VERSION "HINBNNNYYNNNYYNNNNNNNNNNNNYNNNYYYNNYNNNNNN/4//%%/4/'%**4NNN///"

NS_ :

BS_:

BU_: VirtualNMTMaster Master LadderDrive ControlPanel SupportFront SupportRear TTGateway

BO_ 1419 SSDO_011: 8 LadderDrive
 SG_ supported_drive_modes_6502 m0 : 32|32@1+ (1,0) [0|4294967295] "" Vector__XXX
 SG_ SubIndex_6502 m25858M : 24|8@1+ (1,0) [0|0] "" Vector__XXX
 SG_ motor_service_period_6407 m0 : 32|32@1+ (1,0) [0|4294967295] "" Vector__XXX
 SG_ SubIndex_6407 m25607M : 24|8@1+ (1,0) [0|0] "" Vector__XXX
 SG_ motor_type_6402 m0 : 32|16@1+ (1,0) [0|65535] "" Vector__XXX
 SG_ SubIndex_6402 m25602M : 24|8@1+ (1,0) [0|0] "" Vector__XXX
 SG_ target_velocity_60FF m0 : 32|32@1- (1,0) [-2147483648|2147483647] "" Vector__XXX
 SG_ SubIndex_60FF m24831M : 24|8@1+ (1,0) [0|0] "" Vector__XXX
 SG_ bitmask_60FE_02 m2 : 32|32@1+ (1,0) [0|4294967295] "" Vector__XXX
 SG_ physical_outputs_60FE_01 m1 : 32|32@1+ (1,0) [0|4294967295] "" Vector__XXX
 SG_ NrOfObjects_60FE_00 m0 : 32|8@1+ (1,0) [0|255] "" Vector__XXX
 SG_ SubIndex_60FE m24830M : 24|8@1+ (1,0) [0|2] "" Vector__XXX
 SG_ digital_inputs_60FD m0 : 32|32@1+ (1,0) [0|4294967295] "" Vector__XXX
 SG_ SubIndex_60FD m24829M : 24|8@1+ (1,0) [0|0] "" Vector__XXX
 SG_ polarity_607E m0 : 32|8@1+ (1,0) [0|255] "" Vector__XXX
 SG_ SubIndex_607E m24702M : 24|8@1+ (1,0) [0|0] "" Vector__XXX
 SG_ target_position_607A m0 : 32|32@1- (1,0) [-2147483648|2147483647] "" Vector__XXX
 SG_ SubIndex_607A m24698M : 24|8@1+ (1,0) [0|0] "" Vector__XXX
 SG_ torque_actual_value_6077 m0 : 32|16@1- (1,0) [-32768|32767] "" Vector__XXX
 SG_ SubIndex_6077 m24695M : 24|8@1+ (1,0) [0|0] "" Vector__XXX
 SG_ target_torque_6071 m0 : 32|16@1- (1,0) [-32768|32767] "" Vector__XXX
 SG_ SubIndex_6071 m24689M : 24|8@1+ (1,0) [0|0] "" Vector__XXX
 SG_ velocity_actual_value_606C m0 : 32|32@1- (1,0) [-2147483648|2147483647] "" Vector__XXX
 SG_ SubIndex_606C m24684M : 24|8@1+ (1,0) [0|0] "" Vector__XXX
 SG_ position_window_6067 m0 : 32|32@1+ (1,0) [0|4294967295] "" Vector__XXX
 SG_ SubIndex_6067 m24679M : 24|8@1+ (1,0) [0|0] "" Vector__XXX
 SG_ position_actual_value_6064 m0 : 32|32@1- (1,0) [-2147483648|2147483647] "" Vector__XXX
 SG_ SubIndex_6064 m24676M : 24|8@1+ (1,0) [0|0] "" Vector__XXX
 SG_ position_actual_value_6063 m0 : 32|32@1- (1,0) [-2147483648|2147483647] "" Vector__XXX
 SG_ SubIndex_6063 m24675M : 24|8@1+ (1,0) [0|0] "" Vector__XXX
 SG_ position_demand_value_6062 m0 : 32|32@1- (1,0) [-2147483648|2147483647] "" Vector__XXX
 SG_ SubIndex_6062 m24674M : 24|8@1+ (1,0) [0|0] "" Vector__XXX
 SG_ modes_of_operation_display_6061 m0 : 32|8@1- (1,0) [-128|127] "" Vector__XXX
 SG_ SubIndex_6061 m24673M : 24|8@1+ (1,0) [0|0] "" Vector__XXX
 SG_ modes_of_operation_6060 m0 : 32|8@1- (1,0) [-128|127] "" Vector__XXX
 SG_ SubIndex_6060 m24672M : 24|8@1+ (1,0) [0|0] "" Vector__XXX
 SG_ fault_reaction_option_code_605E m0 : 32|16@1- (1,0) [-32768|32767] "" Vector__XXX
 SG_ SubIndex_605E m24670M : 24|8@1+ (1,0) [0|0] "" Vector__XXX
 SG_ stop_option_code_605D m0 : 32|16@1- (1,0) [-32768|32767] "" Vector__XXX
 SG_ SubIndex_605D m24669M : 24|8@1+ (1,0) [0|0] "" Vector__XXX
 SG_ disable_operation_option_code_60 m0 : 32|16@1- (1,0) [-32768|32767] "" Vector__XXX
 SG_ SubIndex_605C m24668M : 24|8@1+ (1,0) [0|0] "" Vector__XXX
 SG_ shutdown_option_code_605B m0 : 32|16@1- (1,0) [-32768|32767] "" Vector__XXX
 SG_ SubIndex_605B m24667M : 24|8@1+ (1,0) [0|0] "" Vector__XXX
 SG_ quick_stop_option_code_605A m0 : 32|16@1- (1,0) [-32768|32767] "" Vector__XXX
 SG_ SubIndex_605A m24666M : 24|8@1+ (1,0) [0|0] "" Vector__XXX
 SG_ delta_time_6049_02 m2 : 32|16@1+ (1,0) [0|65535] "" Vector__XXX
 SG_ delta_speed_6049_01 m1 : 32|32@1+ (1,0) [0|4294967295] "" Vector__XXX
 SG_ NrOfObjects_6049_00 m0 : 32|8@1+ (1,0) [0|255] "" Vector__XXX
 SG_ SubIndex_6049 m24649M : 24|8@1+ (1,0) [0|2] "" Vector__XXX
 SG_ delta_time_6048_02 m2 : 32|16@1+ (1,0) [0|65535] "" Vector__XXX
 SG_ delta_speed_6048_01 m1 : 32|32@1+ (1,0) [0|4294967295] "" Vector__XXX
 SG_ NrOfObjects_6048_00 m0 : 32|8@1+ (1,0) [0|255] "" Vector__XXX
 SG_ SubIndex_6048 m24648M : 24|8@1+ (1,0) [0|2] "" Vector__XXX
 SG_ vl_velocity_max_amount_6046_02 m2 : 32|32@1+ (1,0) [0|4294967295] "" Vector__XXX
 SG_ vl_velocity_min_amount_6046_01 m1 : 32|32@1+ (1,0) [0|4294967295] "" Vector__XXX
 SG_ vl_velocity_min_max_amount_highe m0 : 32|8@1+ (1,0) [0|255] "" Vector__XXX
 SG_ SubIndex_6046 m24646M : 24|8@1+ (1,0) [0|2] "" Vector__XXX
 SG_ vl_control_effort_6044 m0 : 32|16@1- (1,0) [-32768|32767] "" Vector__XXX
 SG_ SubIndex_6044 m24644M : 24|8@1+ (1,0) [0|0] "" Vector__XXX
 SG_ vl_velocity_demand_6043 m0 : 32|16@1- (1,0) [-32768|32767] "" Vector__XXX
 SG_ SubIndex_6043 m24643M : 24|8@1+ (1,0) [0|0] "" Vector__XXX
 SG_ vl_target_velocity_6042 m0 : 32|16@1- (1,0) [-32768|32767] "" Vector__XXX
 SG_ SubIndex_6042 m24642M : 24|8@1+ (1,0) [0|0] "" Vector__XXX
 SG_ statusword_6041 m0 : 32|16@1+ (1,0) [0|65535] "" Vector__XXX
 SG_ SubIndex_6041 m24641M : 24|8@1+ (1,0) [0|0] "" Vector__XXX
 SG_ controlword_6040 m0 : 32|16@1+ (1,0) [0|65535] "" Vector__XXX
 SG_ SubIndex_6040 m24640M : 24|8@1+ (1,0) [0|0] "" Vector__XXX
 SG_ error_code_603F m0 : 32|16@1+ (1,0) [0|65535] "" Vector__XXX
 SG_ SubIndex_603F m24639M : 24|8@1+ (1,0) [0|0] "" Vector__XXX
 SG_ abort_connection_option_code_600 m0 : 32|16@1- (1,0) [-32768|3] "" Vector__XXX
 SG_ SubIndex_6007 m24583M : 24|8@1+ (1,0) [0|0] "" Vector__XXX
 SG_ PDO_Mapping_Entry_1A06_08 m8 : 32|32@1+ (1,0) [0|4294967295] "" Vector__XXX
 SG_ PDO_Mapping_Entry_1A06_07 m7 : 32|32@1+ (1,0) [0|4294967295] "" Vector__XXX
 SG_ PDO_Mapping_Entry_1A06_06 m6 : 32|32@1+ (1,0) [0|4294967295] "" Vector__XXX
 SG_ PDO_Mapping_Entry_1A06_05 m5 : 32|32@1+ (1,0) [0|4294967295] "" Vector__XXX
 SG_ PDO_Mapping_Entry_1A06_04 m4 : 32|32@1+ (1,0) [0|4294967295] "" Vector__XXX
 SG_ PDO_Mapping_Entry_1A06_03 m3 : 32|32@1+ (1,0) [0|4294967295] "" Vector__XXX
 SG_ PDO_Mapping_Entry_1A06_02 m2 : 32|32@1+ (1,0) [0|4294967295] "" Vector__XXX
 SG_ PDO_Mapping_Entry_1A06_01 m1 : 32|32@1+ (1,0) [0|4294967295] "" Vector__XXX
 SG_ NrOfMappedObjects_1A06_00 m0 : 32|8@1+ (1,0) [0|8] "" Vector__XXX
 SG_ SubIndex_1A06 m6662M : 24|8@1+ (1,0) [0|8] "" Vector__XXX
 SG_ PDO_Mapping_Entry_1A05_08 m8 : 32|32@1+ (1,0) [0|4294967295] "" Vector__XXX
 SG_ PDO_Mapping_Entry_1A05_07 m7 : 32|32@1+ (1,0) [0|4294967295] "" Vector__XXX
 SG_ PDO_Mapping_Entry_1A05_06 m6 : 32|32@1+ (1,0) [0|4294967295] "" Vector__XXX
 SG_ PDO_Mapping_Entry_1A05_05 m5 : 32|32@1+ (1,0) [0|4294967295] "" Vector__XXX
 SG_ PDO_Mapping_Entry_1A05_04 m4 : 32|32@1+ (1,0) [0|4294967295] "" Vector__XXX
 SG_ PDO_Mapping_Entry_1A05_03 m3 : 32|32@1+ (1,0) [0|4294967295] "" Vector__XXX
 SG_ PDO_Mapping_Entry_1A05_02 m2 : 32|32@1+ (1,0) [0|4294967295] "" Vector__XXX
 SG_ PDO_Mapping_Entry_1A05_01 m1 : 32|32@1+ (1,0) [0|4294967295] "" Vector__XXX
 SG_ NrOfMappedObjects_1A05_00 m0 : 32|8@1+ (1,0) [0|8] "" Vector__XXX
 SG_ SubIndex_1A05 m6661M : 24|8@1+ (1,0) [0|8] "" Vector__XXX
 SG_ PDO_Mapping_Entry_1A04_08 m8 : 32|32@1+ (1,0) [0|4294967295] "" Vector__XXX
 SG_ PDO_Mapping_Entry_1A04_07 m7 : 32|32@1+ (1,0) [0|4294967295] "" Vector__XXX
 SG_ PDO_Mapping_Entry_1A04_06 m6 : 32|32@1+ (1,0) [0|4294967295] "" Vector__XXX
 SG_ PDO_Mapping_Entry_1A04_05 m5 : 32|32@1+ (1,0) [0|4294967295] "" Vector__XXX
 SG_ PDO_Mapping_Entry_1A04_04 m4 : 32|32@1+ (1,0) [0|4294967295] "" Vector__XXX
 SG_ PDO_Mapping_Entry_1A04_03 m3 : 32|32@1+ (1,0) [0|4294967295] "" Vector__XXX
 SG_ PDO_Mapping_Entry_1A04_02 m2 : 32|32@1+ (1,0) [0|4294967295] "" Vector__XXX
 SG_ PDO_Mapping_Entry_1A04_01 m1 : 32|32@1+ (1,0) [0|4294967295] "" Vector__XXX
 SG_ NrOfMappedObjects_1A04_00 m0 : 32|8@1+ (1,0) [0|8] "" Vector__XXX
 SG_ SubIndex_1A04 m6660M : 24|8@1+ (1,0) [0|8] "" Vector__XXX
 SG_ PDO_Mapping_Entry_1A03_08 m8 : 32|32@1+ (1,0) [0|4294967295] "" Vector__XXX
 SG_ PDO_Mapping_Entry_1A03_07 m7 : 32|32@1+ (1,0) [0|4294967295] "" Vector__XXX
 SG_ PDO_Mapping_Entry_1A03_06 m6 : 32|32@1+ (1,0) [0|4294967295] "" Vector__XXX
 SG_ PDO_Mapping_Entry_1A03_05 m5 : 32|32@1+ (1,0) [0|4294967295] "" Vector__XXX
 SG_ PDO_Mapping_Entry_1A03_04 m4 : 32|32@1+ (1,0) [0|4294967295] "" Vector__XXX
 SG_ PDO_Mapping_Entry_1A03_03 m3 : 32|32@1+ (1,0) [0|4294967295] "" Vector__XXX
 SG_ PDO_Mapping_Entry_1A03_02 m2 : 32|32@1+ (1,0) [0|4294967295] "" Vector__XXX
 SG_ PDO_Mapping_Entry_1A03_01 m1 : 32|32@1+ (1,0) [0|4294967295] "" Vector__XXX
 SG_ NrOfMappedObjects_1A03_00 m0 : 32|8@1+ (1,0) [0|8] "" Vector__XXX
 SG_ SubIndex_1A03 m6659M : 24|8@1+ (1,0) [0|8] "" Vector__XXX
 SG_ PDO_Mapping_Entry_1A02_08 m8 : 32|32@1+ (1,0) [0|4294967295] "" Vector__XXX
 SG_ PDO_Mapping_Entry_1A02_07 m7 : 32|32@1+ (1,0) [0|4294967295] "" Vector__XXX
 SG_ PDO_Mapping_Entry_1A02_06 m6 : 32|32@1+ (1,0) [0|4294967295] "" Vector__XXX
 SG_ PDO_Mapping_Entry_1A02_05 m5 : 32|32@1+ (1,0) [0|4294967295] "" Vector__XXX
 SG_ PDO_Mapping_Entry_1A02_04 m4 : 32|32@1+ (1,0) [0|4294967295] "" Vector__XXX
 SG_ PDO_Mapping_Entry_1A02_03 m3 : 32|32@1+ (1,0) [0|4294967295] "" Vector__XXX
 SG_ PDO_Mapping_Entry_1A02_02 m2 : 32|32@1+ (1,0) [0|4294967295] "" Vector__XXX
 SG_ PDO_Mapping_Entry_1A02_01 m1 : 32|32@1+ (1,0) [0|4294967295] "" Vector__XXX
 SG_ NrOfMappedObjects_1A02_00 m0 : 32|8@1+ (1,0) [0|8] "" Vector__XXX
 SG_ SubIndex_1A02 m6658M : 24|8@1+ (1,0) [0|8] "" Vector__XXX
 SG_ PDO_Mapping_Entry_1A01_08 m8 : 32|32@1+ (1,0) [0|4294967295] "" Vector__XXX
 SG_ PDO_Mapping_Entry_1A01_07 m7 : 32|32@1+ (1,0) [0|4294967295] "" Vector__XXX
 SG_ PDO_Mapping_Entry_1A01_06 m6 : 32|32@1+ (1,0) [0|4294967295] "" Vector__XXX
 SG_ PDO_Mapping_Entry_1A01_05 m5 : 32|32@1+ (1,0) [0|4294967295] "" Vector__XXX
 SG_ PDO_Mapping_Entry_1A01_04 m4 : 32|32@1+ (1,0) [0|4294967295] "" Vector__XXX
 SG_ PDO_Mapping_Entry_1A01_03 m3 : 32|32@1+ (1,0) [0|4294967295] "" Vector__XXX
 SG_ PDO_Mapping_Entry_1A01_02 m2 : 32|32@1+ (1,0) [0|4294967295] "" Vector__XXX
 SG_ PDO_Mapping_Entry_1A01_01 m1 : 32|32@1+ (1,0) [0|4294967295] "" Vector__XXX
 SG_ NrOfMappedObjects_1A01_00 m0 : 32|8@1+ (1,0) [0|8] "" Vector__XXX
 SG_ SubIndex_1A01 m6657M : 24|8@1+ (1,0) [0|8] "" Vector__XXX
 SG_ PDO_Mapping_Entry_1A00_08 m8 : 32|32@1+ (1,0) [0|4294967295] "" Vector__XXX
 SG_ PDO_Mapping_Entry_1A00_07 m7 : 32|32@1+ (1,0) [0|4294967295] "" Vector__XXX
 SG_ PDO_Mapping_Entry_1A00_06 m6 : 32|32@1+ (1,0) [0|4294967295] "" Vector__XXX
 SG_ PDO_Mapping_Entry_1A00_05 m5 : 32|32@1+ (1,0) [0|4294967295] "" Vector__XXX
 SG_ PDO_Mapping_Entry_1A00_04 m4 : 32|32@1+ (1,0) [0|4294967295] "" Vector__XXX
 SG_ PDO_Mapping_Entry_1A00_03 m3 : 32|32@1+ (1,0) [0|4294967295] "" Vector__XXX
 SG_ PDO_Mapping_Entry_1A00_02 m2 : 32|32@1+ (1,0) [0|4294967295] "" Vector__XXX
 SG_ mappedObj1_1A00_01 m1 : 32|32@1+ (1,0) [0|4294967295] "" Vector__XXX
 SG_ NrOfMappedObjects_1A00_00 m0 : 32|8@1+ (1,0) [0|8] "" Vector__XXX
 SG_ SubIndex_1A00 m6656M : 24|8@1+ (1,0) [0|8] "" Vector__XXX
 SG_ EventTimer_1806_05 m5 : 32|16@1+ (1,0) [0|65535] "" Vector__XXX
 SG_ TransmissionType_1806_02 m2 : 32|8@1+ (1,0) [0|255] "" Vector__XXX
 SG_ COB_ID_1806_01 m1 : 32|32@1+ (1,0) [128|4294967295] "" Vector__XXX
 SG_ NrOfEntries_1806_00 m0 : 32|8@1+ (1,0) [2|5] "" Vector__XXX
 SG_ SubIndex_1806 m6150M : 24|8@1+ (1,0) [0|5] "" Vector__XXX
 SG_ EventTimer_1805_05 m5 : 32|16@1+ (1,0) [0|65535] "" Vector__XXX
 SG_ TransmissionType_1805_02 m2 : 32|8@1+ (1,0) [0|255] "" Vector__XXX
 SG_ COB_ID_1805_01 m1 : 32|32@1+ (1,0) [128|4294967295] "" Vector__XXX
 SG_ NrOfEntries_1805_00 m0 : 32|8@1+ (1,0) [2|5] "" Vector__XXX
 SG_ SubIndex_1805 m6149M : 24|8@1+ (1,0) [0|5] "" Vector__XXX
 SG_ EventTimer_1804_05 m5 : 32|16@1+ (1,0) [0|65535] "" Vector__XXX
 SG_ TransmissionType_1804_02 m2 : 32|8@1+ (1,0) [0|255] "" Vector__XXX
 SG_ COB_ID_1804_01 m1 : 32|32@1+ (1,0) [128|4294967295] "" Vector__XXX
 SG_ NrOfEntries_1804_00 m0 : 32|8@1+ (1,0) [2|5] "" Vector__XXX
 SG_ SubIndex_1804 m6148M : 24|8@1+ (1,0) [0|5] "" Vector__XXX
 SG_ EventTimer_1803_05 m5 : 32|16@1+ (1,0) [0|65535] "" Vector__XXX
 SG_ TransmissionType_1803_02 m2 : 32|8@1+ (1,0) [0|255] "" Vector__XXX
 SG_ COB_ID_1803_01 m1 : 32|32@1+ (1,0) [128|4294967295] "" Vector__XXX
 SG_ NrOfEntries_1803_00 m0 : 32|8@1+ (1,0) [2|5] "" Vector__XXX
 SG_ SubIndex_1803 m6147M : 24|8@1+ (1,0) [0|5] "" Vector__XXX
 SG_ EventTimer_1802_05 m5 : 32|16@1+ (1,0) [0|65535] "" Vector__XXX
 SG_ TransmissionType_1802_02 m2 : 32|8@1+ (1,0) [0|255] "" Vector__XXX
 SG_ COB_ID_1802_01 m1 : 32|32@1+ (1,0) [128|4294967295] "" Vector__XXX
 SG_ NrOfEntries_1802_00 m0 : 32|8@1+ (1,0) [2|5] "" Vector__XXX
 SG_ SubIndex_1802 m6146M : 24|8@1+ (1,0) [0|5] "" Vector__XXX
 SG_ EventTimer_1801_05 m5 : 32|16@1+ (1,0) [0|65535] "" Vector__XXX
 SG_ TransmissionType_1801_02 m2 : 32|8@1+ (1,0) [0|255] "" Vector__XXX
 SG_ COB_ID_1801_01 m1 : 32|32@1+ (1,0) [128|4294967295] "" Vector__XXX
 SG_ NrOfEntries_1801_00 m0 : 32|8@1+ (1,0) [2|5] "" Vector__XXX
 SG_ SubIndex_1801 m6145M : 24|8@1+ (1,0) [0|5] "" Vector__XXX
 SG_ EventTimer_1800_05 m5 : 32|16@1+ (1,0) [0|65535] "" Vector__XXX
 SG_ TransmissionType_1800_02 m2 : 32|8@1+ (1,0) [0|255] "" Vector__XXX
 SG_ COB_ID_1800_01 m1 : 32|32@1+ (1,0) [128|4294967295] "" Vector__XXX
 SG_ NrOfEntries_1800_00 m0 : 32|8@1+ (1,0) [2|5] "" Vector__XXX
 SG_ SubIndex_1800 m6144M : 24|8@1+ (1,0) [0|5] "" Vector__XXX
 SG_ PDO_Mapping_Entry_1607_08 m8 : 32|32@1+ (1,0) [0|4294967295] "" Vector__XXX
 SG_ PDO_Mapping_Entry_1607_07 m7 : 32|32@1+ (1,0) [0|4294967295] "" Vector__XXX
 SG_ PDO_Mapping_Entry_1607_06 m6 : 32|32@1+ (1,0) [0|4294967295] "" Vector__XXX
 SG_ PDO_Mapping_Entry_1607_05 m5 : 32|32@1+ (1,0) [0|4294967295] "" Vector__XXX
 SG_ PDO_Mapping_Entry_1607_04 m4 : 32|32@1+ (1,0) [0|4294967295] "" Vector__XXX
 SG_ PDO_Mapping_Entry_1607_03 m3 : 32|32@1+ (1,0) [0|4294967295] "" Vector__XXX
 SG_ PDO_Mapping_Entry_1607_02 m2 : 32|32@1+ (1,0) [0|4294967295] "" Vector__XXX
 SG_ PDO_Mapping_Entry_1607_01 m1 : 32|32@1+ (1,0) [0|4294967295] "" Vector__XXX
 SG_ NrOfMappedObjects_1607_00 m0 : 32|8@1+ (1,0) [0|8] "" Vector__XXX
 SG_ SubIndex_1607 m5639M : 24|8@1+ (1,0) [0|8] "" Vector__XXX
 SG_ PDO_Mapping_Entry_1606_08 m8 : 32|32@1+ (1,0) [0|4294967295] "" Vector__XXX
 SG_ PDO_Mapping_Entry_1606_07 m7 : 32|32@1+ (1,0) [0|4294967295] "" Vector__XXX
 SG_ PDO_Mapping_Entry_1606_06 m6 : 32|32@1+ (1,0) [0|4294967295] "" Vector__XXX
 SG_ PDO_Mapping_Entry_1606_05 m5 : 32|32@1+ (1,0) [0|4294967295] "" Vector__XXX
 SG_ PDO_Mapping_Entry_1606_04 m4 : 32|32@1+ (1,0) [0|4294967295] "" Vector__XXX
 SG_ PDO_Mapping_Entry_1606_03 m3 : 32|32@1+ (1,0) [0|4294967295] "" Vector__XXX
 SG_ PDO_Mapping_Entry_1606_02 m2 : 32|32@1+ (1,0) [0|4294967295] "" Vector__XXX
 SG_ PDO_Mapping_Entry_1606_01 m1 : 32|32@1+ (1,0) [0|4294967295] "" Vector__XXX
 SG_ NrOfMappedObjects_1606_00 m0 : 32|8@1+ (1,0) [0|8] "" Vector__XXX
 SG_ SubIndex_1606 m5638M : 24|8@1+ (1,0) [0|8] "" Vector__XXX
 SG_ PDO_Mapping_Entry_1605_08 m8 : 32|32@1+ (1,0) [0|4294967295] "" Vector__XXX
 SG_ PDO_Mapping_Entry_1605_07 m7 : 32|32@1+ (1,0) [0|4294967295] "" Vector__XXX
 SG_ PDO_Mapping_Entry_1605_06 m6 : 32|32@1+ (1,0) [0|4294967295] "" Vector__XXX
 SG_ PDO_Mapping_Entry_1605_05 m5 : 32|32@1+ (1,0) [0|4294967295] "" Vector__XXX
 SG_ PDO_Mapping_Entry_1605_04 m4 : 32|32@1+ (1,0) [0|4294967295] "" Vector__XXX
 SG_ PDO_Mapping_Entry_1605_03 m3 : 32|32@1+ (1,0) [0|4294967295] "" Vector__XXX
 SG_ PDO_Mapping_Entry_1605_02 m2 : 32|32@1+ (1,0) [0|4294967295] "" Vector__XXX
 SG_ PDO_Mapping_Entry_1605_01 m1 : 32|32@1+ (1,0) [0|4294967295] "" Vector__XXX
 SG_ NrOfMappedObjects_1605_00 m0 : 32|8@1+ (1,0) [0|8] "" Vector__XXX
 SG_ SubIndex_1605 m5637M : 24|8@1+ (1,0) [0|8] "" Vector__XXX
 SG_ PDO_Mapping_Entry_1604_08 m8 : 32|32@1+ (1,0) [0|4294967295] "" Vector__XXX
 SG_ PDO_Mapping_Entry_1604_07 m7 : 32|32@1+ (1,0) [0|4294967295] "" Vector__XXX
 SG_ PDO_Mapping_Entry_1604_06 m6 : 32|32@1+ (1,0) [0|4294967295] "" Vector__XXX
 SG_ PDO_Mapping_Entry_1604_05 m5 : 32|32@1+ (1,0) [0|4294967295] "" Vector__XXX
 SG_ PDO_Mapping_Entry_1604_04 m4 : 32|32@1+ (1,0) [0|4294967295] "" Vector__XXX
 SG_ PDO_Mapping_Entry_1604_03 m3 : 32|32@1+ (1,0) [0|4294967295] "" Vector__XXX
 SG_ PDO_Mapping_Entry_1604_02 m2 : 32|32@1+ (1,0) [0|4294967295] "" Vector__XXX
 SG_ PDO_Mapping_Entry_1604_01 m1 : 32|32@1+ (1,0) [0|4294967295] "" Vector__XXX
 SG_ NrOfMappedObjects_1604_00 m0 : 32|8@1+ (1,0) [0|8] "" Vector__XXX
 SG_ SubIndex_1604 m5636M : 24|8@1+ (1,0) [0|8] "" Vector__XXX
 SG_ PDO_Mapping_Entry_1603_08 m8 : 32|32@1+ (1,0) [0|4294967295] "" Vector__XXX
 SG_ PDO_Mapping_Entry_1603_07 m7 : 32|32@1+ (1,0) [0|4294967295] "" Vector__XXX
 SG_ PDO_Mapping_Entry_1603_06 m6 : 32|32@1+ (1,0) [0|4294967295] "" Vector__XXX
 SG_ PDO_Mapping_Entry_1603_05 m5 : 32|32@1+ (1,0) [0|4294967295] "" Vector__XXX
 SG_ PDO_Mapping_Entry_1603_04 m4 : 32|32@1+ (1,0) [0|4294967295] "" Vector__XXX
 SG_ PDO_Mapping_Entry_1603_03 m3 : 32|32@1+ (1,0) [0|4294967295] "" Vector__XXX
 SG_ PDO_Mapping_Entry_1603_02 m2 : 32|32@1+ (1,0) [0|4294967295] "" Vector__XXX
 SG_ PDO_Mapping_Entry_1603_01 m1 : 32|32@1+ (1,0) [0|4294967295] "" Vector__XXX
 SG_ NrOfMappedObjects_1603_00 m0 : 32|8@1+ (1,0) [0|8] "" Vector__XXX
 SG_ SubIndex_1603 m5635M : 24|8@1+ (1,0) [0|8] "" Vector__XXX
 SG_ PDO_Mapping_Entry_1602_08 m8 : 32|32@1+ (1,0) [0|4294967295] "" Vector__XXX
 SG_ PDO_Mapping_Entry_1602_07 m7 : 32|32@1+ (1,0) [0|4294967295] "" Vector__XXX
 SG_ PDO_Mapping_Entry_1602_06 m6 : 32|32@1+ (1,0) [0|4294967295] "" Vector__XXX
 SG_ PDO_Mapping_Entry_1602_05 m5 : 32|32@1+ (1,0) [0|4294967295] "" Vector__XXX
 SG_ PDO_Mapping_Entry_1602_04 m4 : 32|32@1+ (1,0) [0|4294967295] "" Vector__XXX
 SG_ PDO_Mapping_Entry_1602_03 m3 : 32|32@1+ (1,0) [0|4294967295] "" Vector__XXX
 SG_ PDO_Mapping_Entry_1602_02 m2 : 32|32@1+ (1,0) [0|4294967295] "" Vector__XXX
 SG_ PDO_Mapping_Entry_1602_01 m1 : 32|32@1+ (1,0) [0|4294967295] "" Vector__XXX
 SG_ NrOfMappedObjects_1602_00 m0 : 32|8@1+ (1,0) [0|8] "" Vector__XXX
 SG_ SubIndex_1602 m5634M : 24|8@1+ (1,0) [0|8] "" Vector__XXX
 SG_ PDO_Mapping_Entry_1601_08 m8 : 32|32@1+ (1,0) [0|4294967295] "" Vector__XXX
 SG_ PDO_Mapping_Entry_1601_07 m7 : 32|32@1+ (1,0) [0|4294967295] "" Vector__XXX
 SG_ PDO_Mapping_Entry_1601_06 m6 : 32|32@1+ (1,0) [0|4294967295] "" Vector__XXX
 SG_ PDO_Mapping_Entry_1601_05 m5 : 32|32@1+ (1,0) [0|4294967295] "" Vector__XXX
 SG_ PDO_Mapping_Entry_1601_04 m4 : 32|32@1+ (1,0) [0|4294967295] "" Vector__XXX
 SG_ PDO_Mapping_Entry_1601_03 m3 : 32|32@1+ (1,0) [0|4294967295] "" Vector__XXX
 SG_ PDO_Mapping_Entry_1601_02 m2 : 32|32@1+ (1,0) [0|4294967295] "" Vector__XXX
 SG_ PDO_Mapping_Entry_1601_01 m1 : 32|32@1+ (1,0) [0|4294967295] "" Vector__XXX
 SG_ NrOfMappedObjects_1601_00 m0 : 32|8@1+ (1,0) [0|8] "" Vector__XXX
 SG_ SubIndex_1601 m5633M : 24|8@1+ (1,0) [0|8] "" Vector__XXX
 SG_ PDO_Mapping_Entry_1600_08 m8 : 32|32@1+ (1,0) [0|4294967295] "" Vector__XXX
 SG_ PDO_Mapping_Entry_1600_07 m7 : 32|32@1+ (1,0) [0|4294967295] "" Vector__XXX
 SG_ PDO_Mapping_Entry_1600_06 m6 : 32|32@1+ (1,0) [0|4294967295] "" Vector__XXX
 SG_ PDO_Mapping_Entry_1600_05 m5 : 32|32@1+ (1,0) [0|4294967295] "" Vector__XXX
 SG_ PDO_Mapping_Entry_1600_04 m4 : 32|32@1+ (1,0) [0|4294967295] "" Vector__XXX
 SG_ PDO_Mapping_Entry_1600_03 m3 : 32|32@1+ (1,0) [0|4294967295] "" Vector__XXX
 SG_ mappedObj2_1600_02 m2 : 32|32@1+ (1,0) [0|4294967295] "" Vector__XXX
 SG_ mappedObj1_1600_01 m1 : 32|32@1+ (1,0) [0|4294967295] "" Vector__XXX
 SG_ NrOfMappedObjects_1600_00 m0 : 32|8@1+ (1,0) [0|8] "" Vector__XXX
 SG_ SubIndex_1600 m5632M : 24|8@1+ (1,0) [0|8] "" Vector__XXX
 SG_ TransmissionType_1407_02 m2 : 32|8@1+ (1,0) [0|255] "" Vector__XXX
 SG_ COB_ID_1407_01 m1 : 32|32@1+ (1,0) [128|4294967295] "" Vector__XXX
 SG_ NrOfEntries_1407_00 m0 : 32|8@1+ (1,0) [2|5] "" Vector__XXX
 SG_ SubIndex_1407 m5127M : 24|8@1+ (1,0) [0|2] "" Vector__XXX
 SG_ TransmissionType_1406_02 m2 : 32|8@1+ (1,0) [0|255] "" Vector__XXX
 SG_ COB_ID_1406_01 m1 : 32|32@1+ (1,0) [128|4294967295] "" Vector__XXX
 SG_ NrOfEntries_1406_00 m0 : 32|8@1+ (1,0) [2|5] "" Vector__XXX
 SG_ SubIndex_1406 m5126M : 24|8@1+ (1,0) [0|2] "" Vector__XXX
 SG_ TransmissionType_1405_02 m2 : 32|8@1+ (1,0) [0|255] "" Vector__XXX
 SG_ COB_ID_1405_01 m1 : 32|32@1+ (1,0) [128|4294967295] "" Vector__XXX
 SG_ NrOfEntries_1405_00 m0 : 32|8@1+ (1,0) [2|5] "" Vector__XXX
 SG_ SubIndex_1405 m5125M : 24|8@1+ (1,0) [0|2] "" Vector__XXX
 SG_ TransmissionType_1404_02 m2 : 32|8@1+ (1,0) [0|255] "" Vector__XXX
 SG_ COB_ID_1404_01 m1 : 32|32@1+ (1,0) [128|4294967295] "" Vector__XXX
 SG_ NrOfEntries_1404_00 m0 : 32|8@1+ (1,0) [2|5] "" Vector__XXX
 SG_ SubIndex_1404 m5124M : 24|8@1+ (1,0) [0|2] "" Vector__XXX
 SG_ TransmissionType_1403_02 m2 : 32|8@1+ (1,0) [0|255] "" Vector__XXX
 SG_ COB_ID_1403_01 m1 : 32|32@1+ (1,0) [128|4294967295] "" Vector__XXX
 SG_ NrOfEntries_1403_00 m0 : 32|8@1+ (1,0) [2|5] "" Vector__XXX
 SG_ SubIndex_1403 m5123M : 24|8@1+ (1,0) [0|2] "" Vector__XXX
 SG_ TransmissionType_1402_02 m2 : 32|8@1+ (1,0) [0|255] "" Vector__XXX
 SG_ COB_ID_1402_01 m1 : 32|32@1+ (1,0) [128|4294967295] "" Vector__XXX
 SG_ NrOfEntries_1402_00 m0 : 32|8@1+ (1,0) [2|5] "" Vector__XXX
 SG_ SubIndex_1402 m5122M : 24|8@1+ (1,0) [0|2] "" Vector__XXX
 SG_ TransmissionType_1401_02 m2 : 32|8@1+ (1,0) [0|255] "" Vector__XXX
 SG_ COB_ID_1401_01 m1 : 32|32@1+ (1,0) [128|4294967295] "" Vector__XXX
 SG_ NrOfEntries_1401_00 m0 : 32|8@1+ (1,0) [2|5] "" Vector__XXX
 SG_ SubIndex_1401 m5121M : 24|8@1+ (1,0) [0|2] "" Vector__XXX
 SG_ TransmissionType_1400_02 m2 : 32|8@1+ (1,0) [0|255] "" Vector__XXX
 SG_ COB_ID_1400_01 m1 : 32|32@1+ (1,0) [128|4294967295] "" Vector__XXX
 SG_ NrOfEntries_1400_00 m0 : 32|8@1+ (1,0) [2|5] "" Vector__XXX
 SG_ SubIndex_1400 m5120M : 24|8@1+ (1,0) [0|2] "" Vector__XXX
 SG_ Serial_number_1018_04 m4 : 32|32@1+ (1,0) [0|4294967295] "" Vector__XXX
 SG_ Revision_number_1018_03 m3 : 32|32@1+ (1,0) [0|4294967295] "" Vector__XXX
 SG_ Product_Code_1018_02 m2 : 32|32@1+ (1,0) [0|4294967295] "" Vector__XXX
 SG_ Vendor_Id_1018_01 m1 : 32|32@1+ (1,0) [0|4294967295] "" Vector__XXX
 SG_ number_of_entries_1018_00 m0 : 32|8@1+ (1,0) [1|4] "" Vector__XXX
 SG_ SubIndex_1018 m4120M : 24|8@1+ (1,0) [0|4] "" Vector__XXX
 SG_ Producer_Heartbeat_Time_1017 m0 : 32|16@1+ (1,0) [0|65535] "" Vector__XXX
 SG_ SubIndex_1017 m4119M : 24|8@1+ (1,0) [0|0] "" Vector__XXX
 SG_ Consumer_Heartbeat_Time_1016_09 m9 : 32|32@1+ (1,0) [0|4294967295] "" Vector__XXX
 SG_ Consumer_Heartbeat_Time_1016_08 m8 : 32|32@1+ (1,0) [0|4294967295] "" Vector__XXX
 SG_ Consumer_Heartbeat_Time_1016_07 m7 : 32|32@1+ (1,0) [0|4294967295] "" Vector__XXX
 SG_ Consumer_Heartbeat_Time_1016_06 m6 : 32|32@1+ (1,0) [0|4294967295] "" Vector__XXX
 SG_ Consumer_Heartbeat_Time_1016_05 m5 : 32|32@1+ (1,0) [0|4294967295] "" Vector__XXX
 SG_ Consumer_Heartbeat_Time_1016_04 m4 : 32|32@1+ (1,0) [0|4294967295] "" Vector__XXX
 SG_ Consumer_Heartbeat_Time_1016_03 m3 : 32|32@1+ (1,0) [0|4294967295] "" Vector__XXX
 SG_ Consumer_Heartbeat_Time_1016_02 m2 : 32|32@1+ (1,0) [0|4294967295] "" Vector__XXX
 SG_ Consumer_Heartbeat_Time_1016_01 m1 : 32|32@1+ (1,0) [0|4294967295] "" Vector__XXX
 SG_ NrOfObjects_1016_00 m0 : 32|8@1+ (1,0) [0|255] "" Vector__XXX
 SG_ SubIndex_1016 m4118M : 24|8@1+ (1,0) [0|9] "" Vector__XXX
 SG_ Save_all_Parameters_1010_01 m1 : 32|32@1+ (1,0) [0|4294967295] "" Vector__XXX
 SG_ Number_of_Entries_1010_00 m0 : 32|8@1+ (1,0) [0|255] "" Vector__XXX
 SG_ SubIndex_1010 m4112M : 24|8@1+ (1,0) [0|1] "" Vector__XXX
 SG_ Life_Time_Factor_100D m0 : 32|8@1+ (1,0) [0|255] "" Vector__XXX
 SG_ SubIndex_100D m4109M : 24|8@1+ (1,0) [0|0] "" Vector__XXX
 SG_ Guard_Time_100C m0 : 32|16@1+ (1,0) [0|65535] "" Vector__XXX
 SG_ SubIndex_100C m4108M : 24|8@1+ (1,0) [0|0] "" Vector__XXX
 SG_ Sync_Window_Length_1007 m0 : 32|32@1+ (1,0) [0|4294967295] "" Vector__XXX
 SG_ SubIndex_1007 m4103M : 24|8@1+ (1,0) [0|0] "" Vector__XXX
 SG_ Communication_Cycle_Period_1006 m0 : 32|32@1+ (1,0) [0|4294967295] "" Vector__XXX
 SG_ SubIndex_1006 m4102M : 24|8@1+ (1,0) [0|0] "" Vector__XXX
 SG_ COB_ID_SYNC_1005 m0 : 32|32@1+ (1,0) [128|4294967295] "" Vector__XXX
 SG_ SubIndex_1005 m4101M : 24|8@1+ (1,0) [0|0] "" Vector__XXX
 SG_ Manufacturer_Status_Registe_0001 m0 : 32|32@1+ (1,0) [0|4294967295] "" Vector__XXX
 SG_ SubIndex_1002 m4098M : 24|8@1+ (1,0) [0|0] "" Vector__XXX
 SG_ Error_Register_1001 m0 : 32|8@1+ (1,0) [0|255] "" Vector__XXX
 SG_ SubIndex_1001 m4097M : 24|8@1+ (1,0) [0|0] "" Vector__XXX
 SG_ Device_Type_1000 m0 : 32|32@1+ (1,0) [0|4294967295] "" Vector__XXX
 SG_ SubIndex_1000 m4096M : 24|8@1+ (1,0) [0|0] "" Vector__XXX
 SG_ Index m1M : 8|16@1+ (1,0) [4096|25861] "" Vector__XXX
 SG_ TransferType m1M : 1|1@1+ (1,0) [0|1] "" Vector__XXX
 SG_ NotUsedBytes m1 : 2|2@1+ (1,0) [0|3] "" Vector__XXX
 SG_ SizeIndicator m1 : 0|1@1+ (1,0) [0|1] "" Vector__XXX
 SG_ SCS M : 5|3@1+ (1,0) [0|6] "" Vector__XXX

BO_ 1547 CSDO_011: 8 Vector__XXX
 SG_ supported_drive_modes_6502 m0 : 32|32@1+ (1,0) [0|4294967295] ""  LadderDrive
 SG_ SubIndex_6502 m25858M : 24|8@1+ (1,0) [0|0] ""  LadderDrive
 SG_ motor_service_period_6407 m0 : 32|32@1+ (1,0) [0|4294967295] ""  LadderDrive
 SG_ SubIndex_6407 m25607M : 24|8@1+ (1,0) [0|0] ""  LadderDrive
 SG_ motor_type_6402 m0 : 32|16@1+ (1,0) [0|65535] ""  LadderDrive
 SG_ SubIndex_6402 m25602M : 24|8@1+ (1,0) [0|0] ""  LadderDrive
 SG_ target_velocity_60FF m0 : 32|32@1- (1,0) [-2147483648|2147483647] ""  LadderDrive
 SG_ SubIndex_60FF m24831M : 24|8@1+ (1,0) [0|0] ""  LadderDrive
 SG_ bitmask_60FE_02 m2 : 32|32@1+ (1,0) [0|4294967295] ""  LadderDrive
 SG_ physical_outputs_60FE_01 m1 : 32|32@1+ (1,0) [0|4294967295] ""  LadderDrive
 SG_ NrOfObjects_60FE_00 m0 : 32|8@1+ (1,0) [0|255] ""  LadderDrive
 SG_ SubIndex_60FE m24830M : 24|8@1+ (1,0) [0|2] ""  LadderDrive
 SG_ digital_inputs_60FD m0 : 32|32@1+ (1,0) [0|4294967295] ""  LadderDrive
 SG_ SubIndex_60FD m24829M : 24|8@1+ (1,0) [0|0] ""  LadderDrive
 SG_ polarity_607E m0 : 32|8@1+ (1,0) [0|255] ""  LadderDrive
 SG_ SubIndex_607E m24702M : 24|8@1+ (1,0) [0|0] ""  LadderDrive
 SG_ target_position_607A m0 : 32|32@1- (1,0) [-2147483648|2147483647] ""  LadderDrive
 SG_ SubIndex_607A m24698M : 24|8@1+ (1,0) [0|0] ""  LadderDrive
 SG_ torque_actual_value_6077 m0 : 32|16@1- (1,0) [-32768|32767] ""  LadderDrive
 SG_ SubIndex_6077 m24695M : 24|8@1+ (1,0) [0|0] ""  LadderDrive
 SG_ target_torque_6071 m0 : 32|16@1- (1,0) [-32768|32767] ""  LadderDrive
 SG_ SubIndex_6071 m24689M : 24|8@1+ (1,0) [0|0] ""  LadderDrive
 SG_ velocity_actual_value_606C m0 : 32|32@1- (1,0) [-2147483648|2147483647] ""  LadderDrive
 SG_ SubIndex_606C m24684M : 24|8@1+ (1,0) [0|0] ""  LadderDrive
 SG_ position_window_6067 m0 : 32|32@1+ (1,0) [0|4294967295] ""  LadderDrive
 SG_ SubIndex_6067 m24679M : 24|8@1+ (1,0) [0|0] ""  LadderDrive
 SG_ position_actual_value_6064 m0 : 32|32@1- (1,0) [-2147483648|2147483647] ""  LadderDrive
 SG_ SubIndex_6064 m24676M : 24|8@1+ (1,0) [0|0] ""  LadderDrive
 SG_ position_actual_value_6063 m0 : 32|32@1- (1,0) [-2147483648|2147483647] ""  LadderDrive
 SG_ SubIndex_6063 m24675M : 24|8@1+ (1,0) [0|0] ""  LadderDrive
 SG_ position_demand_value_6062 m0 : 32|32@1- (1,0) [-2147483648|2147483647] ""  LadderDrive
 SG_ SubIndex_6062 m24674M : 24|8@1+ (1,0) [0|0] ""  LadderDrive
 SG_ modes_of_operation_display_6061 m0 : 32|8@1- (1,0) [-128|127] ""  LadderDrive
 SG_ SubIndex_6061 m24673M : 24|8@1+ (1,0) [0|0] ""  LadderDrive
 SG_ modes_of_operation_6060 m0 : 32|8@1- (1,0) [-128|127] ""  LadderDrive
 SG_ SubIndex_6060 m24672M : 24|8@1+ (1,0) [0|0] ""  LadderDrive
 SG_ fault_reaction_option_code_605E m0 : 32|16@1- (1,0) [-32768|32767] ""  LadderDrive
 SG_ SubIndex_605E m24670M : 24|8@1+ (1,0) [0|0] ""  LadderDrive
 SG_ stop_option_code_605D m0 : 32|16@1- (1,0) [-32768|32767] ""  LadderDrive
 SG_ SubIndex_605D m24669M : 24|8@1+ (1,0) [0|0] ""  LadderDrive
 SG_ disable_operation_option_co_0000 m0 : 32|16@1- (1,0) [-32768|32767] ""  LadderDrive
 SG_ SubIndex_605C m24668M : 24|8@1+ (1,0) [0|0] ""  LadderDrive
 SG_ shutdown_option_code_605B m0 : 32|16@1- (1,0) [-32768|32767] ""  LadderDrive
 SG_ SubIndex_605B m24667M : 24|8@1+ (1,0) [0|0] ""  LadderDrive
 SG_ quick_stop_option_code_605A m0 : 32|16@1- (1,0) [-32768|32767] ""  LadderDrive
 SG_ SubIndex_605A m24666M : 24|8@1+ (1,0) [0|0] ""  LadderDrive
 SG_ delta_time_6049_02 m2 : 32|16@1+ (1,0) [0|65535] ""  LadderDrive
 SG_ delta_speed_6049_01 m1 : 32|32@1+ (1,0) [0|4294967295] ""  LadderDrive
 SG_ NrOfObjects_6049_00 m0 : 32|8@1+ (1,0) [0|255] ""  LadderDrive
 SG_ SubIndex_6049 m24649M : 24|8@1+ (1,0) [0|2] ""  LadderDrive
 SG_ delta_time_6048_02 m2 : 32|16@1+ (1,0) [0|65535] ""  LadderDrive
 SG_ delta_speed_6048_01 m1 : 32|32@1+ (1,0) [0|4294967295] ""  LadderDrive
 SG_ NrOfObjects_6048_00 m0 : 32|8@1+ (1,0) [0|255] ""  LadderDrive
 SG_ SubIndex_6048 m24648M : 24|8@1+ (1,0) [0|2] ""  LadderDrive
 SG_ vl_velocity_max_amount_6046_02 m2 : 32|32@1+ (1,0) [0|4294967295] ""  LadderDrive
 SG_ vl_velocity_min_amount_6046_01 m1 : 32|32@1+ (1,0) [0|4294967295] ""  LadderDrive
 SG_ vl_velocity_min_max_amount__0000 m0 : 32|8@1+ (1,0) [0|255] ""  LadderDrive
 SG_ SubIndex_6046 m24646M : 24|8@1+ (1,0) [0|2] ""  LadderDrive
 SG_ vl_control_effort_6044 m0 : 32|16@1- (1,0) [-32768|32767] ""  LadderDrive
 SG_ SubIndex_6044 m24644M : 24|8@1+ (1,0) [0|0] ""  LadderDrive
 SG_ vl_velocity_demand_6043 m0 : 32|16@1- (1,0) [-32768|32767] ""  LadderDrive
 SG_ SubIndex_6043 m24643M : 24|8@1+ (1,0) [0|0] ""  LadderDrive
 SG_ vl_target_velocity_6042 m0 : 32|16@1- (1,0) [-32768|32767] ""  LadderDrive
 SG_ SubIndex_6042 m24642M : 24|8@1+ (1,0) [0|0] ""  LadderDrive
 SG_ statusword_6041 m0 : 32|16@1+ (1,0) [0|65535] ""  LadderDrive
 SG_ SubIndex_6041 m24641M : 24|8@1+ (1,0) [0|0] ""  LadderDrive
 SG_ controlword_6040 m0 : 32|16@1+ (1,0) [0|65535] ""  LadderDrive
 SG_ SubIndex_6040 m24640M : 24|8@1+ (1,0) [0|0] ""  LadderDrive
 SG_ error_code_603F m0 : 32|16@1+ (1,0) [0|65535] ""  LadderDrive
 SG_ SubIndex_603F m24639M : 24|8@1+ (1,0) [0|0] ""  LadderDrive
 SG_ abort_connection_option_cod_0000 m0 : 32|16@1- (1,0) [-32768|3] ""  LadderDrive
 SG_ SubIndex_6007 m24583M : 24|8@1+ (1,0) [0|0] ""  LadderDrive
 SG_ PDO_Mapping_Entry_1A06_08 m8 : 32|32@1+ (1,0) [0|4294967295] ""  LadderDrive
 SG_ PDO_Mapping_Entry_1A06_07 m7 : 32|32@1+ (1,0) [0|4294967295] ""  LadderDrive
 SG_ PDO_Mapping_Entry_1A06_06 m6 : 32|32@1+ (1,0) [0|4294967295] ""  LadderDrive
 SG_ PDO_Mapping_Entry_1A06_05 m5 : 32|32@1+ (1,0) [0|4294967295] ""  LadderDrive
 SG_ PDO_Mapping_Entry_1A06_04 m4 : 32|32@1+ (1,0) [0|4294967295] ""  LadderDrive
 SG_ PDO_Mapping_Entry_1A06_03 m3 : 32|32@1+ (1,0) [0|4294967295] ""  LadderDrive
 SG_ PDO_Mapping_Entry_1A06_02 m2 : 32|32@1+ (1,0) [0|4294967295] ""  LadderDrive
 SG_ PDO_Mapping_Entry_1A06_01 m1 : 32|32@1+ (1,0) [0|4294967295] ""  LadderDrive
 SG_ NrOfMappedObjects_1A06_00 m0 : 32|8@1+ (1,0) [0|8] ""  LadderDrive
 SG_ SubIndex_1A06 m6662M : 24|8@1+ (1,0) [0|8] ""  LadderDrive
 SG_ PDO_Mapping_Entry_1A05_08 m8 : 32|32@1+ (1,0) [0|4294967295] ""  LadderDrive
 SG_ PDO_Mapping_Entry_1A05_07 m7 : 32|32@1+ (1,0) [0|4294967295] ""  LadderDrive
 SG_ PDO_Mapping_Entry_1A05_06 m6 : 32|32@1+ (1,0) [0|4294967295] ""  LadderDrive
 SG_ PDO_Mapping_Entry_1A05_05 m5 : 32|32@1+ (1,0) [0|4294967295] ""  LadderDrive
 SG_ PDO_Mapping_Entry_1A05_04 m4 : 32|32@1+ (1,0) [0|4294967295] ""  LadderDrive
 SG_ PDO_Mapping_Entry_1A05_03 m3 : 32|32@1+ (1,0) [0|4294967295] ""  LadderDrive
 SG_ PDO_Mapping_Entry_1A05_02 m2 : 32|32@1+ (1,0) [0|4294967295] ""  LadderDrive
 SG_ PDO_Mapping_Entry_1A05_01 m1 : 32|32@1+ (1,0) [0|4294967295] ""  LadderDrive
 SG_ NrOfMappedObjects_1A05_00 m0 : 32|8@1+ (1,0) [0|8] ""  LadderDrive
 SG_ SubIndex_1A05 m6661M : 24|8@1+ (1,0) [0|8] ""  LadderDrive
 SG_ PDO_Mapping_Entry_1A04_08 m8 : 32|32@1+ (1,0) [0|4294967295] ""  LadderDrive
 SG_ PDO_Mapping_Entry_1A04_07 m7 : 32|32@1+ (1,0) [0|4294967295] ""  LadderDrive
 SG_ PDO_Mapping_Entry_1A04_06 m6 : 32|32@1+ (1,0) [0|4294967295] ""  LadderDrive
 SG_ PDO_Mapping_Entry_1A04_05 m5 : 32|32@1+ (1,0) [0|4294967295] ""  LadderDrive
 SG_ PDO_Mapping_Entry_1A04_04 m4 : 32|32@1+ (1,0) [0|4294967295] ""  LadderDrive
 SG_ PDO_Mapping_Entry_1A04_03 m3 : 32|32@1+ (1,0) [0|4294967295] ""  LadderDrive
 SG_ PDO_Mapping_Entry_1A04_02 m2 : 32|32@1+ (1,0) [0|4294967295] ""  LadderDrive
 SG_ PDO_Mapping_Entry_1A04_01 m1 : 32|32@1+ (1,0) [0|4294967295] ""  LadderDrive
 SG_ NrOfMappedObjects_1A04_00 m0 : 32|8@1+ (1,0) [0|8] ""  LadderDrive
 SG_ SubIndex_1A04 m6660M : 24|8@1+ (1,0) [0|8] ""  LadderDrive
 SG_ PDO_Mapping_Entry_1A03_08 m8 : 32|32@1+ (1,0) [0|4294967295] ""  LadderDrive
 SG_ PDO_Mapping_Entry_1A03_07 m7 : 32|32@1+ (1,0) [0|4294967295] ""  LadderDrive
 SG_ PDO_Mapping_Entry_1A03_06 m6 : 32|32@1+ (1,0) [0|4294967295] ""  LadderDrive
 SG_ PDO_Mapping_Entry_1A03_05 m5 : 32|32@1+ (1,0) [0|4294967295] ""  LadderDrive
 SG_ PDO_Mapping_Entry_1A03_04 m4 : 32|32@1+ (1,0) [0|4294967295] ""  LadderDrive
 SG_ PDO_Mapping_Entry_1A03_03 m3 : 32|32@1+ (1,0) [0|4294967295] ""  LadderDrive
 SG_ PDO_Mapping_Entry_1A03_02 m2 : 32|32@1+ (1,0) [0|4294967295] ""  LadderDrive
 SG_ PDO_Mapping_Entry_1A03_01 m1 : 32|32@1+ (1,0) [0|4294967295] ""  LadderDrive
 SG_ NrOfMappedObjects_1A03_00 m0 : 32|8@1+ (1,0) [0|8] ""  LadderDrive
 SG_ SubIndex_1A03 m6659M : 24|8@1+ (1,0) [0|8] ""  LadderDrive
 SG_ PDO_Mapping_Entry_1A02_08 m8 : 32|32@1+ (1,0) [0|4294967295] ""  LadderDrive
 SG_ PDO_Mapping_Entry_1A02_07 m7 : 32|32@1+ (1,0) [0|4294967295] ""  LadderDrive
 SG_ PDO_Mapping_Entry_1A02_06 m6 : 32|32@1+ (1,0) [0|4294967295] ""  LadderDrive
 SG_ PDO_Mapping_Entry_1A02_05 m5 : 32|32@1+ (1,0) [0|4294967295] ""  LadderDrive
 SG_ PDO_Mapping_Entry_1A02_04 m4 : 32|32@1+ (1,0) [0|4294967295] ""  LadderDrive
 SG_ PDO_Mapping_Entry_1A02_03 m3 : 32|32@1+ (1,0) [0|4294967295] ""  LadderDrive
 SG_ PDO_Mapping_Entry_1A02_02 m2 : 32|32@1+ (1,0) [0|4294967295] ""  LadderDrive
 SG_ PDO_Mapping_Entry_1A02_01 m1 : 32|32@1+ (1,0) [0|4294967295] ""  LadderDrive
 SG_ NrOfMappedObjects_1A02_00 m0 : 32|8@1+ (1,0) [0|8] ""  LadderDrive
 SG_ SubIndex_1A02 m6658M : 24|8@1+ (1,0) [0|8] ""  LadderDrive
 SG_ PDO_Mapping_Entry_1A01_08 m8 : 32|32@1+ (1,0) [0|4294967295] ""  LadderDrive
 SG_ PDO_Mapping_Entry_1A01_07 m7 : 32|32@1+ (1,0) [0|4294967295] ""  LadderDrive
 SG_ PDO_Mapping_Entry_1A01_06 m6 : 32|32@1+ (1,0) [0|4294967295] ""  LadderDrive
 SG_ PDO_Mapping_Entry_1A01_05 m5 : 32|32@1+ (1,0) [0|4294967295] ""  LadderDrive
 SG_ PDO_Mapping_Entry_1A01_04 m4 : 32|32@1+ (1,0) [0|4294967295] ""  LadderDrive
 SG_ PDO_Mapping_Entry_1A01_03 m3 : 32|32@1+ (1,0) [0|4294967295] ""  LadderDrive
 SG_ PDO_Mapping_Entry_1A01_02 m2 : 32|32@1+ (1,0) [0|4294967295] ""  LadderDrive
 SG_ PDO_Mapping_Entry_1A01_01 m1 : 32|32@1+ (1,0) [0|4294967295] ""  LadderDrive
 SG_ NrOfMappedObjects_1A01_00 m0 : 32|8@1+ (1,0) [0|8] ""  LadderDrive
 SG_ SubIndex_1A01 m6657M : 24|8@1+ (1,0) [0|8] ""  LadderDrive
 SG_ PDO_Mapping_Entry_1A00_08 m8 : 32|32@1+ (1,0) [0|4294967295] ""  LadderDrive
 SG_ PDO_Mapping_Entry_1A00_07 m7 : 32|32@1+ (1,0) [0|4294967295] ""  LadderDrive
 SG_ PDO_Mapping_Entry_1A00_06 m6 : 32|32@1+ (1,0) [0|4294967295] ""  LadderDrive
 SG_ PDO_Mapping_Entry_1A00_05 m5 : 32|32@1+ (1,0) [0|4294967295] ""  LadderDrive
 SG_ PDO_Mapping_Entry_1A00_04 m4 : 32|32@1+ (1,0) [0|4294967295] ""  LadderDrive
 SG_ PDO_Mapping_Entry_1A00_03 m3 : 32|32@1+ (1,0) [0|4294967295] ""  LadderDrive
 SG_ PDO_Mapping_Entry_1A00_02 m2 : 32|32@1+ (1,0) [0|4294967295] ""  LadderDrive
 SG_ mappedObj1_1A00_01 m1 : 32|32@1+ (1,0) [0|4294967295] ""  LadderDrive
 SG_ NrOfMappedObjects_1A00_00 m0 : 32|8@1+ (1,0) [0|8] ""  LadderDrive
 SG_ SubIndex_1A00 m6656M : 24|8@1+ (1,0) [0|8] ""  LadderDrive
 SG_ EventTimer_1806_05 m5 : 32|16@1+ (1,0) [0|65535] ""  LadderDrive
 SG_ TransmissionType_1806_02 m2 : 32|8@1+ (1,0) [0|255] ""  LadderDrive
 SG_ COB_ID_1806_01 m1 : 32|32@1+ (1,0) [128|4294967295] ""  LadderDrive
 SG_ NrOfEntries_1806_00 m0 : 32|8@1+ (1,0) [2|5] ""  LadderDrive
 SG_ SubIndex_1806 m6150M : 24|8@1+ (1,0) [0|5] ""  LadderDrive
 SG_ EventTimer_1805_05 m5 : 32|16@1+ (1,0) [0|65535] ""  LadderDrive
 SG_ TransmissionType_1805_02 m2 : 32|8@1+ (1,0) [0|255] ""  LadderDrive
 SG_ COB_ID_1805_01 m1 : 32|32@1+ (1,0) [128|4294967295] ""  LadderDrive
 SG_ NrOfEntries_1805_00 m0 : 32|8@1+ (1,0) [2|5] ""  LadderDrive
 SG_ SubIndex_1805 m6149M : 24|8@1+ (1,0) [0|5] ""  LadderDrive
 SG_ EventTimer_1804_05 m5 : 32|16@1+ (1,0) [0|65535] ""  LadderDrive
 SG_ TransmissionType_1804_02 m2 : 32|8@1+ (1,0) [0|255] ""  LadderDrive
 SG_ COB_ID_1804_01 m1 : 32|32@1+ (1,0) [128|4294967295] ""  LadderDrive
 SG_ NrOfEntries_1804_00 m0 : 32|8@1+ (1,0) [2|5] ""  LadderDrive
 SG_ SubIndex_1804 m6148M : 24|8@1+ (1,0) [0|5] ""  LadderDrive
 SG_ EventTimer_1803_05 m5 : 32|16@1+ (1,0) [0|65535] ""  LadderDrive
 SG_ TransmissionType_1803_02 m2 : 32|8@1+ (1,0) [0|255] ""  LadderDrive
 SG_ COB_ID_1803_01 m1 : 32|32@1+ (1,0) [128|4294967295] ""  LadderDrive
 SG_ NrOfEntries_1803_00 m0 : 32|8@1+ (1,0) [2|5] ""  LadderDrive
 SG_ SubIndex_1803 m6147M : 24|8@1+ (1,0) [0|5] ""  LadderDrive
 SG_ EventTimer_1802_05 m5 : 32|16@1+ (1,0) [0|65535] ""  LadderDrive
 SG_ TransmissionType_1802_02 m2 : 32|8@1+ (1,0) [0|255] ""  LadderDrive
 SG_ COB_ID_1802_01 m1 : 32|32@1+ (1,0) [128|4294967295] ""  LadderDrive
 SG_ NrOfEntries_1802_00 m0 : 32|8@1+ (1,0) [2|5] ""  LadderDrive
 SG_ SubIndex_1802 m6146M : 24|8@1+ (1,0) [0|5] ""  LadderDrive
 SG_ EventTimer_1801_05 m5 : 32|16@1+ (1,0) [0|65535] ""  LadderDrive
 SG_ TransmissionType_1801_02 m2 : 32|8@1+ (1,0) [0|255] ""  LadderDrive
 SG_ COB_ID_1801_01 m1 : 32|32@1+ (1,0) [128|4294967295] ""  LadderDrive
 SG_ NrOfEntries_1801_00 m0 : 32|8@1+ (1,0) [2|5] ""  LadderDrive
 SG_ SubIndex_1801 m6145M : 24|8@1+ (1,0) [0|5] ""  LadderDrive
 SG_ EventTimer_1800_05 m5 : 32|16@1+ (1,0) [0|65535] ""  LadderDrive
 SG_ TransmissionType_1800_02 m2 : 32|8@1+ (1,0) [0|255] ""  LadderDrive
 SG_ COB_ID_1800_01 m1 : 32|32@1+ (1,0) [128|4294967295] ""  LadderDrive
 SG_ NrOfEntries_1800_00 m0 : 32|8@1+ (1,0) [2|5] ""  LadderDrive
 SG_ SubIndex_1800 m6144M : 24|8@1+ (1,0) [0|5] ""  LadderDrive
 SG_ PDO_Mapping_Entry_1607_08 m8 : 32|32@1+ (1,0) [0|4294967295] ""  LadderDrive
 SG_ PDO_Mapping_Entry_1607_07 m7 : 32|32@1+ (1,0) [0|4294967295] ""  LadderDrive
 SG_ PDO_Mapping_Entry_1607_06 m6 : 32|32@1+ (1,0) [0|4294967295] ""  LadderDrive
 SG_ PDO_Mapping_Entry_1607_05 m5 : 32|32@1+ (1,0) [0|4294967295] ""  LadderDrive
 SG_ PDO_Mapping_Entry_1607_04 m4 : 32|32@1+ (1,0) [0|4294967295] ""  LadderDrive
 SG_ PDO_Mapping_Entry_1607_03 m3 : 32|32@1+ (1,0) [0|4294967295] ""  LadderDrive
 SG_ PDO_Mapping_Entry_1607_02 m2 : 32|32@1+ (1,0) [0|4294967295] ""  LadderDrive
 SG_ PDO_Mapping_Entry_1607_01 m1 : 32|32@1+ (1,0) [0|4294967295] ""  LadderDrive
 SG_ NrOfMappedObjects_1607_00 m0 : 32|8@1+ (1,0) [0|8] ""  LadderDrive
 SG_ SubIndex_1607 m5639M : 24|8@1+ (1,0) [0|8] ""  LadderDrive
 SG_ PDO_Mapping_Entry_1606_08 m8 : 32|32@1+ (1,0) [0|4294967295] ""  LadderDrive
 SG_ PDO_Mapping_Entry_1606_07 m7 : 32|32@1+ (1,0) [0|4294967295] ""  LadderDrive
 SG_ PDO_Mapping_Entry_1606_06 m6 : 32|32@1+ (1,0) [0|4294967295] ""  LadderDrive
 SG_ PDO_Mapping_Entry_1606_05 m5 : 32|32@1+ (1,0) [0|4294967295] ""  LadderDrive
 SG_ PDO_Mapping_Entry_1606_04 m4 : 32|32@1+ (1,0) [0|4294967295] ""  LadderDrive
 SG_ PDO_Mapping_Entry_1606_03 m3 : 32|32@1+ (1,0) [0|4294967295] ""  LadderDrive
 SG_ PDO_Mapping_Entry_1606_02 m2 : 32|32@1+ (1,0) [0|4294967295] ""  LadderDrive
 SG_ PDO_Mapping_Entry_1606_01 m1 : 32|32@1+ (1,0) [0|4294967295] ""  LadderDrive
 SG_ NrOfMappedObjects_1606_00 m0 : 32|8@1+ (1,0) [0|8] ""  LadderDrive
 SG_ SubIndex_1606 m5638M : 24|8@1+ (1,0) [0|8] ""  LadderDrive
 SG_ PDO_Mapping_Entry_1605_08 m8 : 32|32@1+ (1,0) [0|4294967295] ""  LadderDrive
 SG_ PDO_Mapping_Entry_1605_07 m7 : 32|32@1+ (1,0) [0|4294967295] ""  LadderDrive
 SG_ PDO_Mapping_Entry_1605_06 m6 : 32|32@1+ (1,0) [0|4294967295] ""  LadderDrive
 SG_ PDO_Mapping_Entry_1605_05 m5 : 32|32@1+ (1,0) [0|4294967295] ""  LadderDrive
 SG_ PDO_Mapping_Entry_1605_04 m4 : 32|32@1+ (1,0) [0|4294967295] ""  LadderDrive
 SG_ PDO_Mapping_Entry_1605_03 m3 : 32|32@1+ (1,0) [0|4294967295] ""  LadderDrive
 SG_ PDO_Mapping_Entry_1605_02 m2 : 32|32@1+ (1,0) [0|4294967295] ""  LadderDrive
 SG_ PDO_Mapping_Entry_1605_01 m1 : 32|32@1+ (1,0) [0|4294967295] ""  LadderDrive
 SG_ NrOfMappedObjects_1605_00 m0 : 32|8@1+ (1,0) [0|8] ""  LadderDrive
 SG_ SubIndex_1605 m5637M : 24|8@1+ (1,0) [0|8] ""  LadderDrive
 SG_ PDO_Mapping_Entry_1604_08 m8 : 32|32@1+ (1,0) [0|4294967295] ""  LadderDrive
 SG_ PDO_Mapping_Entry_1604_07 m7 : 32|32@1+ (1,0) [0|4294967295] ""  LadderDrive
 SG_ PDO_Mapping_Entry_1604_06 m6 : 32|32@1+ (1,0) [0|4294967295] ""  LadderDrive
 SG_ PDO_Mapping_Entry_1604_05 m5 : 32|32@1+ (1,0) [0|4294967295] ""  LadderDrive
 SG_ PDO_Mapping_Entry_1604_04 m4 : 32|32@1+ (1,0) [0|4294967295] ""  LadderDrive
 SG_ PDO_Mapping_Entry_1604_03 m3 : 32|32@1+ (1,0) [0|4294967295] ""  LadderDrive
 SG_ PDO_Mapping_Entry_1604_02 m2 : 32|32@1+ (1,0) [0|4294967295] ""  LadderDrive
 SG_ PDO_Mapping_Entry_1604_01 m1 : 32|32@1+ (1,0) [0|4294967295] ""  LadderDrive
 SG_ NrOfMappedObjects_1604_00 m0 : 32|8@1+ (1,0) [0|8] ""  LadderDrive
 SG_ SubIndex_1604 m5636M : 24|8@1+ (1,0) [0|8] ""  LadderDrive
 SG_ PDO_Mapping_Entry_1603_08 m8 : 32|32@1+ (1,0) [0|4294967295] ""  LadderDrive
 SG_ PDO_Mapping_Entry_1603_07 m7 : 32|32@1+ (1,0) [0|4294967295] ""  LadderDrive
 SG_ PDO_Mapping_Entry_1603_06 m6 : 32|32@1+ (1,0) [0|4294967295] ""  LadderDrive
 SG_ PDO_Mapping_Entry_1603_05 m5 : 32|32@1+ (1,0) [0|4294967295] ""  LadderDrive
 SG_ PDO_Mapping_Entry_1603_04 m4 : 32|32@1+ (1,0) [0|4294967295] ""  LadderDrive
 SG_ PDO_Mapping_Entry_1603_03 m3 : 32|32@1+ (1,0) [0|4294967295] ""  LadderDrive
 SG_ PDO_Mapping_Entry_1603_02 m2 : 32|32@1+ (1,0) [0|4294967295] ""  LadderDrive
 SG_ PDO_Mapping_Entry_1603_01 m1 : 32|32@1+ (1,0) [0|4294967295] ""  LadderDrive
 SG_ NrOfMappedObjects_1603_00 m0 : 32|8@1+ (1,0) [0|8] ""  LadderDrive
 SG_ SubIndex_1603 m5635M : 24|8@1+ (1,0) [0|8] ""  LadderDrive
 SG_ PDO_Mapping_Entry_1602_08 m8 : 32|32@1+ (1,0) [0|4294967295] ""  LadderDrive
 SG_ PDO_Mapping_Entry_1602_07 m7 : 32|32@1+ (1,0) [0|4294967295] ""  LadderDrive
 SG_ PDO_Mapping_Entry_1602_06 m6 : 32|32@1+ (1,0) [0|4294967295] ""  LadderDrive
 SG_ PDO_Mapping_Entry_1602_05 m5 : 32|32@1+ (1,0) [0|4294967295] ""  LadderDrive
 SG_ PDO_Mapping_Entry_1602_04 m4 : 32|32@1+ (1,0) [0|4294967295] ""  LadderDrive
 SG_ PDO_Mapping_Entry_1602_03 m3 : 32|32@1+ (1,0) [0|4294967295] ""  LadderDrive
 SG_ PDO_Mapping_Entry_1602_02 m2 : 32|32@1+ (1,0) [0|4294967295] ""  LadderDrive
 SG_ PDO_Mapping_Entry_1602_01 m1 : 32|32@1+ (1,0) [0|4294967295] ""  LadderDrive
 SG_ NrOfMappedObjects_1602_00 m0 : 32|8@1+ (1,0) [0|8] ""  LadderDrive
 SG_ SubIndex_1602 m5634M : 24|8@1+ (1,0) [0|8] ""  LadderDrive
 SG_ PDO_Mapping_Entry_1601_08 m8 : 32|32@1+ (1,0) [0|4294967295] ""  LadderDrive
 SG_ PDO_Mapping_Entry_1601_07 m7 : 32|32@1+ (1,0) [0|4294967295] ""  LadderDrive
 SG_ PDO_Mapping_Entry_1601_06 m6 : 32|32@1+ (1,0) [0|4294967295] ""  LadderDrive
 SG_ PDO_Mapping_Entry_1601_05 m5 : 32|32@1+ (1,0) [0|4294967295] ""  LadderDrive
 SG_ PDO_Mapping_Entry_1601_04 m4 : 32|32@1+ (1,0) [0|4294967295] ""  LadderDrive
 SG_ PDO_Mapping_Entry_1601_03 m3 : 32|32@1+ (1,0) [0|4294967295] ""  LadderDrive
 SG_ PDO_Mapping_Entry_1601_02 m2 : 32|32@1+ (1,0) [0|4294967295] ""  LadderDrive
 SG_ PDO_Mapping_Entry_1601_01 m1 : 32|32@1+ (1,0) [0|4294967295] ""  LadderDrive
 SG_ NrOfMappedObjects_1601_00 m0 : 32|8@1+ (1,0) [0|8] ""  LadderDrive
 SG_ SubIndex_1601 m5633M : 24|8@1+ (1,0) [0|8] ""  LadderDrive
 SG_ PDO_Mapping_Entry_1600_08 m8 : 32|32@1+ (1,0) [0|4294967295] ""  LadderDrive
 SG_ PDO_Mapping_Entry_1600_07 m7 : 32|32@1+ (1,0) [0|4294967295] ""  LadderDrive
 SG_ PDO_Mapping_Entry_1600_06 m6 : 32|32@1+ (1,0) [0|4294967295] ""  LadderDrive
 SG_ PDO_Mapping_Entry_1600_05 m5 : 32|32@1+ (1,0) [0|4294967295] ""  LadderDrive
 SG_ PDO_Mapping_Entry_1600_04 m4 : 32|32@1+ (1,0) [0|4294967295] ""  LadderDrive
 SG_ PDO_Mapping_Entry_1600_03 m3 : 32|32@1+ (1,0) [0|4294967295] ""  LadderDrive
 SG_ mappedObj2_1600_02 m2 : 32|32@1+ (1,0) [0|4294967295] ""  LadderDrive
 SG_ mappedObj1_1600_01 m1 : 32|32@1+ (1,0) [0|4294967295] ""  LadderDrive
 SG_ NrOfMappedObjects_1600_00 m0 : 32|8@1+ (1,0) [0|8] ""  LadderDrive
 SG_ SubIndex_1600 m5632M : 24|8@1+ (1,0) [0|8] ""  LadderDrive
 SG_ TransmissionType_1407_02 m2 : 32|8@1+ (1,0) [0|255] ""  LadderDrive
 SG_ COB_ID_1407_01 m1 : 32|32@1+ (1,0) [128|4294967295] ""  LadderDrive
 SG_ NrOfEntries_1407_00 m0 : 32|8@1+ (1,0) [2|5] ""  LadderDrive
 SG_ SubIndex_1407 m5127M : 24|8@1+ (1,0) [0|2] ""  LadderDrive
 SG_ TransmissionType_1406_02 m2 : 32|8@1+ (1,0) [0|255] ""  LadderDrive
 SG_ COB_ID_1406_01 m1 : 32|32@1+ (1,0) [128|4294967295] ""  LadderDrive
 SG_ NrOfEntries_1406_00 m0 : 32|8@1+ (1,0) [2|5] ""  LadderDrive
 SG_ SubIndex_1406 m5126M : 24|8@1+ (1,0) [0|2] ""  LadderDrive
 SG_ TransmissionType_1405_02 m2 : 32|8@1+ (1,0) [0|255] ""  LadderDrive
 SG_ COB_ID_1405_01 m1 : 32|32@1+ (1,0) [128|4294967295] ""  LadderDrive
 SG_ NrOfEntries_1405_00 m0 : 32|8@1+ (1,0) [2|5] ""  LadderDrive
 SG_ SubIndex_1405 m5125M : 24|8@1+ (1,0) [0|2] ""  LadderDrive
 SG_ TransmissionType_1404_02 m2 : 32|8@1+ (1,0) [0|255] ""  LadderDrive
 SG_ COB_ID_1404_01 m1 : 32|32@1+ (1,0) [128|4294967295] ""  LadderDrive
 SG_ NrOfEntries_1404_00 m0 : 32|8@1+ (1,0) [2|5] ""  LadderDrive
 SG_ SubIndex_1404 m5124M : 24|8@1+ (1,0) [0|2] ""  LadderDrive
 SG_ TransmissionType_1403_02 m2 : 32|8@1+ (1,0) [0|255] ""  LadderDrive
 SG_ COB_ID_1403_01 m1 : 32|32@1+ (1,0) [128|4294967295] ""  LadderDrive
 SG_ NrOfEntries_1403_00 m0 : 32|8@1+ (1,0) [2|5] ""  LadderDrive
 SG_ SubIndex_1403 m5123M : 24|8@1+ (1,0) [0|2] ""  LadderDrive
 SG_ TransmissionType_1402_02 m2 : 32|8@1+ (1,0) [0|255] ""  LadderDrive
 SG_ COB_ID_1402_01 m1 : 32|32@1+ (1,0) [128|4294967295] ""  LadderDrive
 SG_ NrOfEntries_1402_00 m0 : 32|8@1+ (1,0) [2|5] ""  LadderDrive
 SG_ SubIndex_1402 m5122M : 24|8@1+ (1,0) [0|2] ""  LadderDrive
 SG_ TransmissionType_1401_02 m2 : 32|8@1+ (1,0) [0|255] ""  LadderDrive
 SG_ COB_ID_1401_01 m1 : 32|32@1+ (1,0) [128|4294967295] ""  LadderDrive
 SG_ NrOfEntries_1401_00 m0 : 32|8@1+ (1,0) [2|5] ""  LadderDrive
 SG_ SubIndex_1401 m5121M : 24|8@1+ (1,0) [0|2] ""  LadderDrive
 SG_ TransmissionType_1400_02 m2 : 32|8@1+ (1,0) [0|255] ""  LadderDrive
 SG_ COB_ID_1400_01 m1 : 32|32@1+ (1,0) [128|4294967295] ""  LadderDrive
 SG_ NrOfEntries_1400_00 m0 : 32|8@1+ (1,0) [2|5] ""  LadderDrive
 SG_ SubIndex_1400 m5120M : 24|8@1+ (1,0) [0|2] ""  LadderDrive
 SG_ Serial_number_1018_04 m4 : 32|32@1+ (1,0) [0|4294967295] ""  LadderDrive
 SG_ Revision_number_1018_03 m3 : 32|32@1+ (1,0) [0|4294967295] ""  LadderDrive
 SG_ Product_Code_1018_02 m2 : 32|32@1+ (1,0) [0|4294967295] ""  LadderDrive
 SG_ Vendor_Id_1018_01 m1 : 32|32@1+ (1,0) [0|4294967295] ""  LadderDrive
 SG_ number_of_entries_1018_00 m0 : 32|8@1+ (1,0) [1|4] ""  LadderDrive
 SG_ SubIndex_1018 m4120M : 24|8@1+ (1,0) [0|4] ""  LadderDrive
 SG_ Producer_Heartbeat_Time_1017 m0 : 32|16@1+ (1,0) [0|65535] ""  LadderDrive
 SG_ SubIndex_1017 m4119M : 24|8@1+ (1,0) [0|0] ""  LadderDrive
 SG_ Consumer_Heartbeat_Time_1016_09 m9 : 32|32@1+ (1,0) [0|4294967295] ""  LadderDrive
 SG_ Consumer_Heartbeat_Time_1016_08 m8 : 32|32@1+ (1,0) [0|4294967295] ""  LadderDrive
 SG_ Consumer_Heartbeat_Time_1016_07 m7 : 32|32@1+ (1,0) [0|4294967295] ""  LadderDrive
 SG_ Consumer_Heartbeat_Time_1016_06 m6 : 32|32@1+ (1,0) [0|4294967295] ""  LadderDrive
 SG_ Consumer_Heartbeat_Time_1016_05 m5 : 32|32@1+ (1,0) [0|4294967295] ""  LadderDrive
 SG_ Consumer_Heartbeat_Time_1016_04 m4 : 32|32@1+ (1,0) [0|4294967295] ""  LadderDrive
 SG_ Consumer_Heartbeat_Time_1016_03 m3 : 32|32@1+ (1,0) [0|4294967295] ""  LadderDrive
 SG_ Consumer_Heartbeat_Time_1016_02 m2 : 32|32@1+ (1,0) [0|4294967295] ""  LadderDrive
 SG_ Consumer_Heartbeat_Time_1016_01 m1 : 32|32@1+ (1,0) [0|4294967295] ""  LadderDrive
 SG_ NrOfObjects_1016_00 m0 : 32|8@1+ (1,0) [0|255] ""  LadderDrive
 SG_ SubIndex_1016 m4118M : 24|8@1+ (1,0) [0|9] ""  LadderDrive
 SG_ Save_all_Parameters_1010_01 m1 : 32|32@1+ (1,0) [0|4294967295] ""  LadderDrive
 SG_ Number_of_Entries_1010_00 m0 : 32|8@1+ (1,0) [0|255] ""  LadderDrive
 SG_ SubIndex_1010 m4112M : 24|8@1+ (1,0) [0|1] ""  LadderDrive
 SG_ Life_Time_Factor_100D m0 : 32|8@1+ (1,0) [0|255] ""  LadderDrive
 SG_ SubIndex_100D m4109M : 24|8@1+ (1,0) [0|0] ""  LadderDrive
 SG_ Guard_Time_100C m0 : 32|16@1+ (1,0) [0|65535] ""  LadderDrive
 SG_ SubIndex_100C m4108M : 24|8@1+ (1,0) [0|0] ""  LadderDrive
 SG_ Sync_Window_Length_1007 m0 : 32|32@1+ (1,0) [0|4294967295] ""  LadderDrive
 SG_ SubIndex_1007 m4103M : 24|8@1+ (1,0) [0|0] ""  LadderDrive
 SG_ Communication_Cycle_Period_1006 m0 : 32|32@1+ (1,0) [0|4294967295] ""  LadderDrive
 SG_ SubIndex_1006 m4102M : 24|8@1+ (1,0) [0|0] ""  LadderDrive
 SG_ COB_ID_SYNC_1005 m0 : 32|32@1+ (1,0) [128|4294967295] ""  LadderDrive
 SG_ SubIndex_1005 m4101M : 24|8@1+ (1,0) [0|0] ""  LadderDrive
 SG_ Manufacturer_Status_Registe_0002 m0 : 32|32@1+ (1,0) [0|4294967295] ""  LadderDrive
 SG_ SubIndex_1002 m4098M : 24|8@1+ (1,0) [0|0] ""  LadderDrive
 SG_ Error_Register_1001 m0 : 32|8@1+ (1,0) [0|255] ""  LadderDrive
 SG_ SubIndex_1001 m4097M : 24|8@1+ (1,0) [0|0] ""  LadderDrive
 SG_ Device_Type_1000 m0 : 32|32@1+ (1,0) [0|4294967295] ""  LadderDrive
 SG_ SubIndex_1000 m4096M : 24|8@1+ (1,0) [0|0] ""  LadderDrive
 SG_ Index m1M : 8|16@1+ (1,0) [4096|25861] ""  LadderDrive
 SG_ TransferType m1M : 1|1@1+ (1,0) [0|1] ""  LadderDrive
 SG_ NotUsedBytes m1 : 2|2@1+ (1,0) [0|3] ""  LadderDrive
 SG_ SizeIndicator m1 : 0|1@1+ (1,0) [0|1] ""  LadderDrive
 SG_ CCS M : 5|3@1+ (1,0) [0|6] ""  LadderDrive

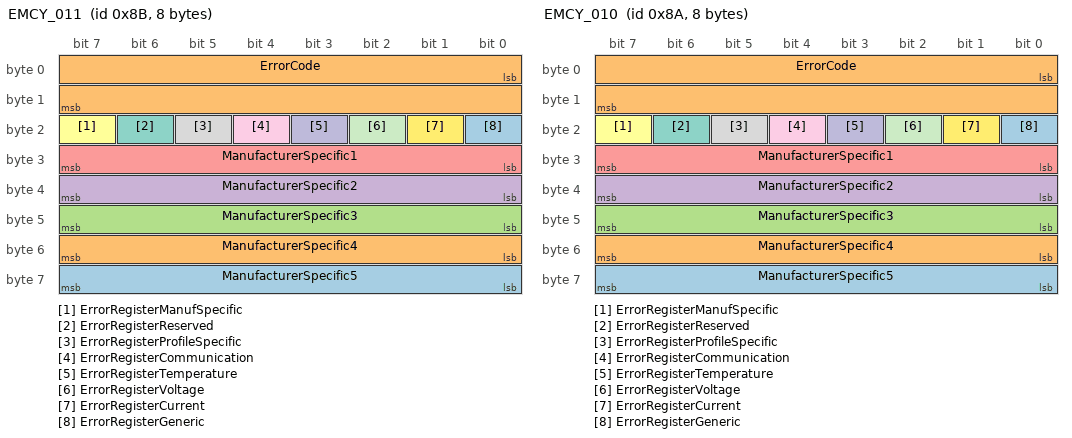
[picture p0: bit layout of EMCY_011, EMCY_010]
BO_ 139 EMCY_011: 8 LadderDrive
 SG_ ManufacturerSpecific5 : 56|8@1+ (1,0) [0|0] "" Vector__XXX
 SG_ ManufacturerSpecific4 : 48|8@1+ (1,0) [0|0] "" Vector__XXX
 SG_ ManufacturerSpecific3 : 40|8@1+ (1,0) [0|0] "" Vector__XXX
 SG_ ManufacturerSpecific2 : 32|8@1+ (1,0) [0|0] "" Vector__XXX
 SG_ ManufacturerSpecific1 : 24|8@1+ (1,0) [0|0] "" Vector__XXX
 SG_ ErrorRegisterManufSpecific : 23|1@1+ (1,0) [0|0] "" Vector__XXX
 SG_ ErrorRegisterReserved : 22|1@1+ (1,0) [0|0] "" Vector__XXX
 SG_ ErrorRegisterProfileSpecific : 21|1@1+ (1,0) [0|0] "" Vector__XXX
 SG_ ErrorRegisterCommunication : 20|1@1+ (1,0) [0|0] "" Vector__XXX
 SG_ ErrorRegisterTemperature : 19|1@1+ (1,0) [0|0] "" Vector__XXX
 SG_ ErrorRegisterVoltage : 18|1@1+ (1,0) [0|0] "" Vector__XXX
 SG_ ErrorRegisterCurrent : 17|1@1+ (1,0) [0|0] "" Vector__XXX
 SG_ ErrorRegisterGeneric : 16|1@1+ (1,0) [0|0] "" Vector__XXX
 SG_ ErrorCode : 0|16@1+ (1,0) [0|0] "" Vector__XXX

BO_ 1802 HBGuard_010: 1 ControlPanel
 SG_ Toggle : 7|1@1+ (1,0) [0|0] "" Vector__XXX
 SG_ State : 0|7@1+ (1,0) [0|0] "" Vector__XXX

BO_ 1418 SSDO_010: 8 ControlPanel
 SG_ DigOutput8_8_6200_08 m8 : 32|8@1+ (1,0) [0|255] "" Vector__XXX
 SG_ DigOutput8_7_6200_07 m7 : 32|8@1+ (1,0) [0|255] "" Vector__XXX
 SG_ DigOutput8_6_6200_06 m6 : 32|8@1+ (1,0) [0|255] "" Vector__XXX
 SG_ DigOutput8_5_6200_05 m5 : 32|8@1+ (1,0) [0|255] "" Vector__XXX
 SG_ DigOutput8_4_6200_04 m4 : 32|8@1+ (1,0) [0|255] "" Vector__XXX
 SG_ DigOutput8_3_6200_03 m3 : 32|8@1+ (1,0) [0|255] "" Vector__XXX
 SG_ DigOutput8_2_6200_02 m2 : 32|8@1+ (1,0) [0|255] "" Vector__XXX
 SG_ LadderLock_6200_01 m1 : 32|8@1+ (1,0) [0|255] "" Vector__XXX
 SG_ NrOfObjects_6200_00 m0 : 32|8@1+ (1,0) [0|255] "" Vector__XXX
 SG_ SubIndex_6200 m25088M : 24|8@1+ (1,0) [0|8] "" Vector__XXX
 SG_ DigInput8_8_6000_08 m8 : 32|8@1+ (1,0) [0|255] "" Vector__XXX
 SG_ DigInput8_7_6000_07 m7 : 32|8@1+ (1,0) [0|255] "" Vector__XXX
 SG_ DigInput8_6_6000_06 m6 : 32|8@1+ (1,0) [0|255] "" Vector__XXX
 SG_ DigInput8_5_6000_05 m5 : 32|8@1+ (1,0) [0|255] "" Vector__XXX
 SG_ Support_Down_6000_04 m4 : 32|8@1+ (1,0) [0|255] "" Vector__XXX
 SG_ Support_Up_6000_03 m3 : 32|8@1+ (1,0) [0|255] "" Vector__XXX
 SG_ Ladder_Down_6000_02 m2 : 32|8@1+ (1,0) [0|255] "" Vector__XXX
 SG_ Ladder_Up_6000_01 m1 : 32|8@1+ (1,0) [0|255] "" Vector__XXX
 SG_ NrOfObjects_6000_00 m0 : 32|8@1+ (1,0) [0|255] "" Vector__XXX
 SG_ SubIndex_6000 m24576M : 24|8@1+ (1,0) [0|8] "" Vector__XXX
 SG_ NrOfMappedObjects_1A01_00 m0 : 32|8@1+ (1,0) [0|8] "" Vector__XXX
 SG_ SubIndex_1A01 m6657M : 24|8@1+ (1,0) [0|0] "" Vector__XXX
 SG_ mappedObj5_1A00_05 m5 : 32|32@1+ (1,0) [0|4294967295] "" Vector__XXX
 SG_ mappedObj4_1A00_04 m4 : 32|32@1+ (1,0) [0|4294967295] "" Vector__XXX
 SG_ mappedObj3_1A00_03 m3 : 32|32@1+ (1,0) [0|4294967295] "" Vector__XXX
 SG_ mappedObj2_1A00_02 m2 : 32|32@1+ (1,0) [0|4294967295] "" Vector__XXX
 SG_ mappedObj1_1A00_01 m1 : 32|32@1+ (1,0) [0|4294967295] "" Vector__XXX
 SG_ NrOfMappedObjects_1A00_00 m0 : 32|8@1+ (1,0) [0|8] "" Vector__XXX
 SG_ SubIndex_1A00 m6656M : 24|8@1+ (1,0) [0|5] "" Vector__XXX
 SG_ EventTimer_1801_05 m5 : 32|16@1+ (1,0) [0|65535] "" Vector__XXX
 SG_ TransmissionType_1801_02 m2 : 32|8@1+ (1,0) [0|255] "" Vector__XXX
 SG_ COB_ID_1801_01 m1 : 32|32@1+ (1,0) [128|4294967295] "" Vector__XXX
 SG_ NrOfEntries_1801_00 m0 : 32|8@1+ (1,0) [2|5] "" Vector__XXX
 SG_ SubIndex_1801 m6145M : 24|8@1+ (1,0) [0|5] "" Vector__XXX
 SG_ EventTimer_1800_05 m5 : 32|16@1+ (1,0) [0|65535] "" Vector__XXX
 SG_ TransmissionType_1800_02 m2 : 32|8@1+ (1,0) [0|255] "" Vector__XXX
 SG_ COB_ID_1800_01 m1 : 32|32@1+ (1,0) [128|4294967295] "" Vector__XXX
 SG_ NrOfEntries_1800_00 m0 : 32|8@1+ (1,0) [2|5] "" Vector__XXX
 SG_ SubIndex_1800 m6144M : 24|8@1+ (1,0) [0|5] "" Vector__XXX
 SG_ NrOfMappedObjects_1601_00 m0 : 32|8@1+ (1,0) [0|8] "" Vector__XXX
 SG_ SubIndex_1601 m5633M : 24|8@1+ (1,0) [0|0] "" Vector__XXX
 SG_ NrOfMappedObjects_1600_00 m0 : 32|8@1+ (1,0) [0|8] "" Vector__XXX
 SG_ SubIndex_1600 m5632M : 24|8@1+ (1,0) [0|0] "" Vector__XXX
 SG_ TransmissionType_1401_02 m2 : 32|8@1+ (1,0) [0|255] "" Vector__XXX
 SG_ COB_ID_1401_01 m1 : 32|32@1+ (1,0) [128|4294967295] "" Vector__XXX
 SG_ NrOfEntries_1401_00 m0 : 32|8@1+ (1,0) [2|5] "" Vector__XXX
 SG_ SubIndex_1401 m5121M : 24|8@1+ (1,0) [0|2] "" Vector__XXX
 SG_ TransmissionType_1400_02 m2 : 32|8@1+ (1,0) [0|255] "" Vector__XXX
 SG_ COB_ID_1400_01 m1 : 32|32@1+ (1,0) [128|4294967295] "" Vector__XXX
 SG_ NrOfEntries_1400_00 m0 : 32|8@1+ (1,0) [2|5] "" Vector__XXX
 SG_ SubIndex_1400 m5120M : 24|8@1+ (1,0) [0|2] "" Vector__XXX
 SG_ Serial_number_1018_04 m4 : 32|32@1+ (1,0) [0|4294967295] "" Vector__XXX
 SG_ Revision_number_1018_03 m3 : 32|32@1+ (1,0) [0|4294967295] "" Vector__XXX
 SG_ Product_Code_1018_02 m2 : 32|32@1+ (1,0) [0|4294967295] "" Vector__XXX
 SG_ Vendor_Id_1018_01 m1 : 32|32@1+ (1,0) [0|4294967295] "" Vector__XXX
 SG_ number_of_entries_1018_00 m0 : 32|8@1+ (1,0) [1|4] "" Vector__XXX
 SG_ SubIndex_1018 m4120M : 24|8@1+ (1,0) [0|4] "" Vector__XXX
 SG_ Producer_Heartbeat_Time_1017 m0 : 32|16@1+ (1,0) [0|65535] "" Vector__XXX
 SG_ SubIndex_1017 m4119M : 24|8@1+ (1,0) [0|0] "" Vector__XXX
 SG_ Consumer_Heartbeat_Time_1016_06 m6 : 32|32@1+ (1,0) [0|4294967295] "" Vector__XXX
 SG_ Consumer_Heartbeat_Time_1016_05 m5 : 32|32@1+ (1,0) [0|4294967295] "" Vector__XXX
 SG_ Consumer_Heartbeat_Time_1016_04 m4 : 32|32@1+ (1,0) [0|4294967295] "" Vector__XXX
 SG_ Consumer_Heartbeat_Time_1016_03 m3 : 32|32@1+ (1,0) [0|4294967295] "" Vector__XXX
 SG_ Consumer_Heartbeat_Time_1016_02 m2 : 32|32@1+ (1,0) [0|4294967295] "" Vector__XXX
 SG_ Consumer_Heartbeat_Time_1016_01 m1 : 32|32@1+ (1,0) [0|4294967295] "" Vector__XXX
 SG_ NrOfObjects_1016_00 m0 : 32|8@1+ (1,0) [0|255] "" Vector__XXX
 SG_ SubIndex_1016 m4118M : 24|8@1+ (1,0) [0|6] "" Vector__XXX
 SG_ Save_all_Parameters_1010_01 m1 : 32|32@1+ (1,0) [0|4294967295] "" Vector__XXX
 SG_ Number_of_Entries_1010_00 m0 : 32|8@1+ (1,0) [0|255] "" Vector__XXX
 SG_ SubIndex_1010 m4112M : 24|8@1+ (1,0) [0|1] "" Vector__XXX
 SG_ Life_Time_Factor_100D m0 : 32|8@1+ (1,0) [0|255] "" Vector__XXX
 SG_ SubIndex_100D m4109M : 24|8@1+ (1,0) [0|0] "" Vector__XXX
 SG_ Guard_Time_100C m0 : 32|16@1+ (1,0) [0|65535] "" Vector__XXX
 SG_ SubIndex_100C m4108M : 24|8@1+ (1,0) [0|0] "" Vector__XXX
 SG_ Sync_Window_Length_1007 m0 : 32|32@1+ (1,0) [0|4294967295] "" Vector__XXX
 SG_ SubIndex_1007 m4103M : 24|8@1+ (1,0) [0|0] "" Vector__XXX
 SG_ Communication_Cycle_Period_1006 m0 : 32|32@1+ (1,0) [0|4294967295] "" Vector__XXX
 SG_ SubIndex_1006 m4102M : 24|8@1+ (1,0) [0|0] "" Vector__XXX
 SG_ COB_ID_SYNC_1005 m0 : 32|32@1+ (1,0) [128|4294967295] "" Vector__XXX
 SG_ SubIndex_1005 m4101M : 24|8@1+ (1,0) [0|0] "" Vector__XXX
 SG_ Manufacturer_Status_Registe_0003 m0 : 32|32@1+ (1,0) [0|4294967295] "" Vector__XXX
 SG_ SubIndex_1002 m4098M : 24|8@1+ (1,0) [0|0] "" Vector__XXX
 SG_ Error_Register_1001 m0 : 32|8@1+ (1,0) [0|255] "" Vector__XXX
 SG_ SubIndex_1001 m4097M : 24|8@1+ (1,0) [0|0] "" Vector__XXX
 SG_ Device_Type_1000 m0 : 32|32@1+ (1,0) [0|4294967295] "" Vector__XXX
 SG_ SubIndex_1000 m4096M : 24|8@1+ (1,0) [0|0] "" Vector__XXX
 SG_ Index m1M : 8|16@1+ (1,0) [4096|25088] "" Vector__XXX
 SG_ TransferType m1M : 1|1@1+ (1,0) [0|1] "" Vector__XXX
 SG_ NotUsedBytes m1 : 2|2@1+ (1,0) [0|3] "" Vector__XXX
 SG_ SizeIndicator m1 : 0|1@1+ (1,0) [0|1] "" Vector__XXX
 SG_ SCS M : 5|3@1+ (1,0) [0|6] "" Vector__XXX

BO_ 1546 CSDO_010: 8 Vector__XXX
 SG_ DigOutput8_8_6200_08 m8 : 32|8@1+ (1,0) [0|255] ""  ControlPanel
 SG_ DigOutput8_7_6200_07 m7 : 32|8@1+ (1,0) [0|255] ""  ControlPanel
 SG_ DigOutput8_6_6200_06 m6 : 32|8@1+ (1,0) [0|255] ""  ControlPanel
 SG_ DigOutput8_5_6200_05 m5 : 32|8@1+ (1,0) [0|255] ""  ControlPanel
 SG_ DigOutput8_4_6200_04 m4 : 32|8@1+ (1,0) [0|255] ""  ControlPanel
 SG_ DigOutput8_3_6200_03 m3 : 32|8@1+ (1,0) [0|255] ""  ControlPanel
 SG_ DigOutput8_2_6200_02 m2 : 32|8@1+ (1,0) [0|255] ""  ControlPanel
 SG_ LadderLock_6200_01 m1 : 32|8@1+ (1,0) [0|255] ""  ControlPanel
 SG_ NrOfObjects_6200_00 m0 : 32|8@1+ (1,0) [0|255] ""  ControlPanel
 SG_ SubIndex_6200 m25088M : 24|8@1+ (1,0) [0|8] ""  ControlPanel
 SG_ DigInput8_8_6000_08 m8 : 32|8@1+ (1,0) [0|255] ""  ControlPanel
 SG_ DigInput8_7_6000_07 m7 : 32|8@1+ (1,0) [0|255] ""  ControlPanel
 SG_ DigInput8_6_6000_06 m6 : 32|8@1+ (1,0) [0|255] ""  ControlPanel
 SG_ DigInput8_5_6000_05 m5 : 32|8@1+ (1,0) [0|255] ""  ControlPanel
 SG_ Support_Down_6000_04 m4 : 32|8@1+ (1,0) [0|255] ""  ControlPanel
 SG_ Support_Up_6000_03 m3 : 32|8@1+ (1,0) [0|255] ""  ControlPanel
 SG_ Ladder_Down_6000_02 m2 : 32|8@1+ (1,0) [0|255] ""  ControlPanel
 SG_ Ladder_Up_6000_01 m1 : 32|8@1+ (1,0) [0|255] ""  ControlPanel
 SG_ NrOfObjects_6000_00 m0 : 32|8@1+ (1,0) [0|255] ""  ControlPanel
 SG_ SubIndex_6000 m24576M : 24|8@1+ (1,0) [0|8] ""  ControlPanel
 SG_ NrOfMappedObjects_1A01_00 m0 : 32|8@1+ (1,0) [0|8] ""  ControlPanel
 SG_ SubIndex_1A01 m6657M : 24|8@1+ (1,0) [0|0] ""  ControlPanel
 SG_ mappedObj5_1A00_05 m5 : 32|32@1+ (1,0) [0|4294967295] ""  ControlPanel
 SG_ mappedObj4_1A00_04 m4 : 32|32@1+ (1,0) [0|4294967295] ""  ControlPanel
 SG_ mappedObj3_1A00_03 m3 : 32|32@1+ (1,0) [0|4294967295] ""  ControlPanel
 SG_ mappedObj2_1A00_02 m2 : 32|32@1+ (1,0) [0|4294967295] ""  ControlPanel
 SG_ mappedObj1_1A00_01 m1 : 32|32@1+ (1,0) [0|4294967295] ""  ControlPanel
 SG_ NrOfMappedObjects_1A00_00 m0 : 32|8@1+ (1,0) [0|8] ""  ControlPanel
 SG_ SubIndex_1A00 m6656M : 24|8@1+ (1,0) [0|5] ""  ControlPanel
 SG_ EventTimer_1801_05 m5 : 32|16@1+ (1,0) [0|65535] ""  ControlPanel
 SG_ TransmissionType_1801_02 m2 : 32|8@1+ (1,0) [0|255] ""  ControlPanel
 SG_ COB_ID_1801_01 m1 : 32|32@1+ (1,0) [128|4294967295] ""  ControlPanel
 SG_ NrOfEntries_1801_00 m0 : 32|8@1+ (1,0) [2|5] ""  ControlPanel
 SG_ SubIndex_1801 m6145M : 24|8@1+ (1,0) [0|5] ""  ControlPanel
 SG_ EventTimer_1800_05 m5 : 32|16@1+ (1,0) [0|65535] ""  ControlPanel
 SG_ TransmissionType_1800_02 m2 : 32|8@1+ (1,0) [0|255] ""  ControlPanel
 SG_ COB_ID_1800_01 m1 : 32|32@1+ (1,0) [128|4294967295] ""  ControlPanel
 SG_ NrOfEntries_1800_00 m0 : 32|8@1+ (1,0) [2|5] ""  ControlPanel
 SG_ SubIndex_1800 m6144M : 24|8@1+ (1,0) [0|5] ""  ControlPanel
 SG_ NrOfMappedObjects_1601_00 m0 : 32|8@1+ (1,0) [0|8] ""  ControlPanel
 SG_ SubIndex_1601 m5633M : 24|8@1+ (1,0) [0|0] ""  ControlPanel
 SG_ NrOfMappedObjects_1600_00 m0 : 32|8@1+ (1,0) [0|8] ""  ControlPanel
 SG_ SubIndex_1600 m5632M : 24|8@1+ (1,0) [0|0] ""  ControlPanel
 SG_ TransmissionType_1401_02 m2 : 32|8@1+ (1,0) [0|255] ""  ControlPanel
 SG_ COB_ID_1401_01 m1 : 32|32@1+ (1,0) [128|4294967295] ""  ControlPanel
 SG_ NrOfEntries_1401_00 m0 : 32|8@1+ (1,0) [2|5] ""  ControlPanel
 SG_ SubIndex_1401 m5121M : 24|8@1+ (1,0) [0|2] ""  ControlPanel
 SG_ TransmissionType_1400_02 m2 : 32|8@1+ (1,0) [0|255] ""  ControlPanel
 SG_ COB_ID_1400_01 m1 : 32|32@1+ (1,0) [128|4294967295] ""  ControlPanel
 SG_ NrOfEntries_1400_00 m0 : 32|8@1+ (1,0) [2|5] ""  ControlPanel
 SG_ SubIndex_1400 m5120M : 24|8@1+ (1,0) [0|2] ""  ControlPanel
 SG_ Serial_number_1018_04 m4 : 32|32@1+ (1,0) [0|4294967295] ""  ControlPanel
 SG_ Revision_number_1018_03 m3 : 32|32@1+ (1,0) [0|4294967295] ""  ControlPanel
 SG_ Product_Code_1018_02 m2 : 32|32@1+ (1,0) [0|4294967295] ""  ControlPanel
 SG_ Vendor_Id_1018_01 m1 : 32|32@1+ (1,0) [0|4294967295] ""  ControlPanel
 SG_ number_of_entries_1018_00 m0 : 32|8@1+ (1,0) [1|4] ""  ControlPanel
 SG_ SubIndex_1018 m4120M : 24|8@1+ (1,0) [0|4] ""  ControlPanel
 SG_ Producer_Heartbeat_Time_1017 m0 : 32|16@1+ (1,0) [0|65535] ""  ControlPanel
 SG_ SubIndex_1017 m4119M : 24|8@1+ (1,0) [0|0] ""  ControlPanel
 SG_ Consumer_Heartbeat_Time_1016_06 m6 : 32|32@1+ (1,0) [0|4294967295] ""  ControlPanel
 SG_ Consumer_Heartbeat_Time_1016_05 m5 : 32|32@1+ (1,0) [0|4294967295] ""  ControlPanel
 SG_ Consumer_Heartbeat_Time_1016_04 m4 : 32|32@1+ (1,0) [0|4294967295] ""  ControlPanel
 SG_ Consumer_Heartbeat_Time_1016_03 m3 : 32|32@1+ (1,0) [0|4294967295] ""  ControlPanel
 SG_ Consumer_Heartbeat_Time_1016_02 m2 : 32|32@1+ (1,0) [0|4294967295] ""  ControlPanel
 SG_ Consumer_Heartbeat_Time_1016_01 m1 : 32|32@1+ (1,0) [0|4294967295] ""  ControlPanel
 SG_ NrOfObjects_1016_00 m0 : 32|8@1+ (1,0) [0|255] ""  ControlPanel
 SG_ SubIndex_1016 m4118M : 24|8@1+ (1,0) [0|6] ""  ControlPanel
 SG_ Save_all_Parameters_1010_01 m1 : 32|32@1+ (1,0) [0|4294967295] ""  ControlPanel
 SG_ Number_of_Entries_1010_00 m0 : 32|8@1+ (1,0) [0|255] ""  ControlPanel
 SG_ SubIndex_1010 m4112M : 24|8@1+ (1,0) [0|1] ""  ControlPanel
 SG_ Life_Time_Factor_100D m0 : 32|8@1+ (1,0) [0|255] ""  ControlPanel
 SG_ SubIndex_100D m4109M : 24|8@1+ (1,0) [0|0] ""  ControlPanel
 SG_ Guard_Time_100C m0 : 32|16@1+ (1,0) [0|65535] ""  ControlPanel
 SG_ SubIndex_100C m4108M : 24|8@1+ (1,0) [0|0] ""  ControlPanel
 SG_ Sync_Window_Length_1007 m0 : 32|32@1+ (1,0) [0|4294967295] ""  ControlPanel
 SG_ SubIndex_1007 m4103M : 24|8@1+ (1,0) [0|0] ""  ControlPanel
 SG_ Communication_Cycle_Period_1006 m0 : 32|32@1+ (1,0) [0|4294967295] ""  ControlPanel
 SG_ SubIndex_1006 m4102M : 24|8@1+ (1,0) [0|0] ""  ControlPanel
 SG_ COB_ID_SYNC_1005 m0 : 32|32@1+ (1,0) [128|4294967295] ""  ControlPanel
 SG_ SubIndex_1005 m4101M : 24|8@1+ (1,0) [0|0] ""  ControlPanel
 SG_ Manufacturer_Status_Registe_0004 m0 : 32|32@1+ (1,0) [0|4294967295] ""  ControlPanel
 SG_ SubIndex_1002 m4098M : 24|8@1+ (1,0) [0|0] ""  ControlPanel
 SG_ Error_Register_1001 m0 : 32|8@1+ (1,0) [0|255] ""  ControlPanel
 SG_ SubIndex_1001 m4097M : 24|8@1+ (1,0) [0|0] ""  ControlPanel
 SG_ Device_Type_1000 m0 : 32|32@1+ (1,0) [0|4294967295] ""  ControlPanel
 SG_ SubIndex_1000 m4096M : 24|8@1+ (1,0) [0|0] ""  ControlPanel
 SG_ Index m1M : 8|16@1+ (1,0) [4096|25088] ""  ControlPanel
 SG_ TransferType m1M : 1|1@1+ (1,0) [0|1] ""  ControlPanel
 SG_ NotUsedBytes m1 : 2|2@1+ (1,0) [0|3] ""  ControlPanel
 SG_ SizeIndicator m1 : 0|1@1+ (1,0) [0|1] ""  ControlPanel
 SG_ CCS M : 5|3@1+ (1,0) [0|6] ""  ControlPanel

BO_ 138 EMCY_010: 8 ControlPanel
 SG_ ManufacturerSpecific5 : 56|8@1+ (1,0) [0|0] "" Vector__XXX
 SG_ ManufacturerSpecific4 : 48|8@1+ (1,0) [0|0] "" Vector__XXX
 SG_ ManufacturerSpecific3 : 40|8@1+ (1,0) [0|0] "" Vector__XXX
 SG_ ManufacturerSpecific2 : 32|8@1+ (1,0) [0|0] "" Vector__XXX
 SG_ ManufacturerSpecific1 : 24|8@1+ (1,0) [0|0] "" Vector__XXX
 SG_ ErrorRegisterManufSpecific : 23|1@1+ (1,0) [0|0] "" Vector__XXX
 SG_ ErrorRegisterReserved : 22|1@1+ (1,0) [0|0] "" Vector__XXX
 SG_ ErrorRegisterProfileSpecific : 21|1@1+ (1,0) [0|0] "" Vector__XXX
 SG_ ErrorRegisterCommunication : 20|1@1+ (1,0) [0|0] "" Vector__XXX
 SG_ ErrorRegisterTemperature : 19|1@1+ (1,0) [0|0] "" Vector__XXX
 SG_ ErrorRegisterVoltage : 18|1@1+ (1,0) [0|0] "" Vector__XXX
 SG_ ErrorRegisterCurrent : 17|1@1+ (1,0) [0|0] "" Vector__XXX
 SG_ ErrorRegisterGeneric : 16|1@1+ (1,0) [0|0] "" Vector__XXX
 SG_ ErrorCode : 0|16@1+ (1,0) [0|0] "" Vector__XXX

BO_ 1804 HBGuard_012: 1 SupportFront
 SG_ Toggle : 7|1@1+ (1,0) [0|0] "" Vector__XXX
 SG_ State : 0|7@1+ (1,0) [0|0] "" Vector__XXX

BA_DEF_ BO_  "GenMsgSendType" ENUM  "Cyclic","SendType1","SendType2","SendType3","SendType4","SendType5","SendType6","SendType7","SendType8","SendType9";
BA_DEF_ BO_  "GenMsgCycleTime" INT 0 0;
BA_DEF_ SG_  "GenSigStartValue" INT 0 0;
BA_DEF_ BO_  "CO_MsgCategory" INT 0 0;
BA_DEF_ SG_  "SystemSignalLongSymbol" STRING ;
BA_DEF_DEF_  "GenMsgSendType" "";
BA_DEF_DEF_  "GenMsgCycleTime" 0;
BA_DEF_DEF_  "GenSigStartValue" 0;
BA_DEF_DEF_  "CO_MsgCategory" 0;
BA_DEF_DEF_  "SystemSignalLongSymbol" "";
BA_ "CO_MsgCategory" BO_ 1419 410;
BA_ "CO_MsgCategory" BO_ 1547 405;
BA_ "CO_MsgCategory" BO_ 139 205;
BA_ "GenMsgSendType" BO_ 1802 0;
BA_ "GenMsgCycleTime" BO_ 1802 1000;
BA_ "CO_MsgCategory" BO_ 1802 505;
BA_ "CO_MsgCategory" BO_ 1418 410;
BA_ "CO_MsgCategory" BO_ 1546 405;
BA_ "CO_MsgCategory" BO_ 138 205;
BA_ "GenMsgSendType" BO_ 1804 0;
BA_ "GenMsgCycleTime" BO_ 1804 1000;
BA_ "CO_MsgCategory" BO_ 1804 505;
BA_ "GenSigStartValue" SG_ 1419 supported_drive_modes_6502 2;
BA_ "GenSigStartValue" SG_ 1419 motor_service_period_6407 1000;
BA_ "GenSigStartValue" SG_ 1419 NrOfObjects_60FE_00 2;
BA_ "SystemSignalLongSymbol" SG_ 1419 disable_operation_option_code_60 "disable_operation_option_code_605C";
BA_ "GenSigStartValue" SG_ 1419 delta_time_6049_02 1;
BA_ "GenSigStartValue" SG_ 1419 delta_speed_6049_01 2000;
BA_ "GenSigStartValue" SG_ 1419 NrOfObjects_6049_00 2;
BA_ "GenSigStartValue" SG_ 1419 delta_time_6048_02 1;
BA_ "GenSigStartValue" SG_ 1419 delta_speed_6048_01 1000;
BA_ "GenSigStartValue" SG_ 1419 NrOfObjects_6048_00 2;
BA_ "GenSigStartValue" SG_ 1419 vl_velocity_max_amount_6046_02 1000;
BA_ "GenSigStartValue" SG_ 1419 vl_velocity_min_max_amount_highe 2;
BA_ "SystemSignalLongSymbol" SG_ 1419 vl_velocity_min_max_amount_highe "vl_velocity_min_max_amount_highest_subindex_6046_00";
BA_ "SystemSignalLongSymbol" SG_ 1419 abort_connection_option_code_600 "abort_connection_option_code_6007";
BA_ "GenSigStartValue" SG_ 1419 PDO_Mapping_Entry_1A06_02 1627193376;
BA_ "GenSigStartValue" SG_ 1419 PDO_Mapping_Entry_1A06_01 1614872592;
BA_ "GenSigStartValue" SG_ 1419 PDO_Mapping_Entry_1A05_02 1615069200;
BA_ "GenSigStartValue" SG_ 1419 PDO_Mapping_Entry_1A05_01 1614872592;
BA_ "GenSigStartValue" SG_ 1419 PDO_Mapping_Entry_1A04_02 1618411536;
BA_ "GenSigStartValue" SG_ 1419 PDO_Mapping_Entry_1A04_01 1614872592;
BA_ "GenSigStartValue" SG_ 1419 PDO_Mapping_Entry_1A03_04 1677790224;
BA_ "GenSigStartValue" SG_ 1419 PDO_Mapping_Entry_1A03_03 1677789968;
BA_ "GenSigStartValue" SG_ 1419 PDO_Mapping_Entry_1A03_02 1617690656;
BA_ "GenSigStartValue" SG_ 1419 PDO_Mapping_Entry_1A03_01 1614872592;
BA_ "GenSigStartValue" SG_ 1419 PDO_Mapping_Entry_1A02_04 1677789200;
BA_ "GenSigStartValue" SG_ 1419 PDO_Mapping_Entry_1A02_03 1677788944;
BA_ "GenSigStartValue" SG_ 1419 PDO_Mapping_Entry_1A02_02 1617166368;
BA_ "GenSigStartValue" SG_ 1419 PDO_Mapping_Entry_1A02_01 1614872592;
BA_ "GenSigStartValue" SG_ 1419 PDO_Mapping_Entry_1A01_02 1616969736;
BA_ "GenSigStartValue" SG_ 1419 PDO_Mapping_Entry_1A01_01 1614872592;
BA_ "GenSigStartValue" SG_ 1419 PDO_Mapping_Entry_1A00_02 1615003664;
BA_ "GenSigStartValue" SG_ 1419 mappedObj1_1A00_01 1614872592;
BA_ "GenSigStartValue" SG_ 1419 NrOfMappedObjects_1A00_00 2;
BA_ "GenSigStartValue" SG_ 1419 TransmissionType_1806_02 255;
BA_ "GenSigStartValue" SG_ 1419 COB_ID_1806_01 2147484966;
BA_ "GenSigStartValue" SG_ 1419 NrOfEntries_1806_00 5;
BA_ "GenSigStartValue" SG_ 1419 TransmissionType_1805_02 255;
BA_ "GenSigStartValue" SG_ 1419 COB_ID_1805_01 2147484967;
BA_ "GenSigStartValue" SG_ 1419 NrOfEntries_1805_00 5;
BA_ "GenSigStartValue" SG_ 1419 TransmissionType_1804_02 255;
BA_ "GenSigStartValue" SG_ 1419 COB_ID_1804_01 2147484968;
BA_ "GenSigStartValue" SG_ 1419 NrOfEntries_1804_00 5;
BA_ "GenSigStartValue" SG_ 1419 TransmissionType_1803_02 255;
BA_ "GenSigStartValue" SG_ 1419 COB_ID_1803_01 2147484811;
BA_ "GenSigStartValue" SG_ 1419 NrOfEntries_1803_00 5;
BA_ "GenSigStartValue" SG_ 1419 TransmissionType_1802_02 255;
BA_ "GenSigStartValue" SG_ 1419 COB_ID_1802_01 2147484555;
BA_ "GenSigStartValue" SG_ 1419 NrOfEntries_1802_00 5;
BA_ "GenSigStartValue" SG_ 1419 TransmissionType_1801_02 255;
BA_ "GenSigStartValue" SG_ 1419 COB_ID_1801_01 2147484299;
BA_ "GenSigStartValue" SG_ 1419 NrOfEntries_1801_00 5;
BA_ "GenSigStartValue" SG_ 1419 TransmissionType_1800_02 255;
BA_ "GenSigStartValue" SG_ 1419 COB_ID_1800_01 769;
BA_ "GenSigStartValue" SG_ 1419 NrOfEntries_1800_00 5;
BA_ "GenSigStartValue" SG_ 1419 PDO_Mapping_Entry_1607_02 1616904200;
BA_ "GenSigStartValue" SG_ 1419 PDO_Mapping_Entry_1607_01 1614807056;
BA_ "GenSigStartValue" SG_ 1419 PDO_Mapping_Entry_1606_02 1627259168;
BA_ "GenSigStartValue" SG_ 1419 PDO_Mapping_Entry_1606_01 1614807056;
BA_ "GenSigStartValue" SG_ 1419 PDO_Mapping_Entry_1605_02 1614938128;
BA_ "GenSigStartValue" SG_ 1419 PDO_Mapping_Entry_1605_01 1614807056;
BA_ "GenSigStartValue" SG_ 1419 PDO_Mapping_Entry_1604_02 1618018320;
BA_ "GenSigStartValue" SG_ 1419 PDO_Mapping_Entry_1604_01 1614807056;
BA_ "GenSigStartValue" SG_ 1419 PDO_Mapping_Entry_1603_04 1678838800;
BA_ "GenSigStartValue" SG_ 1419 PDO_Mapping_Entry_1603_03 1678838544;
BA_ "GenSigStartValue" SG_ 1419 PDO_Mapping_Entry_1603_02 1627324448;
BA_ "GenSigStartValue" SG_ 1419 PDO_Mapping_Entry_1603_01 1614807056;
BA_ "GenSigStartValue" SG_ 1419 PDO_Mapping_Entry_1602_04 1678837776;
BA_ "GenSigStartValue" SG_ 1419 PDO_Mapping_Entry_1602_03 1678837520;
BA_ "GenSigStartValue" SG_ 1419 PDO_Mapping_Entry_1602_02 1618608160;
BA_ "GenSigStartValue" SG_ 1419 PDO_Mapping_Entry_1602_01 1614807056;
BA_ "GenSigStartValue" SG_ 1419 PDO_Mapping_Entry_1601_02 1616904200;
BA_ "GenSigStartValue" SG_ 1419 PDO_Mapping_Entry_1601_01 1614807056;
BA_ "GenSigStartValue" SG_ 1419 mappedObj2_1600_02 1614807056;
BA_ "GenSigStartValue" SG_ 1419 mappedObj1_1600_01 1614938128;
BA_ "GenSigStartValue" SG_ 1419 NrOfMappedObjects_1600_00 2;
BA_ "GenSigStartValue" SG_ 1419 TransmissionType_1407_02 255;
BA_ "GenSigStartValue" SG_ 1419 COB_ID_1407_01 2147484962;
BA_ "GenSigStartValue" SG_ 1419 NrOfEntries_1407_00 2;
BA_ "GenSigStartValue" SG_ 1419 TransmissionType_1406_02 255;
BA_ "GenSigStartValue" SG_ 1419 COB_ID_1406_01 2147484963;
BA_ "GenSigStartValue" SG_ 1419 NrOfEntries_1406_00 2;
BA_ "GenSigStartValue" SG_ 1419 TransmissionType_1405_02 255;
BA_ "GenSigStartValue" SG_ 1419 COB_ID_1405_01 2147484964;
BA_ "GenSigStartValue" SG_ 1419 NrOfEntries_1405_00 2;
BA_ "GenSigStartValue" SG_ 1419 TransmissionType_1404_02 255;
BA_ "GenSigStartValue" SG_ 1419 COB_ID_1404_01 2147484965;
BA_ "GenSigStartValue" SG_ 1419 NrOfEntries_1404_00 2;
BA_ "GenSigStartValue" SG_ 1419 TransmissionType_1403_02 255;
BA_ "GenSigStartValue" SG_ 1419 COB_ID_1403_01 2147484939;
BA_ "GenSigStartValue" SG_ 1419 NrOfEntries_1403_00 2;
BA_ "GenSigStartValue" SG_ 1419 TransmissionType_1402_02 255;
BA_ "GenSigStartValue" SG_ 1419 COB_ID_1402_01 2147484683;
BA_ "GenSigStartValue" SG_ 1419 NrOfEntries_1402_00 2;
BA_ "GenSigStartValue" SG_ 1419 TransmissionType_1401_02 255;
BA_ "GenSigStartValue" SG_ 1419 COB_ID_1401_01 2147484427;
BA_ "GenSigStartValue" SG_ 1419 NrOfEntries_1401_00 2;
BA_ "GenSigStartValue" SG_ 1419 TransmissionType_1400_02 255;
BA_ "GenSigStartValue" SG_ 1419 COB_ID_1400_01 385;
BA_ "GenSigStartValue" SG_ 1419 NrOfEntries_1400_00 2;
BA_ "GenSigStartValue" SG_ 1419 Serial_number_1018_04 1;
BA_ "GenSigStartValue" SG_ 1419 Revision_number_1018_03 1;
BA_ "GenSigStartValue" SG_ 1419 Product_Code_1018_02 1564;
BA_ "GenSigStartValue" SG_ 1419 Vendor_Id_1018_01 5;
BA_ "GenSigStartValue" SG_ 1419 number_of_entries_1018_00 4;
BA_ "GenSigStartValue" SG_ 1419 Producer_Heartbeat_Time_1017 1000;
BA_ "GenSigStartValue" SG_ 1419 NrOfObjects_1016_00 9;
BA_ "GenSigStartValue" SG_ 1419 Number_of_Entries_1010_00 1;
BA_ "GenSigStartValue" SG_ 1419 Life_Time_Factor_100D 3;
BA_ "GenSigStartValue" SG_ 1419 Guard_Time_100C 500;
BA_ "GenSigStartValue" SG_ 1419 Sync_Window_Length_1007 100;
BA_ "GenSigStartValue" SG_ 1419 Communication_Cycle_Period_1006 200000;
BA_ "GenSigStartValue" SG_ 1419 COB_ID_SYNC_1005 2147483776;
BA_ "SystemSignalLongSymbol" SG_ 1419 Manufacturer_Status_Registe_0001 "Manufacturer_Status_Register_1002";
BA_ "GenSigStartValue" SG_ 1419 Device_Type_1000 402;
BA_ "GenSigStartValue" SG_ 1419 Index 4096;
BA_ "GenSigStartValue" SG_ 1547 supported_drive_modes_6502 2;
BA_ "GenSigStartValue" SG_ 1547 motor_service_period_6407 1000;
BA_ "GenSigStartValue" SG_ 1547 NrOfObjects_60FE_00 2;
BA_ "SystemSignalLongSymbol" SG_ 1547 disable_operation_option_co_0000 "disable_operation_option_code_605C";
BA_ "GenSigStartValue" SG_ 1547 delta_time_6049_02 1;
BA_ "GenSigStartValue" SG_ 1547 delta_speed_6049_01 2000;
BA_ "GenSigStartValue" SG_ 1547 NrOfObjects_6049_00 2;
BA_ "GenSigStartValue" SG_ 1547 delta_time_6048_02 1;
BA_ "GenSigStartValue" SG_ 1547 delta_speed_6048_01 1000;
BA_ "GenSigStartValue" SG_ 1547 NrOfObjects_6048_00 2;
BA_ "GenSigStartValue" SG_ 1547 vl_velocity_max_amount_6046_02 1000;
BA_ "GenSigStartValue" SG_ 1547 vl_velocity_min_max_amount__0000 2;
BA_ "SystemSignalLongSymbol" SG_ 1547 vl_velocity_min_max_amount__0000 "vl_velocity_min_max_amount_highest_subindex_6046_00";
BA_ "SystemSignalLongSymbol" SG_ 1547 abort_connection_option_cod_0000 "abort_connection_option_code_6007";
BA_ "GenSigStartValue" SG_ 1547 PDO_Mapping_Entry_1A06_02 1627193376;
BA_ "GenSigStartValue" SG_ 1547 PDO_Mapping_Entry_1A06_01 1614872592;
BA_ "GenSigStartValue" SG_ 1547 PDO_Mapping_Entry_1A05_02 1615069200;
BA_ "GenSigStartValue" SG_ 1547 PDO_Mapping_Entry_1A05_01 1614872592;
BA_ "GenSigStartValue" SG_ 1547 PDO_Mapping_Entry_1A04_02 1618411536;
BA_ "GenSigStartValue" SG_ 1547 PDO_Mapping_Entry_1A04_01 1614872592;
BA_ "GenSigStartValue" SG_ 1547 PDO_Mapping_Entry_1A03_04 1677790224;
BA_ "GenSigStartValue" SG_ 1547 PDO_Mapping_Entry_1A03_03 1677789968;
BA_ "GenSigStartValue" SG_ 1547 PDO_Mapping_Entry_1A03_02 1617690656;
BA_ "GenSigStartValue" SG_ 1547 PDO_Mapping_Entry_1A03_01 1614872592;
BA_ "GenSigStartValue" SG_ 1547 PDO_Mapping_Entry_1A02_04 1677789200;
BA_ "GenSigStartValue" SG_ 1547 PDO_Mapping_Entry_1A02_03 1677788944;
BA_ "GenSigStartValue" SG_ 1547 PDO_Mapping_Entry_1A02_02 1617166368;
BA_ "GenSigStartValue" SG_ 1547 PDO_Mapping_Entry_1A02_01 1614872592;
BA_ "GenSigStartValue" SG_ 1547 PDO_Mapping_Entry_1A01_02 1616969736;
BA_ "GenSigStartValue" SG_ 1547 PDO_Mapping_Entry_1A01_01 1614872592;
BA_ "GenSigStartValue" SG_ 1547 PDO_Mapping_Entry_1A00_02 1615003664;
BA_ "GenSigStartValue" SG_ 1547 mappedObj1_1A00_01 1614872592;
BA_ "GenSigStartValue" SG_ 1547 NrOfMappedObjects_1A00_00 2;
BA_ "GenSigStartValue" SG_ 1547 TransmissionType_1806_02 255;
BA_ "GenSigStartValue" SG_ 1547 COB_ID_1806_01 2147484966;
BA_ "GenSigStartValue" SG_ 1547 NrOfEntries_1806_00 5;
BA_ "GenSigStartValue" SG_ 1547 TransmissionType_1805_02 255;
BA_ "GenSigStartValue" SG_ 1547 COB_ID_1805_01 2147484967;
BA_ "GenSigStartValue" SG_ 1547 NrOfEntries_1805_00 5;
BA_ "GenSigStartValue" SG_ 1547 TransmissionType_1804_02 255;
BA_ "GenSigStartValue" SG_ 1547 COB_ID_1804_01 2147484968;
BA_ "GenSigStartValue" SG_ 1547 NrOfEntries_1804_00 5;
BA_ "GenSigStartValue" SG_ 1547 TransmissionType_1803_02 255;
BA_ "GenSigStartValue" SG_ 1547 COB_ID_1803_01 2147484811;
BA_ "GenSigStartValue" SG_ 1547 NrOfEntries_1803_00 5;
BA_ "GenSigStartValue" SG_ 1547 TransmissionType_1802_02 255;
BA_ "GenSigStartValue" SG_ 1547 COB_ID_1802_01 2147484555;
BA_ "GenSigStartValue" SG_ 1547 NrOfEntries_1802_00 5;
BA_ "GenSigStartValue" SG_ 1547 TransmissionType_1801_02 255;
BA_ "GenSigStartValue" SG_ 1547 COB_ID_1801_01 2147484299;
BA_ "GenSigStartValue" SG_ 1547 NrOfEntries_1801_00 5;
BA_ "GenSigStartValue" SG_ 1547 TransmissionType_1800_02 255;
BA_ "GenSigStartValue" SG_ 1547 COB_ID_1800_01 769;
BA_ "GenSigStartValue" SG_ 1547 NrOfEntries_1800_00 5;
BA_ "GenSigStartValue" SG_ 1547 PDO_Mapping_Entry_1607_02 1616904200;
BA_ "GenSigStartValue" SG_ 1547 PDO_Mapping_Entry_1607_01 1614807056;
BA_ "GenSigStartValue" SG_ 1547 PDO_Mapping_Entry_1606_02 1627259168;
BA_ "GenSigStartValue" SG_ 1547 PDO_Mapping_Entry_1606_01 1614807056;
BA_ "GenSigStartValue" SG_ 1547 PDO_Mapping_Entry_1605_02 1614938128;
BA_ "GenSigStartValue" SG_ 1547 PDO_Mapping_Entry_1605_01 1614807056;
BA_ "GenSigStartValue" SG_ 1547 PDO_Mapping_Entry_1604_02 1618018320;
BA_ "GenSigStartValue" SG_ 1547 PDO_Mapping_Entry_1604_01 1614807056;
BA_ "GenSigStartValue" SG_ 1547 PDO_Mapping_Entry_1603_04 1678838800;
BA_ "GenSigStartValue" SG_ 1547 PDO_Mapping_Entry_1603_03 1678838544;
BA_ "GenSigStartValue" SG_ 1547 PDO_Mapping_Entry_1603_02 1627324448;
BA_ "GenSigStartValue" SG_ 1547 PDO_Mapping_Entry_1603_01 1614807056;
BA_ "GenSigStartValue" SG_ 1547 PDO_Mapping_Entry_1602_04 1678837776;
BA_ "GenSigStartValue" SG_ 1547 PDO_Mapping_Entry_1602_03 1678837520;
BA_ "GenSigStartValue" SG_ 1547 PDO_Mapping_Entry_1602_02 1618608160;
BA_ "GenSigStartValue" SG_ 1547 PDO_Mapping_Entry_1602_01 1614807056;
BA_ "GenSigStartValue" SG_ 1547 PDO_Mapping_Entry_1601_02 1616904200;
BA_ "GenSigStartValue" SG_ 1547 PDO_Mapping_Entry_1601_01 1614807056;
BA_ "GenSigStartValue" SG_ 1547 mappedObj2_1600_02 1614807056;
BA_ "GenSigStartValue" SG_ 1547 mappedObj1_1600_01 1614938128;
BA_ "GenSigStartValue" SG_ 1547 NrOfMappedObjects_1600_00 2;
BA_ "GenSigStartValue" SG_ 1547 TransmissionType_1407_02 255;
BA_ "GenSigStartValue" SG_ 1547 COB_ID_1407_01 2147484962;
BA_ "GenSigStartValue" SG_ 1547 NrOfEntries_1407_00 2;
BA_ "GenSigStartValue" SG_ 1547 TransmissionType_1406_02 255;
BA_ "GenSigStartValue" SG_ 1547 COB_ID_1406_01 2147484963;
BA_ "GenSigStartValue" SG_ 1547 NrOfEntries_1406_00 2;
BA_ "GenSigStartValue" SG_ 1547 TransmissionType_1405_02 255;
BA_ "GenSigStartValue" SG_ 1547 COB_ID_1405_01 2147484964;
BA_ "GenSigStartValue" SG_ 1547 NrOfEntries_1405_00 2;
BA_ "GenSigStartValue" SG_ 1547 TransmissionType_1404_02 255;
BA_ "GenSigStartValue" SG_ 1547 COB_ID_1404_01 2147484965;
BA_ "GenSigStartValue" SG_ 1547 NrOfEntries_1404_00 2;
BA_ "GenSigStartValue" SG_ 1547 TransmissionType_1403_02 255;
BA_ "GenSigStartValue" SG_ 1547 COB_ID_1403_01 2147484939;
BA_ "GenSigStartValue" SG_ 1547 NrOfEntries_1403_00 2;
BA_ "GenSigStartValue" SG_ 1547 TransmissionType_1402_02 255;
BA_ "GenSigStartValue" SG_ 1547 COB_ID_1402_01 2147484683;
BA_ "GenSigStartValue" SG_ 1547 NrOfEntries_1402_00 2;
BA_ "GenSigStartValue" SG_ 1547 TransmissionType_1401_02 255;
BA_ "GenSigStartValue" SG_ 1547 COB_ID_1401_01 2147484427;
BA_ "GenSigStartValue" SG_ 1547 NrOfEntries_1401_00 2;
BA_ "GenSigStartValue" SG_ 1547 TransmissionType_1400_02 255;
BA_ "GenSigStartValue" SG_ 1547 COB_ID_1400_01 385;
BA_ "GenSigStartValue" SG_ 1547 NrOfEntries_1400_00 2;
BA_ "GenSigStartValue" SG_ 1547 Serial_number_1018_04 1;
BA_ "GenSigStartValue" SG_ 1547 Revision_number_1018_03 1;
BA_ "GenSigStartValue" SG_ 1547 Product_Code_1018_02 1564;
BA_ "GenSigStartValue" SG_ 1547 Vendor_Id_1018_01 5;
BA_ "GenSigStartValue" SG_ 1547 number_of_entries_1018_00 4;
BA_ "GenSigStartValue" SG_ 1547 Producer_Heartbeat_Time_1017 1000;
BA_ "GenSigStartValue" SG_ 1547 NrOfObjects_1016_00 9;
BA_ "GenSigStartValue" SG_ 1547 Number_of_Entries_1010_00 1;
BA_ "GenSigStartValue" SG_ 1547 Life_Time_Factor_100D 3;
BA_ "GenSigStartValue" SG_ 1547 Guard_Time_100C 500;
BA_ "GenSigStartValue" SG_ 1547 Sync_Window_Length_1007 100;
BA_ "GenSigStartValue" SG_ 1547 Communication_Cycle_Period_1006 200000;
BA_ "GenSigStartValue" SG_ 1547 COB_ID_SYNC_1005 2147483776;
BA_ "SystemSignalLongSymbol" SG_ 1547 Manufacturer_Status_Registe_0002 "Manufacturer_Status_Register_1002";
BA_ "GenSigStartValue" SG_ 1547 Device_Type_1000 402;
BA_ "GenSigStartValue" SG_ 1547 Index 4096;
BA_ "GenSigStartValue" SG_ 1418 NrOfObjects_6200_00 8;
BA_ "GenSigStartValue" SG_ 1418 NrOfObjects_6000_00 8;
BA_ "GenSigStartValue" SG_ 1418 mappedObj5_1A00_05 1610614024;
BA_ "GenSigStartValue" SG_ 1418 mappedObj4_1A00_04 1610613768;
BA_ "GenSigStartValue" SG_ 1418 mappedObj3_1A00_03 1610613512;
BA_ "GenSigStartValue" SG_ 1418 mappedObj2_1A00_02 1610613256;
BA_ "GenSigStartValue" SG_ 1418 mappedObj1_1A00_01 1610613000;
BA_ "GenSigStartValue" SG_ 1418 NrOfMappedObjects_1A00_00 5;
BA_ "GenSigStartValue" SG_ 1418 TransmissionType_1801_02 255;
BA_ "GenSigStartValue" SG_ 1418 COB_ID_1801_01 2147484298;
BA_ "GenSigStartValue" SG_ 1418 NrOfEntries_1801_00 5;
BA_ "GenSigStartValue" SG_ 1418 TransmissionType_1800_02 255;
BA_ "GenSigStartValue" SG_ 1418 COB_ID_1800_01 513;
BA_ "GenSigStartValue" SG_ 1418 NrOfEntries_1800_00 5;
BA_ "GenSigStartValue" SG_ 1418 TransmissionType_1401_02 255;
BA_ "GenSigStartValue" SG_ 1418 COB_ID_1401_01 2147484426;
BA_ "GenSigStartValue" SG_ 1418 NrOfEntries_1401_00 2;
BA_ "GenSigStartValue" SG_ 1418 TransmissionType_1400_02 255;
BA_ "GenSigStartValue" SG_ 1418 COB_ID_1400_01 2147484170;
BA_ "GenSigStartValue" SG_ 1418 NrOfEntries_1400_00 2;
BA_ "GenSigStartValue" SG_ 1418 Serial_number_1018_04 1;
BA_ "GenSigStartValue" SG_ 1418 Revision_number_1018_03 1;
BA_ "GenSigStartValue" SG_ 1418 Product_Code_1018_02 1;
BA_ "GenSigStartValue" SG_ 1418 Vendor_Id_1018_01 1;
BA_ "GenSigStartValue" SG_ 1418 number_of_entries_1018_00 4;
BA_ "GenSigStartValue" SG_ 1418 Producer_Heartbeat_Time_1017 1000;
BA_ "GenSigStartValue" SG_ 1418 NrOfObjects_1016_00 6;
BA_ "GenSigStartValue" SG_ 1418 Number_of_Entries_1010_00 1;
BA_ "GenSigStartValue" SG_ 1418 Life_Time_Factor_100D 3;
BA_ "GenSigStartValue" SG_ 1418 Guard_Time_100C 500;
BA_ "GenSigStartValue" SG_ 1418 Sync_Window_Length_1007 100;
BA_ "GenSigStartValue" SG_ 1418 Communication_Cycle_Period_1006 200000;
BA_ "GenSigStartValue" SG_ 1418 COB_ID_SYNC_1005 2147483776;
BA_ "SystemSignalLongSymbol" SG_ 1418 Manufacturer_Status_Registe_0003 "Manufacturer_Status_Register_1002";
BA_ "GenSigStartValue" SG_ 1418 Device_Type_1000 401;
BA_ "GenSigStartValue" SG_ 1418 Index 4096;
BA_ "GenSigStartValue" SG_ 1546 NrOfObjects_6200_00 8;
BA_ "GenSigStartValue" SG_ 1546 NrOfObjects_6000_00 8;
BA_ "GenSigStartValue" SG_ 1546 mappedObj5_1A00_05 1610614024;
BA_ "GenSigStartValue" SG_ 1546 mappedObj4_1A00_04 1610613768;
BA_ "GenSigStartValue" SG_ 1546 mappedObj3_1A00_03 1610613512;
BA_ "GenSigStartValue" SG_ 1546 mappedObj2_1A00_02 1610613256;
BA_ "GenSigStartValue" SG_ 1546 mappedObj1_1A00_01 1610613000;
BA_ "GenSigStartValue" SG_ 1546 NrOfMappedObjects_1A00_00 5;
BA_ "GenSigStartValue" SG_ 1546 TransmissionType_1801_02 255;
BA_ "GenSigStartValue" SG_ 1546 COB_ID_1801_01 2147484298;
BA_ "GenSigStartValue" SG_ 1546 NrOfEntries_1801_00 5;
BA_ "GenSigStartValue" SG_ 1546 TransmissionType_1800_02 255;
BA_ "GenSigStartValue" SG_ 1546 COB_ID_1800_01 513;
BA_ "GenSigStartValue" SG_ 1546 NrOfEntries_1800_00 5;
BA_ "GenSigStartValue" SG_ 1546 TransmissionType_1401_02 255;
BA_ "GenSigStartValue" SG_ 1546 COB_ID_1401_01 2147484426;
BA_ "GenSigStartValue" SG_ 1546 NrOfEntries_1401_00 2;
BA_ "GenSigStartValue" SG_ 1546 TransmissionType_1400_02 255;
BA_ "GenSigStartValue" SG_ 1546 COB_ID_1400_01 2147484170;
BA_ "GenSigStartValue" SG_ 1546 NrOfEntries_1400_00 2;
BA_ "GenSigStartValue" SG_ 1546 Serial_number_1018_04 1;
BA_ "GenSigStartValue" SG_ 1546 Revision_number_1018_03 1;
BA_ "GenSigStartValue" SG_ 1546 Product_Code_1018_02 1;
BA_ "GenSigStartValue" SG_ 1546 Vendor_Id_1018_01 1;
BA_ "GenSigStartValue" SG_ 1546 number_of_entries_1018_00 4;
BA_ "GenSigStartValue" SG_ 1546 Producer_Heartbeat_Time_1017 1000;
BA_ "GenSigStartValue" SG_ 1546 NrOfObjects_1016_00 6;
BA_ "GenSigStartValue" SG_ 1546 Number_of_Entries_1010_00 1;
BA_ "GenSigStartValue" SG_ 1546 Life_Time_Factor_100D 3;
BA_ "GenSigStartValue" SG_ 1546 Guard_Time_100C 500;
BA_ "GenSigStartValue" SG_ 1546 Sync_Window_Length_1007 100;
BA_ "GenSigStartValue" SG_ 1546 Communication_Cycle_Period_1006 200000;
BA_ "GenSigStartValue" SG_ 1546 COB_ID_SYNC_1005 2147483776;
BA_ "SystemSignalLongSymbol" SG_ 1546 Manufacturer_Status_Registe_0004 "Manufacturer_Status_Register_1002";
BA_ "GenSigStartValue" SG_ 1546 Device_Type_1000 401;
BA_ "GenSigStartValue" SG_ 1546 Index 4096;
VAL_ 1419 SubIndex_6502 0 "supported_drive_modes" ;
VAL_ 1419 SubIndex_6407 0 "motor_service_period" ;
VAL_ 1419 SubIndex_6402 0 "motor_type" ;
VAL_ 1419 SubIndex_60FF 0 "target_velocity" ;
VAL_ 1419 SubIndex_60FE 2 "bitmask" 1 "physical_outputs" 0 "NrOfObjects" ;
VAL_ 1419 SubIndex_60FD 0 "digital_inputs" ;
VAL_ 1419 SubIndex_607E 0 "polarity" ;
VAL_ 1419 SubIndex_607A 0 "target_position" ;
VAL_ 1419 SubIndex_6077 0 "torque_actual_value" ;
VAL_ 1419 SubIndex_6071 0 "target_torque" ;
VAL_ 1419 SubIndex_606C 0 "velocity_actual_value" ;
VAL_ 1419 SubIndex_6067 0 "position_window" ;
VAL_ 1419 SubIndex_6064 0 "position_actual_value" ;
VAL_ 1419 SubIndex_6063 0 "position_actual_value" ;
VAL_ 1419 SubIndex_6062 0 "position_demand_value" ;
VAL_ 1419 SubIndex_6061 0 "modes_of_operation_display" ;
VAL_ 1419 SubIndex_6060 0 "modes_of_operation" ;
VAL_ 1419 SubIndex_605E 0 "fault_reaction_option_code" ;
VAL_ 1419 SubIndex_605D 0 "stop_option_code" ;
VAL_ 1419 SubIndex_605C 0 "disable_operation_option_code" ;
VAL_ 1419 SubIndex_605B 0 "shutdown_option_code" ;
VAL_ 1419 SubIndex_605A 0 "quick_stop_option_code" ;
VAL_ 1419 SubIndex_6049 2 "delta_time" 1 "delta_speed" 0 "NrOfObjects" ;
VAL_ 1419 SubIndex_6048 2 "delta_time" 1 "delta_speed" 0 "NrOfObjects" ;
VAL_ 1419 SubIndex_6046 2 "vl_velocity_max_amount" 1 "vl_velocity_min_amount" 0 "vl_velocity_min_max_amount_highest_subindex" ;
VAL_ 1419 SubIndex_6044 0 "vl_control_effort" ;
VAL_ 1419 SubIndex_6043 0 "vl_velocity_demand" ;
VAL_ 1419 SubIndex_6042 0 "vl_target_velocity" ;
VAL_ 1419 SubIndex_6041 0 "statusword" ;
VAL_ 1419 SubIndex_6040 0 "controlword" ;
VAL_ 1419 SubIndex_603F 0 "error_code" ;
VAL_ 1419 SubIndex_6007 0 "abort_connection_option_code" ;
VAL_ 1419 SubIndex_1A06 8 "PDO Mapping Entry" 7 "PDO Mapping Entry" 6 "PDO Mapping Entry" 5 "PDO Mapping Entry" 4 "PDO Mapping Entry" 3 "PDO Mapping Entry" 2 "PDO Mapping Entry" 1 "PDO Mapping Entry" 0 "NrOfMappedObjects" ;
VAL_ 1419 SubIndex_1A05 8 "PDO Mapping Entry" 7 "PDO Mapping Entry" 6 "PDO Mapping Entry" 5 "PDO Mapping Entry" 4 "PDO Mapping Entry" 3 "PDO Mapping Entry" 2 "PDO Mapping Entry" 1 "PDO Mapping Entry" 0 "NrOfMappedObjects" ;
VAL_ 1419 SubIndex_1A04 8 "PDO Mapping Entry" 7 "PDO Mapping Entry" 6 "PDO Mapping Entry" 5 "PDO Mapping Entry" 4 "PDO Mapping Entry" 3 "PDO Mapping Entry" 2 "PDO Mapping Entry" 1 "PDO Mapping Entry" 0 "NrOfMappedObjects" ;
VAL_ 1419 SubIndex_1A03 8 "PDO Mapping Entry" 7 "PDO Mapping Entry" 6 "PDO Mapping Entry" 5 "PDO Mapping Entry" 4 "PDO Mapping Entry" 3 "PDO Mapping Entry" 2 "PDO Mapping Entry" 1 "PDO Mapping Entry" 0 "NrOfMappedObjects" ;
VAL_ 1419 SubIndex_1A02 8 "PDO Mapping Entry" 7 "PDO Mapping Entry" 6 "PDO Mapping Entry" 5 "PDO Mapping Entry" 4 "PDO Mapping Entry" 3 "PDO Mapping Entry" 2 "PDO Mapping Entry" 1 "PDO Mapping Entry" 0 "NrOfMappedObjects" ;
VAL_ 1419 SubIndex_1A01 8 "PDO Mapping Entry" 7 "PDO Mapping Entry" 6 "PDO Mapping Entry" 5 "PDO Mapping Entry" 4 "PDO Mapping Entry" 3 "PDO Mapping Entry" 2 "PDO Mapping Entry" 1 "PDO Mapping Entry" 0 "NrOfMappedObjects" ;
VAL_ 1419 SubIndex_1A00 8 "PDO Mapping Entry" 7 "PDO Mapping Entry" 6 "PDO Mapping Entry" 5 "PDO Mapping Entry" 4 "PDO Mapping Entry" 3 "PDO Mapping Entry" 2 "PDO Mapping Entry" 1 "mappedObj1" 0 "NrOfMappedObjects" ;
VAL_ 1419 SubIndex_1806 5 "EventTimer" 2 "TransmissionType" 1 "COB-ID" 0 "NrOfEntries" ;
VAL_ 1419 SubIndex_1805 5 "EventTimer" 2 "TransmissionType" 1 "COB-ID" 0 "NrOfEntries" ;
VAL_ 1419 SubIndex_1804 5 "EventTimer" 2 "TransmissionType" 1 "COB-ID" 0 "NrOfEntries" ;
VAL_ 1419 SubIndex_1803 5 "EventTimer" 2 "TransmissionType" 1 "COB-ID" 0 "NrOfEntries" ;
VAL_ 1419 SubIndex_1802 5 "EventTimer" 2 "TransmissionType" 1 "COB-ID" 0 "NrOfEntries" ;
VAL_ 1419 SubIndex_1801 5 "EventTimer" 2 "TransmissionType" 1 "COB-ID" 0 "NrOfEntries" ;
VAL_ 1419 SubIndex_1800 5 "EventTimer" 2 "TransmissionType" 1 "COB-ID" 0 "NrOfEntries" ;
VAL_ 1419 SubIndex_1607 8 "PDO Mapping Entry" 7 "PDO Mapping Entry" 6 "PDO Mapping Entry" 5 "PDO Mapping Entry" 4 "PDO Mapping Entry" 3 "PDO Mapping Entry" 2 "PDO Mapping Entry" 1 "PDO Mapping Entry" 0 "NrOfMappedObjects" ;
VAL_ 1419 SubIndex_1606 8 "PDO Mapping Entry" 7 "PDO Mapping Entry" 6 "PDO Mapping Entry" 5 "PDO Mapping Entry" 4 "PDO Mapping Entry" 3 "PDO Mapping Entry" 2 "PDO Mapping Entry" 1 "PDO Mapping Entry" 0 "NrOfMappedObjects" ;
VAL_ 1419 SubIndex_1605 8 "PDO Mapping Entry" 7 "PDO Mapping Entry" 6 "PDO Mapping Entry" 5 "PDO Mapping Entry" 4 "PDO Mapping Entry" 3 "PDO Mapping Entry" 2 "PDO Mapping Entry" 1 "PDO Mapping Entry" 0 "NrOfMappedObjects" ;
VAL_ 1419 SubIndex_1604 8 "PDO Mapping Entry" 7 "PDO Mapping Entry" 6 "PDO Mapping Entry" 5 "PDO Mapping Entry" 4 "PDO Mapping Entry" 3 "PDO Mapping Entry" 2 "PDO Mapping Entry" 1 "PDO Mapping Entry" 0 "NrOfMappedObjects" ;
VAL_ 1419 SubIndex_1603 8 "PDO Mapping Entry" 7 "PDO Mapping Entry" 6 "PDO Mapping Entry" 5 "PDO Mapping Entry" 4 "PDO Mapping Entry" 3 "PDO Mapping Entry" 2 "PDO Mapping Entry" 1 "PDO Mapping Entry" 0 "NrOfMappedObjects" ;
VAL_ 1419 SubIndex_1602 8 "PDO Mapping Entry" 7 "PDO Mapping Entry" 6 "PDO Mapping Entry" 5 "PDO Mapping Entry" 4 "PDO Mapping Entry" 3 "PDO Mapping Entry" 2 "PDO Mapping Entry" 1 "PDO Mapping Entry" 0 "NrOfMappedObjects" ;
VAL_ 1419 SubIndex_1601 8 "PDO Mapping Entry" 7 "PDO Mapping Entry" 6 "PDO Mapping Entry" 5 "PDO Mapping Entry" 4 "PDO Mapping Entry" 3 "PDO Mapping Entry" 2 "PDO Mapping Entry" 1 "PDO Mapping Entry" 0 "NrOfMappedObjects" ;
VAL_ 1419 SubIndex_1600 8 "PDO Mapping Entry" 7 "PDO Mapping Entry" 6 "PDO Mapping Entry" 5 "PDO Mapping Entry" 4 "PDO Mapping Entry" 3 "PDO Mapping Entry" 2 "mappedObj2" 1 "mappedObj1" 0 "NrOfMappedObjects" ;
VAL_ 1419 SubIndex_1407 2 "TransmissionType" 1 "COB-ID" 0 "NrOfEntries" ;
VAL_ 1419 SubIndex_1406 2 "TransmissionType" 1 "COB-ID" 0 "NrOfEntries" ;
VAL_ 1419 SubIndex_1405 2 "TransmissionType" 1 "COB-ID" 0 "NrOfEntries" ;
VAL_ 1419 SubIndex_1404 2 "TransmissionType" 1 "COB-ID" 0 "NrOfEntries" ;
VAL_ 1419 SubIndex_1403 2 "TransmissionType" 1 "COB-ID" 0 "NrOfEntries" ;
VAL_ 1419 SubIndex_1402 2 "TransmissionType" 1 "COB-ID" 0 "NrOfEntries" ;
VAL_ 1419 SubIndex_1401 2 "TransmissionType" 1 "COB-ID" 0 "NrOfEntries" ;
VAL_ 1419 SubIndex_1400 2 "TransmissionType" 1 "COB-ID" 0 "NrOfEntries" ;
VAL_ 1419 SubIndex_1018 4 "Serial number" 3 "Revision number" 2 "Product Code" 1 "Vendor Id" 0 "number of entries" ;
VAL_ 1419 SubIndex_1017 0 "Producer Heartbeat Time" ;
VAL_ 1419 SubIndex_1016 9 "Consumer Heartbeat Time" 8 "Consumer Heartbeat Time" 7 "Consumer Heartbeat Time" 6 "Consumer Heartbeat Time" 5 "Consumer Heartbeat Time" 4 "Consumer Heartbeat Time" 3 "Consumer Heartbeat Time" 2 "Consumer Heartbeat Time" 1 "Consumer Heartbeat Time" 0 "NrOfObjects" ;
VAL_ 1419 SubIndex_1010 1 "Save all Parameters" 0 "Number of Entries" ;
VAL_ 1419 SubIndex_100D 0 "Life Time Factor" ;
VAL_ 1419 SubIndex_100C 0 "Guard Time" ;
VAL_ 1419 SubIndex_1007 0 "Sync_Window Length" ;
VAL_ 1419 SubIndex_1006 0 "Communication Cycle Period" ;
VAL_ 1419 SubIndex_1005 0 "COB-ID SYNC" ;
VAL_ 1419 SubIndex_1002 0 "Manufacturer Status Register" ;
VAL_ 1419 SubIndex_1001 0 "Error Register" ;
VAL_ 1419 SubIndex_1000 0 "Device Type" ;
VAL_ 1419 Index 25858 "supported_drive_modes" 25607 "motor_service_period" 25602 "motor_type" 24831 "target_velocity" 24830 "digital_outputs" 24829 "digital_inputs" 24702 "polarity" 24698 "target_position" 24695 "torque_actual_value" 24689 "target_torque" 24684 "velocity_actual_value" 24679 "position_window" 24676 "position_actual_value" 24675 "position_actual_value" 24674 "position_demand_value" 24673 "modes_of_operation_display" 24672 "modes_of_operation" 24670 "fault_reaction_option_code" 24669 "stop_option_code" 24668 "disable_operation_option_code" 24667 "shutdown_option_code" 24666 "quick_stop_option_code" 24649 "vl_velocity_deceleration" 24648 "vl_velocity_acceleration" 24646 "vl_velocity_min_max_amount" 24644 "vl_control_effort" 24643 "vl_velocity_demand" 24642 "vl_target_velocity" 24641 "statusword" 24640 "controlword" 24639 "error_code" 24583 "abort_connection_option_code" 6662 "TxPDOMapping" 6661 "TxPDOMapping" 6660 "TxPDOMapping" 6659 "TxPDOMapping" 6658 "TxPDOMapping" 6657 "TxPDOMapping" 6656 "TxPDOMapping" 6150 "TxPDOComPar" 6149 "TxPDOComPar" 6148 "TxPDOComPar" 6147 "TxPDOComPar" 6146 "TxPDOComPar" 6145 "TxPDOComPar" 6144 "TxPDOComPar" 5639 "RxPDOMapping" 5638 "RxPDOMapping" 5637 "RxPDOMapping" 5636 "RxPDOMapping" 5635 "RxPDOMapping" 5634 "RxPDOMapping" 5633 "RxPDOMapping" 5632 "RxPDOMapping" 5127 "RxPDOComPar" 5126 "RxPDOComPar" 5125 "RxPDOComPar" 5124 "RxPDOComPar" 5123 "RxPDOComPar" 5122 "RxPDOComPar" 5121 "RxPDOComPar" 5120 "RxPDOComPar" 4120 "Identity Object" 4119 "Producer Heartbeat Time" 4118 "Consumer Heartbeat Time" 4112 "Store Parameter Field" 4109 "Life Time Factor" 4108 "Guard Time" 4103 "Sync_Window Length" 4102 "Communication Cycle Period" 4101 "COB-ID SYNC" 4098 "Manufacturer Status Register" 4097 "Error Register" 4096 "Device Type" ;
VAL_ 1419 TransferType 1 "Expedited transfer" 0 "Normal transfer" ;
VAL_ 1419 SizeIndicator 1 "Size is indicated" 0 "Size is not indicated" ;
VAL_ 1419 SCS 2 "Upload" 1 "Download" ;
VAL_ 1547 SubIndex_6502 0 "supported_drive_modes" ;
VAL_ 1547 SubIndex_6407 0 "motor_service_period" ;
VAL_ 1547 SubIndex_6402 0 "motor_type" ;
VAL_ 1547 SubIndex_60FF 0 "target_velocity" ;
VAL_ 1547 SubIndex_60FE 2 "bitmask" 1 "physical_outputs" 0 "NrOfObjects" ;
VAL_ 1547 SubIndex_60FD 0 "digital_inputs" ;
VAL_ 1547 SubIndex_607E 0 "polarity" ;
VAL_ 1547 SubIndex_607A 0 "target_position" ;
VAL_ 1547 SubIndex_6077 0 "torque_actual_value" ;
VAL_ 1547 SubIndex_6071 0 "target_torque" ;
VAL_ 1547 SubIndex_606C 0 "velocity_actual_value" ;
VAL_ 1547 SubIndex_6067 0 "position_window" ;
VAL_ 1547 SubIndex_6064 0 "position_actual_value" ;
VAL_ 1547 SubIndex_6063 0 "position_actual_value" ;
VAL_ 1547 SubIndex_6062 0 "position_demand_value" ;
VAL_ 1547 SubIndex_6061 0 "modes_of_operation_display" ;
VAL_ 1547 SubIndex_6060 0 "modes_of_operation" ;
VAL_ 1547 SubIndex_605E 0 "fault_reaction_option_code" ;
VAL_ 1547 SubIndex_605D 0 "stop_option_code" ;
VAL_ 1547 SubIndex_605C 0 "disable_operation_option_code" ;
VAL_ 1547 SubIndex_605B 0 "shutdown_option_code" ;
VAL_ 1547 SubIndex_605A 0 "quick_stop_option_code" ;
VAL_ 1547 SubIndex_6049 2 "delta_time" 1 "delta_speed" 0 "NrOfObjects" ;
VAL_ 1547 SubIndex_6048 2 "delta_time" 1 "delta_speed" 0 "NrOfObjects" ;
VAL_ 1547 SubIndex_6046 2 "vl_velocity_max_amount" 1 "vl_velocity_min_amount" 0 "vl_velocity_min_max_amount_highest_subindex" ;
VAL_ 1547 SubIndex_6044 0 "vl_control_effort" ;
VAL_ 1547 SubIndex_6043 0 "vl_velocity_demand" ;
VAL_ 1547 SubIndex_6042 0 "vl_target_velocity" ;
VAL_ 1547 SubIndex_6041 0 "statusword" ;
VAL_ 1547 SubIndex_6040 0 "controlword" ;
VAL_ 1547 SubIndex_603F 0 "error_code" ;
VAL_ 1547 SubIndex_6007 0 "abort_connection_option_code" ;
VAL_ 1547 SubIndex_1A06 8 "PDO Mapping Entry" 7 "PDO Mapping Entry" 6 "PDO Mapping Entry" 5 "PDO Mapping Entry" 4 "PDO Mapping Entry" 3 "PDO Mapping Entry" 2 "PDO Mapping Entry" 1 "PDO Mapping Entry" 0 "NrOfMappedObjects" ;
VAL_ 1547 SubIndex_1A05 8 "PDO Mapping Entry" 7 "PDO Mapping Entry" 6 "PDO Mapping Entry" 5 "PDO Mapping Entry" 4 "PDO Mapping Entry" 3 "PDO Mapping Entry" 2 "PDO Mapping Entry" 1 "PDO Mapping Entry" 0 "NrOfMappedObjects" ;
VAL_ 1547 SubIndex_1A04 8 "PDO Mapping Entry" 7 "PDO Mapping Entry" 6 "PDO Mapping Entry" 5 "PDO Mapping Entry" 4 "PDO Mapping Entry" 3 "PDO Mapping Entry" 2 "PDO Mapping Entry" 1 "PDO Mapping Entry" 0 "NrOfMappedObjects" ;
VAL_ 1547 SubIndex_1A03 8 "PDO Mapping Entry" 7 "PDO Mapping Entry" 6 "PDO Mapping Entry" 5 "PDO Mapping Entry" 4 "PDO Mapping Entry" 3 "PDO Mapping Entry" 2 "PDO Mapping Entry" 1 "PDO Mapping Entry" 0 "NrOfMappedObjects" ;
VAL_ 1547 SubIndex_1A02 8 "PDO Mapping Entry" 7 "PDO Mapping Entry" 6 "PDO Mapping Entry" 5 "PDO Mapping Entry" 4 "PDO Mapping Entry" 3 "PDO Mapping Entry" 2 "PDO Mapping Entry" 1 "PDO Mapping Entry" 0 "NrOfMappedObjects" ;
VAL_ 1547 SubIndex_1A01 8 "PDO Mapping Entry" 7 "PDO Mapping Entry" 6 "PDO Mapping Entry" 5 "PDO Mapping Entry" 4 "PDO Mapping Entry" 3 "PDO Mapping Entry" 2 "PDO Mapping Entry" 1 "PDO Mapping Entry" 0 "NrOfMappedObjects" ;
VAL_ 1547 SubIndex_1A00 8 "PDO Mapping Entry" 7 "PDO Mapping Entry" 6 "PDO Mapping Entry" 5 "PDO Mapping Entry" 4 "PDO Mapping Entry" 3 "PDO Mapping Entry" 2 "PDO Mapping Entry" 1 "mappedObj1" 0 "NrOfMappedObjects" ;
VAL_ 1547 SubIndex_1806 5 "EventTimer" 2 "TransmissionType" 1 "COB-ID" 0 "NrOfEntries" ;
VAL_ 1547 SubIndex_1805 5 "EventTimer" 2 "TransmissionType" 1 "COB-ID" 0 "NrOfEntries" ;
VAL_ 1547 SubIndex_1804 5 "EventTimer" 2 "TransmissionType" 1 "COB-ID" 0 "NrOfEntries" ;
VAL_ 1547 SubIndex_1803 5 "EventTimer" 2 "TransmissionType" 1 "COB-ID" 0 "NrOfEntries" ;
VAL_ 1547 SubIndex_1802 5 "EventTimer" 2 "TransmissionType" 1 "COB-ID" 0 "NrOfEntries" ;
VAL_ 1547 SubIndex_1801 5 "EventTimer" 2 "TransmissionType" 1 "COB-ID" 0 "NrOfEntries" ;
VAL_ 1547 SubIndex_1800 5 "EventTimer" 2 "TransmissionType" 1 "COB-ID" 0 "NrOfEntries" ;
VAL_ 1547 SubIndex_1607 8 "PDO Mapping Entry" 7 "PDO Mapping Entry" 6 "PDO Mapping Entry" 5 "PDO Mapping Entry" 4 "PDO Mapping Entry" 3 "PDO Mapping Entry" 2 "PDO Mapping Entry" 1 "PDO Mapping Entry" 0 "NrOfMappedObjects" ;
VAL_ 1547 SubIndex_1606 8 "PDO Mapping Entry" 7 "PDO Mapping Entry" 6 "PDO Mapping Entry" 5 "PDO Mapping Entry" 4 "PDO Mapping Entry" 3 "PDO Mapping Entry" 2 "PDO Mapping Entry" 1 "PDO Mapping Entry" 0 "NrOfMappedObjects" ;
VAL_ 1547 SubIndex_1605 8 "PDO Mapping Entry" 7 "PDO Mapping Entry" 6 "PDO Mapping Entry" 5 "PDO Mapping Entry" 4 "PDO Mapping Entry" 3 "PDO Mapping Entry" 2 "PDO Mapping Entry" 1 "PDO Mapping Entry" 0 "NrOfMappedObjects" ;
VAL_ 1547 SubIndex_1604 8 "PDO Mapping Entry" 7 "PDO Mapping Entry" 6 "PDO Mapping Entry" 5 "PDO Mapping Entry" 4 "PDO Mapping Entry" 3 "PDO Mapping Entry" 2 "PDO Mapping Entry" 1 "PDO Mapping Entry" 0 "NrOfMappedObjects" ;
VAL_ 1547 SubIndex_1603 8 "PDO Mapping Entry" 7 "PDO Mapping Entry" 6 "PDO Mapping Entry" 5 "PDO Mapping Entry" 4 "PDO Mapping Entry" 3 "PDO Mapping Entry" 2 "PDO Mapping Entry" 1 "PDO Mapping Entry" 0 "NrOfMappedObjects" ;
VAL_ 1547 SubIndex_1602 8 "PDO Mapping Entry" 7 "PDO Mapping Entry" 6 "PDO Mapping Entry" 5 "PDO Mapping Entry" 4 "PDO Mapping Entry" 3 "PDO Mapping Entry" 2 "PDO Mapping Entry" 1 "PDO Mapping Entry" 0 "NrOfMappedObjects" ;
VAL_ 1547 SubIndex_1601 8 "PDO Mapping Entry" 7 "PDO Mapping Entry" 6 "PDO Mapping Entry" 5 "PDO Mapping Entry" 4 "PDO Mapping Entry" 3 "PDO Mapping Entry" 2 "PDO Mapping Entry" 1 "PDO Mapping Entry" 0 "NrOfMappedObjects" ;
VAL_ 1547 SubIndex_1600 8 "PDO Mapping Entry" 7 "PDO Mapping Entry" 6 "PDO Mapping Entry" 5 "PDO Mapping Entry" 4 "PDO Mapping Entry" 3 "PDO Mapping Entry" 2 "mappedObj2" 1 "mappedObj1" 0 "NrOfMappedObjects" ;
VAL_ 1547 SubIndex_1407 2 "TransmissionType" 1 "COB-ID" 0 "NrOfEntries" ;
VAL_ 1547 SubIndex_1406 2 "TransmissionType" 1 "COB-ID" 0 "NrOfEntries" ;
VAL_ 1547 SubIndex_1405 2 "TransmissionType" 1 "COB-ID" 0 "NrOfEntries" ;
VAL_ 1547 SubIndex_1404 2 "TransmissionType" 1 "COB-ID" 0 "NrOfEntries" ;
VAL_ 1547 SubIndex_1403 2 "TransmissionType" 1 "COB-ID" 0 "NrOfEntries" ;
VAL_ 1547 SubIndex_1402 2 "TransmissionType" 1 "COB-ID" 0 "NrOfEntries" ;
VAL_ 1547 SubIndex_1401 2 "TransmissionType" 1 "COB-ID" 0 "NrOfEntries" ;
VAL_ 1547 SubIndex_1400 2 "TransmissionType" 1 "COB-ID" 0 "NrOfEntries" ;
VAL_ 1547 SubIndex_1018 4 "Serial number" 3 "Revision number" 2 "Product Code" 1 "Vendor Id" 0 "number of entries" ;
VAL_ 1547 SubIndex_1017 0 "Producer Heartbeat Time" ;
VAL_ 1547 SubIndex_1016 9 "Consumer Heartbeat Time" 8 "Consumer Heartbeat Time" 7 "Consumer Heartbeat Time" 6 "Consumer Heartbeat Time" 5 "Consumer Heartbeat Time" 4 "Consumer Heartbeat Time" 3 "Consumer Heartbeat Time" 2 "Consumer Heartbeat Time" 1 "Consumer Heartbeat Time" 0 "NrOfObjects" ;
VAL_ 1547 SubIndex_1010 1 "Save all Parameters" 0 "Number of Entries" ;
VAL_ 1547 SubIndex_100D 0 "Life Time Factor" ;
VAL_ 1547 SubIndex_100C 0 "Guard Time" ;
VAL_ 1547 SubIndex_1007 0 "Sync_Window Length" ;
VAL_ 1547 SubIndex_1006 0 "Communication Cycle Period" ;
VAL_ 1547 SubIndex_1005 0 "COB-ID SYNC" ;
VAL_ 1547 SubIndex_1002 0 "Manufacturer Status Register" ;
VAL_ 1547 SubIndex_1001 0 "Error Register" ;
VAL_ 1547 SubIndex_1000 0 "Device Type" ;
VAL_ 1547 Index 25858 "supported_drive_modes" 25607 "motor_service_period" 25602 "motor_type" 24831 "target_velocity" 24830 "digital_outputs" 24829 "digital_inputs" 24702 "polarity" 24698 "target_position" 24695 "torque_actual_value" 24689 "target_torque" 24684 "velocity_actual_value" 24679 "position_window" 24676 "position_actual_value" 24675 "position_actual_value" 24674 "position_demand_value" 24673 "modes_of_operation_display" 24672 "modes_of_operation" 24670 "fault_reaction_option_code" 24669 "stop_option_code" 24668 "disable_operation_option_code" 24667 "shutdown_option_code" 24666 "quick_stop_option_code" 24649 "vl_velocity_deceleration" 24648 "vl_velocity_acceleration" 24646 "vl_velocity_min_max_amount" 24644 "vl_control_effort" 24643 "vl_velocity_demand" 24642 "vl_target_velocity" 24641 "statusword" 24640 "controlword" 24639 "error_code" 24583 "abort_connection_option_code" 6662 "TxPDOMapping" 6661 "TxPDOMapping" 6660 "TxPDOMapping" 6659 "TxPDOMapping" 6658 "TxPDOMapping" 6657 "TxPDOMapping" 6656 "TxPDOMapping" 6150 "TxPDOComPar" 6149 "TxPDOComPar" 6148 "TxPDOComPar" 6147 "TxPDOComPar" 6146 "TxPDOComPar" 6145 "TxPDOComPar" 6144 "TxPDOComPar" 5639 "RxPDOMapping" 5638 "RxPDOMapping" 5637 "RxPDOMapping" 5636 "RxPDOMapping" 5635 "RxPDOMapping" 5634 "RxPDOMapping" 5633 "RxPDOMapping" 5632 "RxPDOMapping" 5127 "RxPDOComPar" 5126 "RxPDOComPar" 5125 "RxPDOComPar" 5124 "RxPDOComPar" 5123 "RxPDOComPar" 5122 "RxPDOComPar" 5121 "RxPDOComPar" 5120 "RxPDOComPar" 4120 "Identity Object" 4119 "Producer Heartbeat Time" 4118 "Consumer Heartbeat Time" 4112 "Store Parameter Field" 4109 "Life Time Factor" 4108 "Guard Time" 4103 "Sync_Window Length" 4102 "Communication Cycle Period" 4101 "COB-ID SYNC" 4098 "Manufacturer Status Register" 4097 "Error Register" 4096 "Device Type" ;
VAL_ 1547 TransferType 1 "Expedited transfer" 0 "Normal transfer" ;
VAL_ 1547 SizeIndicator 1 "Size is indicated" 0 "Size is not indicated" ;
VAL_ 1547 CCS 2 "Upload" 1 "Download" ;
VAL_ 139 ErrorCode 61444 "(DS-402) Control error" 61443 "(DS-402) Control, stroke operation" 61442 "(DS-402) Control, sub-synchronous run" 61441 "(DS-402) Control, deceleration" 35328 "(DS-402) Control" 35072 "(DS-402) Winding controller - process data monitoring" 34816 "(DS-402) Winding controller" 34560 "(DS-402) Sync controller" 34322 "(DS-402) Positioning - reference limit" 34321 "(DS-402) Positioning - following error" 34304 "(DS-402) Positioning controller" 34048 "(DS-402) Position controller" 33792 "(DS-402) Velocity speed controller" 33585 "(DS-402) Torque fault" 33569 "(DS-402) Insufficient torque" 33555 "(DS-402) Standstill torque" 33554 "(DS-402) Difficult start up" 33553 "(DS-402) Excess torque" 33536 "(DS-402) Torque control" 30208 "(DS-402) Data storage (external)" 29984 "(DS-402) Serial interface no. 2" 29968 "(DS-402) Serial interface no. 1" 29952 "(DS-402) Communication" 29696 "(DS-402) Computation circuit" 29472 "(DS-402) Position" 29456 "(DS-402) Speed" 29447 "(DS-402) Incremental sensor 3 fault" 29446 "(DS-402) Incremental sensor 2 fault" 29445 "(DS-402) Incremental sensor 1 fault" 29444 "(DS-402) Resolver 2 fault" 29443 "(DS-402) Resolver 1 fault" 29442 "(DS-402) Tacho wrong polarity" 29441 "(DS-402) Tacho fault" 29440 "(DS-402) Sensor" 29184 "(DS-402) Measurement circuit  " 28963 "(DS-402) Motor tilted" 28962 "(DS-402) Motor error or commutation malfunction" 28961 "(DS-402) Motor blocked" 28960 "(DS-402) Motor" 28947 "(DS-402) Protective circuit brake chopper" 28946 "(DS-402) Over current brake chopper" 28945 "(DS-402) Failure brake chopper" 28944 "(DS-402) Brake chopper" 28928 "(DS-402) Power" 25376 "(DS-402) Parameter error" 25360 "(DS-402) Loss of parameters" 25359 "(DS-402) Reset watchdog - data record no. 15" 25358 "(DS-402) Reset watchdog - data record no. 14" 25357 "(DS-402) Reset watchdog - data record no. 13" 25356 "(DS-402) Reset watchdog - data record no. 12" 25355 "(DS-402) Reset watchdog - data record no. 11" 25354 "(DS-402) Reset watchdog - data record no. 10" 25353 "(DS-402) Reset watchdog - data record no. 9" 25352 "(DS-402) Reset watchdog - data record no. 8" 25351 "(DS-402) Reset watchdog - data record no. 7" 25350 "(DS-402) Reset watchdog - data record no. 6" 25349 "(DS-402) Reset watchdog - data record no. 5" 25348 "(DS-402) Reset watchdog - data record no. 4" 25347 "(DS-402) Reset watchdog - data record no. 3" 25346 "(DS-402) Reset watchdog - data record no. 2" 25345 "(DS-402) Reset watchdog - data record no. 1" 24592 "(DS-402) Software reset (watchdog)" 21808 "(DS-402) EEPROM" 21792 "(DS-402) ROM/EPROM" 21776 "(DS-402) RAM" 21760 "(DS-402) Hardware memory" 21593 "(DS-402) Fuses S9 = manufacturer-specific" 21592 "(DS-402) Fuses S8 = manufacturer-specific" 21591 "(DS-402) Fuses S7 = manufacturer-specific" 21590 "(DS-402) Fuses S6 = manufacturer-specific" 21589 "(DS-402) Fuses S5 = manufacturer-specific" 21588 "(DS-402) Fuses S4 = manufacturer-specific" 21587 "(DS-402) Fuses S3 = l3" 21586 "(DS-402) Fuses S2 = l2" 21585 "(DS-402) Fuses S1 = l1" 21584 "(DS-402) Fuses" 21573 "(DS-402) Contact 5 = manufacturer-specific" 21572 "(DS-402) Contact 4 = manufacturer-specific" 21571 "(DS-402) Contact 3 = manufacturer-specific" 21570 "(DS-402) Contact 2 = manufacturer-specific" 21569 "(DS-402) Contact 1 = manufacturer-specific" 21568 "(DS-402) Contacts" 21552 "(DS-402) Input stages" 21536 "(DS-402) Chopper" 21520 "(DS-402) Output stages" 21504 "(DS-402) Power section" 21248 "(DS-402) Operating unit" 21024 "(DS-402) Control, computing circuit" 21008 "(DS-402) Control, measurement circuit" 20992 "(DS-402) Control" 20768 "(DS-402) Supply intermediate circuit" 20761 "(DS-402) Supply low voltage U9 = manufacturer-specific" 20760 "(DS-402) Supply low voltage U8 = manufacturer-specific" 20759 "(DS-402) Supply low voltage U7 = manufacturer-specific" 20758 "(DS-402) Supply low voltage U6 = manufacturer-specific" 20757 "(DS-402) Supply low voltage U5 = manufacturer-specific" 20756 "(DS-402) Supply low voltage U4 = manufacturer-specific" 20755 "(DS-402) Supply low voltage U3 = supply +5 V" 20754 "(DS-402) Supply low voltage U2 = supply +24V" 20753 "(DS-402) Supply low voltage U1 = supply ±15V" 20752 "(DS-402) Supply low voltage" 20736 "(DS-402) Supply" 17440 "(DS-402) Too low temperature supply" 17424 "(DS-402) Excess temperature supply" 17408 "(DS-402) Temperature supply" 17184 "(DS-402) Too low temperature drive" 17168 "(DS-402) Excess temperature drive" 17152 "(DS-402) Temperature drive" 16928 "(DS-402) Field circ. interrupted, too low temperature device" 16912 "(DS-402) Field circ. interrupted, excess temperature device" 16704 "(DS-402) Field circ. interrupted, temperature air outlet" 16688 "(DS-402) Field circ. interrupted, temperature supply air" 16672 "(DS-402) Field circ. interrupted, too low ambient temperature" 16656 "(DS-402) Field circ. interrupted, Excess ambient temperature" 13105 "(DS-402) Field circuit interrupted" 13104 "(DS-402) Field circuit" 13089 "(DS-402) Armature circuit interrupted" 13088 "(DS-402) Armature circuit" 13075 "(DS-402) Output over-voltage phase W " 13074 "(DS-402) Output over-voltage phase V " 13073 "(DS-402) Output over-voltage phase U " 13072 "(DS-402) Output over-voltage" 12848 "(DS-402) Load error" 12834 "(DS-402) DC link under-voltage no. 2" 12833 "(DS-402) DC link under-voltage no. 1" 12832 "(DS-402) DC link under-voltage" 12818 "(DS-402) DC link over voltage no. 2" 12817 "(DS-402) DC link over-voltage no. 1" 12816 "(DS-402) DC link over-voltage" 12610 "(DS-402) Mains frequency too small" 12609 "(DS-402) Mains frequency too great" 12608 "(DS-402) Mains frequency" 12596 "(DS-402) Phase sequence" 12595 "(DS-402) Phase failure L3" 12594 "(DS-402) Phase failure L2" 12593 "(DS-402) Phase failure L1" 12592 "(DS-402) Phase failure" 12579 "(DS-402) Mains under-voltage phase L3" 12578 "(DS-402) Mains under-voltage phase L2" 12577 "(DS-402) Mains under-voltage phase L1" 12576 "(DS-402) Mains under-voltage" 12563 "(DS-402) Mains over-voltage phase L3 " 12562 "(DS-402) Mains over-voltage phase L2" 12561 "(DS-402) Mains over-voltage phase L1" 12560 "(DS-402) Mains over-voltage" 9041 "(DS-402) Load level warning (I2t, thermal state)" 9040 "(DS-402) Load level fault (I2t, thermal state)" 9027 "(DS-402) Earth leakage (motor-side) phase W-U" 9026 "(DS-402) Earth leakage (motor-side) phase V-W" 9025 "(DS-402) Short circuit (motor-side) phases U-V" 9024 "(DS-402) Short circuit (motor-side)" 9011 "(DS-402) Earth leakage (motor-side) phase W" 9010 "(DS-402) Earth leakage (motor-side) phase V" 9009 "(DS-402) Earth leakage (motor-side) phase U" 9008 "(DS-402) Earth leakage (motor-side)" 8992 "(DS-402) Short circuit/earth leakage (motor-side)" 8978 "(DS-402) Device internal, continuous over current no. 2" 8977 "(DS-402) Device internal, continuous over current no. 1" 8976 "(DS-402) Device internal, continuous over current" 8784 "(DS-402) Short circuit (device internal) " 8768 "(DS-402) Earth leakage (device internal)" 8752 "(DS-402) Short circuit/earth leakage (device internal)" 8738 "(DS-402) Continuous over current no.2" 8737 "(DS-402) Continuous over current no.1" 8736 "(DS-402) Continuous over current (device internal)" 8724 "(DS-402) Short circuit (input), over-current in the sequence" 8723 "(DS-402) Short circuit (input), over-current in ramp function" 8722 "(DS-402) Short circuit (input), internal current no.2" 8721 "(DS-402) Short circuit (input), internal current no.1" 8499 "(DS-402) Short circuit phases (input) L3-L1" 8498 "(DS-402) Short circuit phases (input) L2-L3" 8497 "(DS-402) Short circuit phases (input) L1-L2" 8496 "(DS-402) Short circuit (input)" 8483 "(DS-402) Earth leakage (input) phase L3" 8482 "(DS-402) Earth leakage (input) phase L2" 8481 "(DS-402) Earth leakage (input) phase L1" 8480 "(DS-402) Earth leakage (input)" 8464 "(DS-402) Short circuit/earth leakage (input)" 33360 "RPDO timeout" 33344 "Unexpected SYNC data length" 33328 "DAM MPDO not processed, destination object not available" 33312 "PDO length exceeded" 33296 "PDO not processed due to length error" 33104 "Transmit COB-ID collision" 33088 "Recovered from bus off state" 33072 "Life guard error or heartbeat error" 33056 "CAN in error passive mode" 33040 "CAN overrun (objects lost)" ;
VAL_ 1802 State 127 "PreOperational" 5 "Operational" 4 "Stopped" 0 "Bootup" ;
VAL_ 1418 SubIndex_6200 8 "DigOutput8_8" 7 "DigOutput8_7" 6 "DigOutput8_6" 5 "DigOutput8_5" 4 "DigOutput8_4" 3 "DigOutput8_3" 2 "DigOutput8_2" 1 "LadderLock" 0 "NrOfObjects" ;
VAL_ 1418 SubIndex_6000 8 "DigInput8_8" 7 "DigInput8_7" 6 "DigInput8_6" 5 "DigInput8_5" 4 "Support_Down" 3 "Support_Up" 2 "Ladder_Down" 1 "Ladder_Up" 0 "NrOfObjects" ;
VAL_ 1418 SubIndex_1A01 0 "NrOfMappedObjects" ;
VAL_ 1418 SubIndex_1A00 5 "mappedObj5" 4 "mappedObj4" 3 "mappedObj3" 2 "mappedObj2" 1 "mappedObj1" 0 "NrOfMappedObjects" ;
VAL_ 1418 SubIndex_1801 5 "EventTimer" 2 "TransmissionType" 1 "COB-ID" 0 "NrOfEntries" ;
VAL_ 1418 SubIndex_1800 5 "EventTimer" 2 "TransmissionType" 1 "COB-ID" 0 "NrOfEntries" ;
VAL_ 1418 SubIndex_1601 0 "NrOfMappedObjects" ;
VAL_ 1418 SubIndex_1600 0 "NrOfMappedObjects" ;
VAL_ 1418 SubIndex_1401 2 "TransmissionType" 1 "COB-ID" 0 "NrOfEntries" ;
VAL_ 1418 SubIndex_1400 2 "TransmissionType" 1 "COB-ID" 0 "NrOfEntries" ;
VAL_ 1418 SubIndex_1018 4 "Serial number" 3 "Revision number" 2 "Product Code" 1 "Vendor Id" 0 "number of entries" ;
VAL_ 1418 SubIndex_1017 0 "Producer Heartbeat Time" ;
VAL_ 1418 SubIndex_1016 6 "Consumer Heartbeat Time" 5 "Consumer Heartbeat Time" 4 "Consumer Heartbeat Time" 3 "Consumer Heartbeat Time" 2 "Consumer Heartbeat Time" 1 "Consumer Heartbeat Time" 0 "NrOfObjects" ;
VAL_ 1418 SubIndex_1010 1 "Save all Parameters" 0 "Number of Entries" ;
VAL_ 1418 SubIndex_100D 0 "Life Time Factor" ;
VAL_ 1418 SubIndex_100C 0 "Guard Time" ;
VAL_ 1418 SubIndex_1007 0 "Sync_Window Length" ;
VAL_ 1418 SubIndex_1006 0 "Communication Cycle Period" ;
VAL_ 1418 SubIndex_1005 0 "COB-ID SYNC" ;
VAL_ 1418 SubIndex_1002 0 "Manufacturer Status Register" ;
VAL_ 1418 SubIndex_1001 0 "Error Register" ;
VAL_ 1418 SubIndex_1000 0 "Device Type" ;
VAL_ 1418 Index 25088 "Write State 8 Output Lines" 24576 "Read State 8 Input Lines" 6657 "TxPDOMapping" 6656 "TxPDOMapping" 6145 "TxPDOComPar" 6144 "TxPDOComPar" 5633 "RxPDOMapping" 5632 "RxPDOMapping" 5121 "RxPDOComPar" 5120 "RxPDOComPar" 4120 "Identity Object" 4119 "Producer Heartbeat Time" 4118 "Consumer Heartbeat Time" 4112 "Store Parameter Field" 4109 "Life Time Factor" 4108 "Guard Time" 4103 "Sync_Window Length" 4102 "Communication Cycle Period" 4101 "COB-ID SYNC" 4098 "Manufacturer Status Register" 4097 "Error Register" 4096 "Device Type" ;
VAL_ 1418 TransferType 1 "Expedited transfer" 0 "Normal transfer" ;
VAL_ 1418 SizeIndicator 1 "Size is indicated" 0 "Size is not indicated" ;
VAL_ 1418 SCS 2 "Upload" 1 "Download" ;
VAL_ 1546 SubIndex_6200 8 "DigOutput8_8" 7 "DigOutput8_7" 6 "DigOutput8_6" 5 "DigOutput8_5" 4 "DigOutput8_4" 3 "DigOutput8_3" 2 "DigOutput8_2" 1 "LadderLock" 0 "NrOfObjects" ;
VAL_ 1546 SubIndex_6000 8 "DigInput8_8" 7 "DigInput8_7" 6 "DigInput8_6" 5 "DigInput8_5" 4 "Support_Down" 3 "Support_Up" 2 "Ladder_Down" 1 "Ladder_Up" 0 "NrOfObjects" ;
VAL_ 1546 SubIndex_1A01 0 "NrOfMappedObjects" ;
VAL_ 1546 SubIndex_1A00 5 "mappedObj5" 4 "mappedObj4" 3 "mappedObj3" 2 "mappedObj2" 1 "mappedObj1" 0 "NrOfMappedObjects" ;
VAL_ 1546 SubIndex_1801 5 "EventTimer" 2 "TransmissionType" 1 "COB-ID" 0 "NrOfEntries" ;
VAL_ 1546 SubIndex_1800 5 "EventTimer" 2 "TransmissionType" 1 "COB-ID" 0 "NrOfEntries" ;
VAL_ 1546 SubIndex_1601 0 "NrOfMappedObjects" ;
VAL_ 1546 SubIndex_1600 0 "NrOfMappedObjects" ;
VAL_ 1546 SubIndex_1401 2 "TransmissionType" 1 "COB-ID" 0 "NrOfEntries" ;
VAL_ 1546 SubIndex_1400 2 "TransmissionType" 1 "COB-ID" 0 "NrOfEntries" ;
VAL_ 1546 SubIndex_1018 4 "Serial number" 3 "Revision number" 2 "Product Code" 1 "Vendor Id" 0 "number of entries" ;
VAL_ 1546 SubIndex_1017 0 "Producer Heartbeat Time" ;
VAL_ 1546 SubIndex_1016 6 "Consumer Heartbeat Time" 5 "Consumer Heartbeat Time" 4 "Consumer Heartbeat Time" 3 "Consumer Heartbeat Time" 2 "Consumer Heartbeat Time" 1 "Consumer Heartbeat Time" 0 "NrOfObjects" ;
VAL_ 1546 SubIndex_1010 1 "Save all Parameters" 0 "Number of Entries" ;
VAL_ 1546 SubIndex_100D 0 "Life Time Factor" ;
VAL_ 1546 SubIndex_100C 0 "Guard Time" ;
VAL_ 1546 SubIndex_1007 0 "Sync_Window Length" ;
VAL_ 1546 SubIndex_1006 0 "Communication Cycle Period" ;
VAL_ 1546 SubIndex_1005 0 "COB-ID SYNC" ;
VAL_ 1546 SubIndex_1002 0 "Manufacturer Status Register" ;
VAL_ 1546 SubIndex_1001 0 "Error Register" ;
VAL_ 1546 SubIndex_1000 0 "Device Type" ;
VAL_ 1546 Index 25088 "Write State 8 Output Lines" 24576 "Read State 8 Input Lines" 6657 "TxPDOMapping" 6656 "TxPDOMapping" 6145 "TxPDOComPar" 6144 "TxPDOComPar" 5633 "RxPDOMapping" 5632 "RxPDOMapping" 5121 "RxPDOComPar" 5120 "RxPDOComPar" 4120 "Identity Object" 4119 "Producer Heartbeat Time" 4118 "Consumer Heartbeat Time" 4112 "Store Parameter Field" 4109 "Life Time Factor" 4108 "Guard Time" 4103 "Sync_Window Length" 4102 "Communication Cycle Period" 4101 "COB-ID SYNC" 4098 "Manufacturer Status Register" 4097 "Error Register" 4096 "Device Type" ;
VAL_ 1546 TransferType 1 "Expedited transfer" 0 "Normal transfer" ;
VAL_ 1546 SizeIndicator 1 "Size is indicated" 0 "Size is not indicated" ;
VAL_ 1546 CCS 2 "Upload" 1 "Download" ;
VAL_ 138 ErrorCode 13088 "(DS-401) Output voltage too low" 13072 "(DS-401) Output voltage too high" 12832 "(DS-401) Internal voltage too low" 12816 "(DS-401) Internal voltage too high" 12576 "(DS-401) Input voltage too low" 12560 "(DS-401) Input voltage too high" 9008 "(DS-401) Load dump at outputs" 8992 "(DS-401) Short circuit at outputs" 8976 "(DS-401) Current at outputs too high (overload)" 128 "(DS-401) Warning: Analogue inputs disabled" 33360 "RPDO timeout" 33344 "Unexpected SYNC data length" 33328 "DAM MPDO not processed, destination object not available" 33312 "PDO length exceeded" 33296 "PDO not processed due to length error" 33104 "Transmit COB-ID collision" 33088 "Recovered from bus off state" 33072 "Life guard error or heartbeat error" 33056 "CAN in error passive mode" 33040 "CAN overrun (objects lost)" ;
VAL_ 1804 State 127 "PreOperational" 5 "Operational" 4 "Stopped" 0 "Bootup" ;
SG_MUL_VAL_ 1419 supported_drive_modes_6502 SubIndex_6502 0-0;
SG_MUL_VAL_ 1419 SubIndex_6502 Index 25858-25858;
SG_MUL_VAL_ 1419 motor_service_period_6407 SubIndex_6407 0-0;
SG_MUL_VAL_ 1419 SubIndex_6407 Index 25607-25607;
SG_MUL_VAL_ 1419 motor_type_6402 SubIndex_6402 0-0;
SG_MUL_VAL_ 1419 SubIndex_6402 Index 25602-25602;
SG_MUL_VAL_ 1419 target_velocity_60FF SubIndex_60FF 0-0;
SG_MUL_VAL_ 1419 SubIndex_60FF Index 24831-24831;
SG_MUL_VAL_ 1419 bitmask_60FE_02 SubIndex_60FE 2-2;
SG_MUL_VAL_ 1419 physical_outputs_60FE_01 SubIndex_60FE 1-1;
SG_MUL_VAL_ 1419 NrOfObjects_60FE_00 SubIndex_60FE 0-0;
SG_MUL_VAL_ 1419 SubIndex_60FE Index 24830-24830;
SG_MUL_VAL_ 1419 digital_inputs_60FD SubIndex_60FD 0-0;
SG_MUL_VAL_ 1419 SubIndex_60FD Index 24829-24829;
SG_MUL_VAL_ 1419 polarity_607E SubIndex_607E 0-0;
SG_MUL_VAL_ 1419 SubIndex_607E Index 24702-24702;
SG_MUL_VAL_ 1419 target_position_607A SubIndex_607A 0-0;
SG_MUL_VAL_ 1419 SubIndex_607A Index 24698-24698;
SG_MUL_VAL_ 1419 torque_actual_value_6077 SubIndex_6077 0-0;
SG_MUL_VAL_ 1419 SubIndex_6077 Index 24695-24695;
SG_MUL_VAL_ 1419 target_torque_6071 SubIndex_6071 0-0;
SG_MUL_VAL_ 1419 SubIndex_6071 Index 24689-24689;
SG_MUL_VAL_ 1419 velocity_actual_value_606C SubIndex_606C 0-0;
SG_MUL_VAL_ 1419 SubIndex_606C Index 24684-24684;
SG_MUL_VAL_ 1419 position_window_6067 SubIndex_6067 0-0;
SG_MUL_VAL_ 1419 SubIndex_6067 Index 24679-24679;
SG_MUL_VAL_ 1419 position_actual_value_6064 SubIndex_6064 0-0;
SG_MUL_VAL_ 1419 SubIndex_6064 Index 24676-24676;
SG_MUL_VAL_ 1419 position_actual_value_6063 SubIndex_6063 0-0;
SG_MUL_VAL_ 1419 SubIndex_6063 Index 24675-24675;
SG_MUL_VAL_ 1419 position_demand_value_6062 SubIndex_6062 0-0;
SG_MUL_VAL_ 1419 SubIndex_6062 Index 24674-24674;
SG_MUL_VAL_ 1419 modes_of_operation_display_6061 SubIndex_6061 0-0;
SG_MUL_VAL_ 1419 SubIndex_6061 Index 24673-24673;
SG_MUL_VAL_ 1419 modes_of_operation_6060 SubIndex_6060 0-0;
SG_MUL_VAL_ 1419 SubIndex_6060 Index 24672-24672;
SG_MUL_VAL_ 1419 fault_reaction_option_code_605E SubIndex_605E 0-0;
SG_MUL_VAL_ 1419 SubIndex_605E Index 24670-24670;
SG_MUL_VAL_ 1419 stop_option_code_605D SubIndex_605D 0-0;
SG_MUL_VAL_ 1419 SubIndex_605D Index 24669-24669;
SG_MUL_VAL_ 1419 disable_operation_option_code_60 SubIndex_605C 0-0;
SG_MUL_VAL_ 1419 SubIndex_605C Index 24668-24668;
SG_MUL_VAL_ 1419 shutdown_option_code_605B SubIndex_605B 0-0;
SG_MUL_VAL_ 1419 SubIndex_605B Index 24667-24667;
SG_MUL_VAL_ 1419 quick_stop_option_code_605A SubIndex_605A 0-0;
SG_MUL_VAL_ 1419 SubIndex_605A Index 24666-24666;
SG_MUL_VAL_ 1419 delta_time_6049_02 SubIndex_6049 2-2;
SG_MUL_VAL_ 1419 delta_speed_6049_01 SubIndex_6049 1-1;
SG_MUL_VAL_ 1419 NrOfObjects_6049_00 SubIndex_6049 0-0;
SG_MUL_VAL_ 1419 SubIndex_6049 Index 24649-24649;
SG_MUL_VAL_ 1419 delta_time_6048_02 SubIndex_6048 2-2;
SG_MUL_VAL_ 1419 delta_speed_6048_01 SubIndex_6048 1-1;
SG_MUL_VAL_ 1419 NrOfObjects_6048_00 SubIndex_6048 0-0;
SG_MUL_VAL_ 1419 SubIndex_6048 Index 24648-24648;
SG_MUL_VAL_ 1419 vl_velocity_max_amount_6046_02 SubIndex_6046 2-2;
SG_MUL_VAL_ 1419 vl_velocity_min_amount_6046_01 SubIndex_6046 1-1;
SG_MUL_VAL_ 1419 vl_velocity_min_max_amount_highe SubIndex_6046 0-0;
SG_MUL_VAL_ 1419 SubIndex_6046 Index 24646-24646;
SG_MUL_VAL_ 1419 vl_control_effort_6044 SubIndex_6044 0-0;
SG_MUL_VAL_ 1419 SubIndex_6044 Index 24644-24644;
SG_MUL_VAL_ 1419 vl_velocity_demand_6043 SubIndex_6043 0-0;
SG_MUL_VAL_ 1419 SubIndex_6043 Index 24643-24643;
SG_MUL_VAL_ 1419 vl_target_velocity_6042 SubIndex_6042 0-0;
SG_MUL_VAL_ 1419 SubIndex_6042 Index 24642-24642;
SG_MUL_VAL_ 1419 statusword_6041 SubIndex_6041 0-0;
SG_MUL_VAL_ 1419 SubIndex_6041 Index 24641-24641;
SG_MUL_VAL_ 1419 controlword_6040 SubIndex_6040 0-0;
SG_MUL_VAL_ 1419 SubIndex_6040 Index 24640-24640;
SG_MUL_VAL_ 1419 error_code_603F SubIndex_603F 0-0;
SG_MUL_VAL_ 1419 SubIndex_603F Index 24639-24639;
SG_MUL_VAL_ 1419 abort_connection_option_code_600 SubIndex_6007 0-0;
SG_MUL_VAL_ 1419 SubIndex_6007 Index 24583-24583;
SG_MUL_VAL_ 1419 PDO_Mapping_Entry_1A06_08 SubIndex_1A06 8-8;
SG_MUL_VAL_ 1419 PDO_Mapping_Entry_1A06_07 SubIndex_1A06 7-7;
SG_MUL_VAL_ 1419 PDO_Mapping_Entry_1A06_06 SubIndex_1A06 6-6;
SG_MUL_VAL_ 1419 PDO_Mapping_Entry_1A06_05 SubIndex_1A06 5-5;
SG_MUL_VAL_ 1419 PDO_Mapping_Entry_1A06_04 SubIndex_1A06 4-4;
SG_MUL_VAL_ 1419 PDO_Mapping_Entry_1A06_03 SubIndex_1A06 3-3;
SG_MUL_VAL_ 1419 PDO_Mapping_Entry_1A06_02 SubIndex_1A06 2-2;
SG_MUL_VAL_ 1419 PDO_Mapping_Entry_1A06_01 SubIndex_1A06 1-1;
SG_MUL_VAL_ 1419 NrOfMappedObjects_1A06_00 SubIndex_1A06 0-0;
SG_MUL_VAL_ 1419 SubIndex_1A06 Index 6662-6662;
SG_MUL_VAL_ 1419 PDO_Mapping_Entry_1A05_08 SubIndex_1A05 8-8;
SG_MUL_VAL_ 1419 PDO_Mapping_Entry_1A05_07 SubIndex_1A05 7-7;
SG_MUL_VAL_ 1419 PDO_Mapping_Entry_1A05_06 SubIndex_1A05 6-6;
SG_MUL_VAL_ 1419 PDO_Mapping_Entry_1A05_05 SubIndex_1A05 5-5;
SG_MUL_VAL_ 1419 PDO_Mapping_Entry_1A05_04 SubIndex_1A05 4-4;
SG_MUL_VAL_ 1419 PDO_Mapping_Entry_1A05_03 SubIndex_1A05 3-3;
SG_MUL_VAL_ 1419 PDO_Mapping_Entry_1A05_02 SubIndex_1A05 2-2;
SG_MUL_VAL_ 1419 PDO_Mapping_Entry_1A05_01 SubIndex_1A05 1-1;
SG_MUL_VAL_ 1419 NrOfMappedObjects_1A05_00 SubIndex_1A05 0-0;
SG_MUL_VAL_ 1419 SubIndex_1A05 Index 6661-6661;
SG_MUL_VAL_ 1419 PDO_Mapping_Entry_1A04_08 SubIndex_1A04 8-8;
SG_MUL_VAL_ 1419 PDO_Mapping_Entry_1A04_07 SubIndex_1A04 7-7;
SG_MUL_VAL_ 1419 PDO_Mapping_Entry_1A04_06 SubIndex_1A04 6-6;
SG_MUL_VAL_ 1419 PDO_Mapping_Entry_1A04_05 SubIndex_1A04 5-5;
SG_MUL_VAL_ 1419 PDO_Mapping_Entry_1A04_04 SubIndex_1A04 4-4;
SG_MUL_VAL_ 1419 PDO_Mapping_Entry_1A04_03 SubIndex_1A04 3-3;
SG_MUL_VAL_ 1419 PDO_Mapping_Entry_1A04_02 SubIndex_1A04 2-2;
SG_MUL_VAL_ 1419 PDO_Mapping_Entry_1A04_01 SubIndex_1A04 1-1;
SG_MUL_VAL_ 1419 NrOfMappedObjects_1A04_00 SubIndex_1A04 0-0;
SG_MUL_VAL_ 1419 SubIndex_1A04 Index 6660-6660;
SG_MUL_VAL_ 1419 PDO_Mapping_Entry_1A03_08 SubIndex_1A03 8-8;
SG_MUL_VAL_ 1419 PDO_Mapping_Entry_1A03_07 SubIndex_1A03 7-7;
SG_MUL_VAL_ 1419 PDO_Mapping_Entry_1A03_06 SubIndex_1A03 6-6;
SG_MUL_VAL_ 1419 PDO_Mapping_Entry_1A03_05 SubIndex_1A03 5-5;
SG_MUL_VAL_ 1419 PDO_Mapping_Entry_1A03_04 SubIndex_1A03 4-4;
SG_MUL_VAL_ 1419 PDO_Mapping_Entry_1A03_03 SubIndex_1A03 3-3;
SG_MUL_VAL_ 1419 PDO_Mapping_Entry_1A03_02 SubIndex_1A03 2-2;
SG_MUL_VAL_ 1419 PDO_Mapping_Entry_1A03_01 SubIndex_1A03 1-1;
SG_MUL_VAL_ 1419 NrOfMappedObjects_1A03_00 SubIndex_1A03 0-0;
SG_MUL_VAL_ 1419 SubIndex_1A03 Index 6659-6659;
SG_MUL_VAL_ 1419 PDO_Mapping_Entry_1A02_08 SubIndex_1A02 8-8;
SG_MUL_VAL_ 1419 PDO_Mapping_Entry_1A02_07 SubIndex_1A02 7-7;
SG_MUL_VAL_ 1419 PDO_Mapping_Entry_1A02_06 SubIndex_1A02 6-6;
SG_MUL_VAL_ 1419 PDO_Mapping_Entry_1A02_05 SubIndex_1A02 5-5;
SG_MUL_VAL_ 1419 PDO_Mapping_Entry_1A02_04 SubIndex_1A02 4-4;
SG_MUL_VAL_ 1419 PDO_Mapping_Entry_1A02_03 SubIndex_1A02 3-3;
SG_MUL_VAL_ 1419 PDO_Mapping_Entry_1A02_02 SubIndex_1A02 2-2;
SG_MUL_VAL_ 1419 PDO_Mapping_Entry_1A02_01 SubIndex_1A02 1-1;
SG_MUL_VAL_ 1419 NrOfMappedObjects_1A02_00 SubIndex_1A02 0-0;
SG_MUL_VAL_ 1419 SubIndex_1A02 Index 6658-6658;
SG_MUL_VAL_ 1419 PDO_Mapping_Entry_1A01_08 SubIndex_1A01 8-8;
SG_MUL_VAL_ 1419 PDO_Mapping_Entry_1A01_07 SubIndex_1A01 7-7;
SG_MUL_VAL_ 1419 PDO_Mapping_Entry_1A01_06 SubIndex_1A01 6-6;
SG_MUL_VAL_ 1419 PDO_Mapping_Entry_1A01_05 SubIndex_1A01 5-5;
SG_MUL_VAL_ 1419 PDO_Mapping_Entry_1A01_04 SubIndex_1A01 4-4;
SG_MUL_VAL_ 1419 PDO_Mapping_Entry_1A01_03 SubIndex_1A01 3-3;
SG_MUL_VAL_ 1419 PDO_Mapping_Entry_1A01_02 SubIndex_1A01 2-2;
SG_MUL_VAL_ 1419 PDO_Mapping_Entry_1A01_01 SubIndex_1A01 1-1;
SG_MUL_VAL_ 1419 NrOfMappedObjects_1A01_00 SubIndex_1A01 0-0;
SG_MUL_VAL_ 1419 SubIndex_1A01 Index 6657-6657;
SG_MUL_VAL_ 1419 PDO_Mapping_Entry_1A00_08 SubIndex_1A00 8-8;
SG_MUL_VAL_ 1419 PDO_Mapping_Entry_1A00_07 SubIndex_1A00 7-7;
SG_MUL_VAL_ 1419 PDO_Mapping_Entry_1A00_06 SubIndex_1A00 6-6;
SG_MUL_VAL_ 1419 PDO_Mapping_Entry_1A00_05 SubIndex_1A00 5-5;
SG_MUL_VAL_ 1419 PDO_Mapping_Entry_1A00_04 SubIndex_1A00 4-4;
SG_MUL_VAL_ 1419 PDO_Mapping_Entry_1A00_03 SubIndex_1A00 3-3;
SG_MUL_VAL_ 1419 PDO_Mapping_Entry_1A00_02 SubIndex_1A00 2-2;
SG_MUL_VAL_ 1419 mappedObj1_1A00_01 SubIndex_1A00 1-1;
SG_MUL_VAL_ 1419 NrOfMappedObjects_1A00_00 SubIndex_1A00 0-0;
SG_MUL_VAL_ 1419 SubIndex_1A00 Index 6656-6656;
SG_MUL_VAL_ 1419 EventTimer_1806_05 SubIndex_1806 5-5;
SG_MUL_VAL_ 1419 TransmissionType_1806_02 SubIndex_1806 2-2;
SG_MUL_VAL_ 1419 COB_ID_1806_01 SubIndex_1806 1-1;
SG_MUL_VAL_ 1419 NrOfEntries_1806_00 SubIndex_1806 0-0;
SG_MUL_VAL_ 1419 SubIndex_1806 Index 6150-6150;
SG_MUL_VAL_ 1419 EventTimer_1805_05 SubIndex_1805 5-5;
SG_MUL_VAL_ 1419 TransmissionType_1805_02 SubIndex_1805 2-2;
SG_MUL_VAL_ 1419 COB_ID_1805_01 SubIndex_1805 1-1;
SG_MUL_VAL_ 1419 NrOfEntries_1805_00 SubIndex_1805 0-0;
SG_MUL_VAL_ 1419 SubIndex_1805 Index 6149-6149;
SG_MUL_VAL_ 1419 EventTimer_1804_05 SubIndex_1804 5-5;
SG_MUL_VAL_ 1419 TransmissionType_1804_02 SubIndex_1804 2-2;
SG_MUL_VAL_ 1419 COB_ID_1804_01 SubIndex_1804 1-1;
SG_MUL_VAL_ 1419 NrOfEntries_1804_00 SubIndex_1804 0-0;
SG_MUL_VAL_ 1419 SubIndex_1804 Index 6148-6148;
SG_MUL_VAL_ 1419 EventTimer_1803_05 SubIndex_1803 5-5;
SG_MUL_VAL_ 1419 TransmissionType_1803_02 SubIndex_1803 2-2;
SG_MUL_VAL_ 1419 COB_ID_1803_01 SubIndex_1803 1-1;
SG_MUL_VAL_ 1419 NrOfEntries_1803_00 SubIndex_1803 0-0;
SG_MUL_VAL_ 1419 SubIndex_1803 Index 6147-6147;
SG_MUL_VAL_ 1419 EventTimer_1802_05 SubIndex_1802 5-5;
SG_MUL_VAL_ 1419 TransmissionType_1802_02 SubIndex_1802 2-2;
SG_MUL_VAL_ 1419 COB_ID_1802_01 SubIndex_1802 1-1;
SG_MUL_VAL_ 1419 NrOfEntries_1802_00 SubIndex_1802 0-0;
SG_MUL_VAL_ 1419 SubIndex_1802 Index 6146-6146;
SG_MUL_VAL_ 1419 EventTimer_1801_05 SubIndex_1801 5-5;
SG_MUL_VAL_ 1419 TransmissionType_1801_02 SubIndex_1801 2-2;
SG_MUL_VAL_ 1419 COB_ID_1801_01 SubIndex_1801 1-1;
SG_MUL_VAL_ 1419 NrOfEntries_1801_00 SubIndex_1801 0-0;
SG_MUL_VAL_ 1419 SubIndex_1801 Index 6145-6145;
SG_MUL_VAL_ 1419 EventTimer_1800_05 SubIndex_1800 5-5;
SG_MUL_VAL_ 1419 TransmissionType_1800_02 SubIndex_1800 2-2;
SG_MUL_VAL_ 1419 COB_ID_1800_01 SubIndex_1800 1-1;
SG_MUL_VAL_ 1419 NrOfEntries_1800_00 SubIndex_1800 0-0;
SG_MUL_VAL_ 1419 SubIndex_1800 Index 6144-6144;
SG_MUL_VAL_ 1419 PDO_Mapping_Entry_1607_08 SubIndex_1607 8-8;
SG_MUL_VAL_ 1419 PDO_Mapping_Entry_1607_07 SubIndex_1607 7-7;
SG_MUL_VAL_ 1419 PDO_Mapping_Entry_1607_06 SubIndex_1607 6-6;
SG_MUL_VAL_ 1419 PDO_Mapping_Entry_1607_05 SubIndex_1607 5-5;
SG_MUL_VAL_ 1419 PDO_Mapping_Entry_1607_04 SubIndex_1607 4-4;
SG_MUL_VAL_ 1419 PDO_Mapping_Entry_1607_03 SubIndex_1607 3-3;
SG_MUL_VAL_ 1419 PDO_Mapping_Entry_1607_02 SubIndex_1607 2-2;
SG_MUL_VAL_ 1419 PDO_Mapping_Entry_1607_01 SubIndex_1607 1-1;
SG_MUL_VAL_ 1419 NrOfMappedObjects_1607_00 SubIndex_1607 0-0;
SG_MUL_VAL_ 1419 SubIndex_1607 Index 5639-5639;
SG_MUL_VAL_ 1419 PDO_Mapping_Entry_1606_08 SubIndex_1606 8-8;
SG_MUL_VAL_ 1419 PDO_Mapping_Entry_1606_07 SubIndex_1606 7-7;
SG_MUL_VAL_ 1419 PDO_Mapping_Entry_1606_06 SubIndex_1606 6-6;
SG_MUL_VAL_ 1419 PDO_Mapping_Entry_1606_05 SubIndex_1606 5-5;
SG_MUL_VAL_ 1419 PDO_Mapping_Entry_1606_04 SubIndex_1606 4-4;
SG_MUL_VAL_ 1419 PDO_Mapping_Entry_1606_03 SubIndex_1606 3-3;
SG_MUL_VAL_ 1419 PDO_Mapping_Entry_1606_02 SubIndex_1606 2-2;
SG_MUL_VAL_ 1419 PDO_Mapping_Entry_1606_01 SubIndex_1606 1-1;
SG_MUL_VAL_ 1419 NrOfMappedObjects_1606_00 SubIndex_1606 0-0;
SG_MUL_VAL_ 1419 SubIndex_1606 Index 5638-5638;
SG_MUL_VAL_ 1419 PDO_Mapping_Entry_1605_08 SubIndex_1605 8-8;
SG_MUL_VAL_ 1419 PDO_Mapping_Entry_1605_07 SubIndex_1605 7-7;
SG_MUL_VAL_ 1419 PDO_Mapping_Entry_1605_06 SubIndex_1605 6-6;
SG_MUL_VAL_ 1419 PDO_Mapping_Entry_1605_05 SubIndex_1605 5-5;
SG_MUL_VAL_ 1419 PDO_Mapping_Entry_1605_04 SubIndex_1605 4-4;
SG_MUL_VAL_ 1419 PDO_Mapping_Entry_1605_03 SubIndex_1605 3-3;
SG_MUL_VAL_ 1419 PDO_Mapping_Entry_1605_02 SubIndex_1605 2-2;
SG_MUL_VAL_ 1419 PDO_Mapping_Entry_1605_01 SubIndex_1605 1-1;
SG_MUL_VAL_ 1419 NrOfMappedObjects_1605_00 SubIndex_1605 0-0;
SG_MUL_VAL_ 1419 SubIndex_1605 Index 5637-5637;
SG_MUL_VAL_ 1419 PDO_Mapping_Entry_1604_08 SubIndex_1604 8-8;
SG_MUL_VAL_ 1419 PDO_Mapping_Entry_1604_07 SubIndex_1604 7-7;
SG_MUL_VAL_ 1419 PDO_Mapping_Entry_1604_06 SubIndex_1604 6-6;
SG_MUL_VAL_ 1419 PDO_Mapping_Entry_1604_05 SubIndex_1604 5-5;
SG_MUL_VAL_ 1419 PDO_Mapping_Entry_1604_04 SubIndex_1604 4-4;
SG_MUL_VAL_ 1419 PDO_Mapping_Entry_1604_03 SubIndex_1604 3-3;
SG_MUL_VAL_ 1419 PDO_Mapping_Entry_1604_02 SubIndex_1604 2-2;
SG_MUL_VAL_ 1419 PDO_Mapping_Entry_1604_01 SubIndex_1604 1-1;
SG_MUL_VAL_ 1419 NrOfMappedObjects_1604_00 SubIndex_1604 0-0;
SG_MUL_VAL_ 1419 SubIndex_1604 Index 5636-5636;
SG_MUL_VAL_ 1419 PDO_Mapping_Entry_1603_08 SubIndex_1603 8-8;
SG_MUL_VAL_ 1419 PDO_Mapping_Entry_1603_07 SubIndex_1603 7-7;
SG_MUL_VAL_ 1419 PDO_Mapping_Entry_1603_06 SubIndex_1603 6-6;
SG_MUL_VAL_ 1419 PDO_Mapping_Entry_1603_05 SubIndex_1603 5-5;
SG_MUL_VAL_ 1419 PDO_Mapping_Entry_1603_04 SubIndex_1603 4-4;
SG_MUL_VAL_ 1419 PDO_Mapping_Entry_1603_03 SubIndex_1603 3-3;
SG_MUL_VAL_ 1419 PDO_Mapping_Entry_1603_02 SubIndex_1603 2-2;
SG_MUL_VAL_ 1419 PDO_Mapping_Entry_1603_01 SubIndex_1603 1-1;
SG_MUL_VAL_ 1419 NrOfMappedObjects_1603_00 SubIndex_1603 0-0;
SG_MUL_VAL_ 1419 SubIndex_1603 Index 5635-5635;
SG_MUL_VAL_ 1419 PDO_Mapping_Entry_1602_08 SubIndex_1602 8-8;
SG_MUL_VAL_ 1419 PDO_Mapping_Entry_1602_07 SubIndex_1602 7-7;
SG_MUL_VAL_ 1419 PDO_Mapping_Entry_1602_06 SubIndex_1602 6-6;
SG_MUL_VAL_ 1419 PDO_Mapping_Entry_1602_05 SubIndex_1602 5-5;
SG_MUL_VAL_ 1419 PDO_Mapping_Entry_1602_04 SubIndex_1602 4-4;
SG_MUL_VAL_ 1419 PDO_Mapping_Entry_1602_03 SubIndex_1602 3-3;
SG_MUL_VAL_ 1419 PDO_Mapping_Entry_1602_02 SubIndex_1602 2-2;
SG_MUL_VAL_ 1419 PDO_Mapping_Entry_1602_01 SubIndex_1602 1-1;
SG_MUL_VAL_ 1419 NrOfMappedObjects_1602_00 SubIndex_1602 0-0;
SG_MUL_VAL_ 1419 SubIndex_1602 Index 5634-5634;
SG_MUL_VAL_ 1419 PDO_Mapping_Entry_1601_08 SubIndex_1601 8-8;
SG_MUL_VAL_ 1419 PDO_Mapping_Entry_1601_07 SubIndex_1601 7-7;
SG_MUL_VAL_ 1419 PDO_Mapping_Entry_1601_06 SubIndex_1601 6-6;
SG_MUL_VAL_ 1419 PDO_Mapping_Entry_1601_05 SubIndex_1601 5-5;
SG_MUL_VAL_ 1419 PDO_Mapping_Entry_1601_04 SubIndex_1601 4-4;
SG_MUL_VAL_ 1419 PDO_Mapping_Entry_1601_03 SubIndex_1601 3-3;
SG_MUL_VAL_ 1419 PDO_Mapping_Entry_1601_02 SubIndex_1601 2-2;
SG_MUL_VAL_ 1419 PDO_Mapping_Entry_1601_01 SubIndex_1601 1-1;
SG_MUL_VAL_ 1419 NrOfMappedObjects_1601_00 SubIndex_1601 0-0;
SG_MUL_VAL_ 1419 SubIndex_1601 Index 5633-5633;
SG_MUL_VAL_ 1419 PDO_Mapping_Entry_1600_08 SubIndex_1600 8-8;
SG_MUL_VAL_ 1419 PDO_Mapping_Entry_1600_07 SubIndex_1600 7-7;
SG_MUL_VAL_ 1419 PDO_Mapping_Entry_1600_06 SubIndex_1600 6-6;
SG_MUL_VAL_ 1419 PDO_Mapping_Entry_1600_05 SubIndex_1600 5-5;
SG_MUL_VAL_ 1419 PDO_Mapping_Entry_1600_04 SubIndex_1600 4-4;
SG_MUL_VAL_ 1419 PDO_Mapping_Entry_1600_03 SubIndex_1600 3-3;
SG_MUL_VAL_ 1419 mappedObj2_1600_02 SubIndex_1600 2-2;
SG_MUL_VAL_ 1419 mappedObj1_1600_01 SubIndex_1600 1-1;
SG_MUL_VAL_ 1419 NrOfMappedObjects_1600_00 SubIndex_1600 0-0;
SG_MUL_VAL_ 1419 SubIndex_1600 Index 5632-5632;
SG_MUL_VAL_ 1419 TransmissionType_1407_02 SubIndex_1407 2-2;
SG_MUL_VAL_ 1419 COB_ID_1407_01 SubIndex_1407 1-1;
SG_MUL_VAL_ 1419 NrOfEntries_1407_00 SubIndex_1407 0-0;
SG_MUL_VAL_ 1419 SubIndex_1407 Index 5127-5127;
SG_MUL_VAL_ 1419 TransmissionType_1406_02 SubIndex_1406 2-2;
SG_MUL_VAL_ 1419 COB_ID_1406_01 SubIndex_1406 1-1;
SG_MUL_VAL_ 1419 NrOfEntries_1406_00 SubIndex_1406 0-0;
SG_MUL_VAL_ 1419 SubIndex_1406 Index 5126-5126;
SG_MUL_VAL_ 1419 TransmissionType_1405_02 SubIndex_1405 2-2;
SG_MUL_VAL_ 1419 COB_ID_1405_01 SubIndex_1405 1-1;
SG_MUL_VAL_ 1419 NrOfEntries_1405_00 SubIndex_1405 0-0;
SG_MUL_VAL_ 1419 SubIndex_1405 Index 5125-5125;
SG_MUL_VAL_ 1419 TransmissionType_1404_02 SubIndex_1404 2-2;
SG_MUL_VAL_ 1419 COB_ID_1404_01 SubIndex_1404 1-1;
SG_MUL_VAL_ 1419 NrOfEntries_1404_00 SubIndex_1404 0-0;
SG_MUL_VAL_ 1419 SubIndex_1404 Index 5124-5124;
SG_MUL_VAL_ 1419 TransmissionType_1403_02 SubIndex_1403 2-2;
SG_MUL_VAL_ 1419 COB_ID_1403_01 SubIndex_1403 1-1;
SG_MUL_VAL_ 1419 NrOfEntries_1403_00 SubIndex_1403 0-0;
SG_MUL_VAL_ 1419 SubIndex_1403 Index 5123-5123;
SG_MUL_VAL_ 1419 TransmissionType_1402_02 SubIndex_1402 2-2;
SG_MUL_VAL_ 1419 COB_ID_1402_01 SubIndex_1402 1-1;
SG_MUL_VAL_ 1419 NrOfEntries_1402_00 SubIndex_1402 0-0;
SG_MUL_VAL_ 1419 SubIndex_1402 Index 5122-5122;
SG_MUL_VAL_ 1419 TransmissionType_1401_02 SubIndex_1401 2-2;
SG_MUL_VAL_ 1419 COB_ID_1401_01 SubIndex_1401 1-1;
SG_MUL_VAL_ 1419 NrOfEntries_1401_00 SubIndex_1401 0-0;
SG_MUL_VAL_ 1419 SubIndex_1401 Index 5121-5121;
SG_MUL_VAL_ 1419 TransmissionType_1400_02 SubIndex_1400 2-2;
SG_MUL_VAL_ 1419 COB_ID_1400_01 SubIndex_1400 1-1;
SG_MUL_VAL_ 1419 NrOfEntries_1400_00 SubIndex_1400 0-0;
SG_MUL_VAL_ 1419 SubIndex_1400 Index 5120-5120;
SG_MUL_VAL_ 1419 Serial_number_1018_04 SubIndex_1018 4-4;
SG_MUL_VAL_ 1419 Revision_number_1018_03 SubIndex_1018 3-3;
SG_MUL_VAL_ 1419 Product_Code_1018_02 SubIndex_1018 2-2;
SG_MUL_VAL_ 1419 Vendor_Id_1018_01 SubIndex_1018 1-1;
SG_MUL_VAL_ 1419 number_of_entries_1018_00 SubIndex_1018 0-0;
SG_MUL_VAL_ 1419 SubIndex_1018 Index 4120-4120;
SG_MUL_VAL_ 1419 Producer_Heartbeat_Time_1017 SubIndex_1017 0-0;
SG_MUL_VAL_ 1419 SubIndex_1017 Index 4119-4119;
SG_MUL_VAL_ 1419 Consumer_Heartbeat_Time_1016_09 SubIndex_1016 9-9;
SG_MUL_VAL_ 1419 Consumer_Heartbeat_Time_1016_08 SubIndex_1016 8-8;
SG_MUL_VAL_ 1419 Consumer_Heartbeat_Time_1016_07 SubIndex_1016 7-7;
SG_MUL_VAL_ 1419 Consumer_Heartbeat_Time_1016_06 SubIndex_1016 6-6;
SG_MUL_VAL_ 1419 Consumer_Heartbeat_Time_1016_05 SubIndex_1016 5-5;
SG_MUL_VAL_ 1419 Consumer_Heartbeat_Time_1016_04 SubIndex_1016 4-4;
SG_MUL_VAL_ 1419 Consumer_Heartbeat_Time_1016_03 SubIndex_1016 3-3;
SG_MUL_VAL_ 1419 Consumer_Heartbeat_Time_1016_02 SubIndex_1016 2-2;
SG_MUL_VAL_ 1419 Consumer_Heartbeat_Time_1016_01 SubIndex_1016 1-1;
SG_MUL_VAL_ 1419 NrOfObjects_1016_00 SubIndex_1016 0-0;
SG_MUL_VAL_ 1419 SubIndex_1016 Index 4118-4118;
SG_MUL_VAL_ 1419 Save_all_Parameters_1010_01 SubIndex_1010 1-1;
SG_MUL_VAL_ 1419 Number_of_Entries_1010_00 SubIndex_1010 0-0;
SG_MUL_VAL_ 1419 SubIndex_1010 Index 4112-4112;
SG_MUL_VAL_ 1419 Life_Time_Factor_100D SubIndex_100D 0-0;
SG_MUL_VAL_ 1419 SubIndex_100D Index 4109-4109;
SG_MUL_VAL_ 1419 Guard_Time_100C SubIndex_100C 0-0;
SG_MUL_VAL_ 1419 SubIndex_100C Index 4108-4108;
SG_MUL_VAL_ 1419 Sync_Window_Length_1007 SubIndex_1007 0-0;
SG_MUL_VAL_ 1419 SubIndex_1007 Index 4103-4103;
SG_MUL_VAL_ 1419 Communication_Cycle_Period_1006 SubIndex_1006 0-0;
SG_MUL_VAL_ 1419 SubIndex_1006 Index 4102-4102;
SG_MUL_VAL_ 1419 COB_ID_SYNC_1005 SubIndex_1005 0-0;
SG_MUL_VAL_ 1419 SubIndex_1005 Index 4101-4101;
SG_MUL_VAL_ 1419 Manufacturer_Status_Registe_0001 SubIndex_1002 0-0;
SG_MUL_VAL_ 1419 SubIndex_1002 Index 4098-4098;
SG_MUL_VAL_ 1419 Error_Register_1001 SubIndex_1001 0-0;
SG_MUL_VAL_ 1419 SubIndex_1001 Index 4097-4097;
SG_MUL_VAL_ 1419 Device_Type_1000 SubIndex_1000 0-0;
SG_MUL_VAL_ 1419 SubIndex_1000 Index 4096-4096;
SG_MUL_VAL_ 1419 Index TransferType 1-1;
SG_MUL_VAL_ 1419 TransferType SCS 1-2;
SG_MUL_VAL_ 1419 NotUsedBytes SCS 1-2;
SG_MUL_VAL_ 1419 SizeIndicator SCS 1-2;
SG_MUL_VAL_ 1547 supported_drive_modes_6502 SubIndex_6502 0-0;
SG_MUL_VAL_ 1547 SubIndex_6502 Index 25858-25858;
SG_MUL_VAL_ 1547 motor_service_period_6407 SubIndex_6407 0-0;
SG_MUL_VAL_ 1547 SubIndex_6407 Index 25607-25607;
SG_MUL_VAL_ 1547 motor_type_6402 SubIndex_6402 0-0;
SG_MUL_VAL_ 1547 SubIndex_6402 Index 25602-25602;
SG_MUL_VAL_ 1547 target_velocity_60FF SubIndex_60FF 0-0;
SG_MUL_VAL_ 1547 SubIndex_60FF Index 24831-24831;
SG_MUL_VAL_ 1547 bitmask_60FE_02 SubIndex_60FE 2-2;
SG_MUL_VAL_ 1547 physical_outputs_60FE_01 SubIndex_60FE 1-1;
SG_MUL_VAL_ 1547 NrOfObjects_60FE_00 SubIndex_60FE 0-0;
SG_MUL_VAL_ 1547 SubIndex_60FE Index 24830-24830;
SG_MUL_VAL_ 1547 digital_inputs_60FD SubIndex_60FD 0-0;
SG_MUL_VAL_ 1547 SubIndex_60FD Index 24829-24829;
SG_MUL_VAL_ 1547 polarity_607E SubIndex_607E 0-0;
SG_MUL_VAL_ 1547 SubIndex_607E Index 24702-24702;
SG_MUL_VAL_ 1547 target_position_607A SubIndex_607A 0-0;
SG_MUL_VAL_ 1547 SubIndex_607A Index 24698-24698;
SG_MUL_VAL_ 1547 torque_actual_value_6077 SubIndex_6077 0-0;
SG_MUL_VAL_ 1547 SubIndex_6077 Index 24695-24695;
SG_MUL_VAL_ 1547 target_torque_6071 SubIndex_6071 0-0;
SG_MUL_VAL_ 1547 SubIndex_6071 Index 24689-24689;
SG_MUL_VAL_ 1547 velocity_actual_value_606C SubIndex_606C 0-0;
SG_MUL_VAL_ 1547 SubIndex_606C Index 24684-24684;
SG_MUL_VAL_ 1547 position_window_6067 SubIndex_6067 0-0;
SG_MUL_VAL_ 1547 SubIndex_6067 Index 24679-24679;
SG_MUL_VAL_ 1547 position_actual_value_6064 SubIndex_6064 0-0;
SG_MUL_VAL_ 1547 SubIndex_6064 Index 24676-24676;
SG_MUL_VAL_ 1547 position_actual_value_6063 SubIndex_6063 0-0;
SG_MUL_VAL_ 1547 SubIndex_6063 Index 24675-24675;
SG_MUL_VAL_ 1547 position_demand_value_6062 SubIndex_6062 0-0;
SG_MUL_VAL_ 1547 SubIndex_6062 Index 24674-24674;
SG_MUL_VAL_ 1547 modes_of_operation_display_6061 SubIndex_6061 0-0;
SG_MUL_VAL_ 1547 SubIndex_6061 Index 24673-24673;
SG_MUL_VAL_ 1547 modes_of_operation_6060 SubIndex_6060 0-0;
SG_MUL_VAL_ 1547 SubIndex_6060 Index 24672-24672;
SG_MUL_VAL_ 1547 fault_reaction_option_code_605E SubIndex_605E 0-0;
SG_MUL_VAL_ 1547 SubIndex_605E Index 24670-24670;
SG_MUL_VAL_ 1547 stop_option_code_605D SubIndex_605D 0-0;
SG_MUL_VAL_ 1547 SubIndex_605D Index 24669-24669;
SG_MUL_VAL_ 1547 disable_operation_option_co_0000 SubIndex_605C 0-0;
SG_MUL_VAL_ 1547 SubIndex_605C Index 24668-24668;
SG_MUL_VAL_ 1547 shutdown_option_code_605B SubIndex_605B 0-0;
SG_MUL_VAL_ 1547 SubIndex_605B Index 24667-24667;
SG_MUL_VAL_ 1547 quick_stop_option_code_605A SubIndex_605A 0-0;
SG_MUL_VAL_ 1547 SubIndex_605A Index 24666-24666;
SG_MUL_VAL_ 1547 delta_time_6049_02 SubIndex_6049 2-2;
SG_MUL_VAL_ 1547 delta_speed_6049_01 SubIndex_6049 1-1;
SG_MUL_VAL_ 1547 NrOfObjects_6049_00 SubIndex_6049 0-0;
SG_MUL_VAL_ 1547 SubIndex_6049 Index 24649-24649;
SG_MUL_VAL_ 1547 delta_time_6048_02 SubIndex_6048 2-2;
SG_MUL_VAL_ 1547 delta_speed_6048_01 SubIndex_6048 1-1;
SG_MUL_VAL_ 1547 NrOfObjects_6048_00 SubIndex_6048 0-0;
SG_MUL_VAL_ 1547 SubIndex_6048 Index 24648-24648;
SG_MUL_VAL_ 1547 vl_velocity_max_amount_6046_02 SubIndex_6046 2-2;
SG_MUL_VAL_ 1547 vl_velocity_min_amount_6046_01 SubIndex_6046 1-1;
SG_MUL_VAL_ 1547 vl_velocity_min_max_amount__0000 SubIndex_6046 0-0;
SG_MUL_VAL_ 1547 SubIndex_6046 Index 24646-24646;
SG_MUL_VAL_ 1547 vl_control_effort_6044 SubIndex_6044 0-0;
SG_MUL_VAL_ 1547 SubIndex_6044 Index 24644-24644;
SG_MUL_VAL_ 1547 vl_velocity_demand_6043 SubIndex_6043 0-0;
SG_MUL_VAL_ 1547 SubIndex_6043 Index 24643-24643;
SG_MUL_VAL_ 1547 vl_target_velocity_6042 SubIndex_6042 0-0;
SG_MUL_VAL_ 1547 SubIndex_6042 Index 24642-24642;
SG_MUL_VAL_ 1547 statusword_6041 SubIndex_6041 0-0;
SG_MUL_VAL_ 1547 SubIndex_6041 Index 24641-24641;
SG_MUL_VAL_ 1547 controlword_6040 SubIndex_6040 0-0;
SG_MUL_VAL_ 1547 SubIndex_6040 Index 24640-24640;
SG_MUL_VAL_ 1547 error_code_603F SubIndex_603F 0-0;
SG_MUL_VAL_ 1547 SubIndex_603F Index 24639-24639;
SG_MUL_VAL_ 1547 abort_connection_option_cod_0000 SubIndex_6007 0-0;
SG_MUL_VAL_ 1547 SubIndex_6007 Index 24583-24583;
SG_MUL_VAL_ 1547 PDO_Mapping_Entry_1A06_08 SubIndex_1A06 8-8;
SG_MUL_VAL_ 1547 PDO_Mapping_Entry_1A06_07 SubIndex_1A06 7-7;
SG_MUL_VAL_ 1547 PDO_Mapping_Entry_1A06_06 SubIndex_1A06 6-6;
SG_MUL_VAL_ 1547 PDO_Mapping_Entry_1A06_05 SubIndex_1A06 5-5;
SG_MUL_VAL_ 1547 PDO_Mapping_Entry_1A06_04 SubIndex_1A06 4-4;
SG_MUL_VAL_ 1547 PDO_Mapping_Entry_1A06_03 SubIndex_1A06 3-3;
SG_MUL_VAL_ 1547 PDO_Mapping_Entry_1A06_02 SubIndex_1A06 2-2;
SG_MUL_VAL_ 1547 PDO_Mapping_Entry_1A06_01 SubIndex_1A06 1-1;
SG_MUL_VAL_ 1547 NrOfMappedObjects_1A06_00 SubIndex_1A06 0-0;
SG_MUL_VAL_ 1547 SubIndex_1A06 Index 6662-6662;
SG_MUL_VAL_ 1547 PDO_Mapping_Entry_1A05_08 SubIndex_1A05 8-8;
SG_MUL_VAL_ 1547 PDO_Mapping_Entry_1A05_07 SubIndex_1A05 7-7;
SG_MUL_VAL_ 1547 PDO_Mapping_Entry_1A05_06 SubIndex_1A05 6-6;
SG_MUL_VAL_ 1547 PDO_Mapping_Entry_1A05_05 SubIndex_1A05 5-5;
SG_MUL_VAL_ 1547 PDO_Mapping_Entry_1A05_04 SubIndex_1A05 4-4;
SG_MUL_VAL_ 1547 PDO_Mapping_Entry_1A05_03 SubIndex_1A05 3-3;
SG_MUL_VAL_ 1547 PDO_Mapping_Entry_1A05_02 SubIndex_1A05 2-2;
SG_MUL_VAL_ 1547 PDO_Mapping_Entry_1A05_01 SubIndex_1A05 1-1;
SG_MUL_VAL_ 1547 NrOfMappedObjects_1A05_00 SubIndex_1A05 0-0;
SG_MUL_VAL_ 1547 SubIndex_1A05 Index 6661-6661;
SG_MUL_VAL_ 1547 PDO_Mapping_Entry_1A04_08 SubIndex_1A04 8-8;
SG_MUL_VAL_ 1547 PDO_Mapping_Entry_1A04_07 SubIndex_1A04 7-7;
SG_MUL_VAL_ 1547 PDO_Mapping_Entry_1A04_06 SubIndex_1A04 6-6;
SG_MUL_VAL_ 1547 PDO_Mapping_Entry_1A04_05 SubIndex_1A04 5-5;
SG_MUL_VAL_ 1547 PDO_Mapping_Entry_1A04_04 SubIndex_1A04 4-4;
SG_MUL_VAL_ 1547 PDO_Mapping_Entry_1A04_03 SubIndex_1A04 3-3;
SG_MUL_VAL_ 1547 PDO_Mapping_Entry_1A04_02 SubIndex_1A04 2-2;
SG_MUL_VAL_ 1547 PDO_Mapping_Entry_1A04_01 SubIndex_1A04 1-1;
SG_MUL_VAL_ 1547 NrOfMappedObjects_1A04_00 SubIndex_1A04 0-0;
SG_MUL_VAL_ 1547 SubIndex_1A04 Index 6660-6660;
SG_MUL_VAL_ 1547 PDO_Mapping_Entry_1A03_08 SubIndex_1A03 8-8;
SG_MUL_VAL_ 1547 PDO_Mapping_Entry_1A03_07 SubIndex_1A03 7-7;
SG_MUL_VAL_ 1547 PDO_Mapping_Entry_1A03_06 SubIndex_1A03 6-6;
SG_MUL_VAL_ 1547 PDO_Mapping_Entry_1A03_05 SubIndex_1A03 5-5;
SG_MUL_VAL_ 1547 PDO_Mapping_Entry_1A03_04 SubIndex_1A03 4-4;
SG_MUL_VAL_ 1547 PDO_Mapping_Entry_1A03_03 SubIndex_1A03 3-3;
SG_MUL_VAL_ 1547 PDO_Mapping_Entry_1A03_02 SubIndex_1A03 2-2;
SG_MUL_VAL_ 1547 PDO_Mapping_Entry_1A03_01 SubIndex_1A03 1-1;
SG_MUL_VAL_ 1547 NrOfMappedObjects_1A03_00 SubIndex_1A03 0-0;
SG_MUL_VAL_ 1547 SubIndex_1A03 Index 6659-6659;
SG_MUL_VAL_ 1547 PDO_Mapping_Entry_1A02_08 SubIndex_1A02 8-8;
SG_MUL_VAL_ 1547 PDO_Mapping_Entry_1A02_07 SubIndex_1A02 7-7;
SG_MUL_VAL_ 1547 PDO_Mapping_Entry_1A02_06 SubIndex_1A02 6-6;
SG_MUL_VAL_ 1547 PDO_Mapping_Entry_1A02_05 SubIndex_1A02 5-5;
SG_MUL_VAL_ 1547 PDO_Mapping_Entry_1A02_04 SubIndex_1A02 4-4;
SG_MUL_VAL_ 1547 PDO_Mapping_Entry_1A02_03 SubIndex_1A02 3-3;
SG_MUL_VAL_ 1547 PDO_Mapping_Entry_1A02_02 SubIndex_1A02 2-2;
SG_MUL_VAL_ 1547 PDO_Mapping_Entry_1A02_01 SubIndex_1A02 1-1;
SG_MUL_VAL_ 1547 NrOfMappedObjects_1A02_00 SubIndex_1A02 0-0;
SG_MUL_VAL_ 1547 SubIndex_1A02 Index 6658-6658;
SG_MUL_VAL_ 1547 PDO_Mapping_Entry_1A01_08 SubIndex_1A01 8-8;
SG_MUL_VAL_ 1547 PDO_Mapping_Entry_1A01_07 SubIndex_1A01 7-7;
SG_MUL_VAL_ 1547 PDO_Mapping_Entry_1A01_06 SubIndex_1A01 6-6;
SG_MUL_VAL_ 1547 PDO_Mapping_Entry_1A01_05 SubIndex_1A01 5-5;
SG_MUL_VAL_ 1547 PDO_Mapping_Entry_1A01_04 SubIndex_1A01 4-4;
SG_MUL_VAL_ 1547 PDO_Mapping_Entry_1A01_03 SubIndex_1A01 3-3;
SG_MUL_VAL_ 1547 PDO_Mapping_Entry_1A01_02 SubIndex_1A01 2-2;
SG_MUL_VAL_ 1547 PDO_Mapping_Entry_1A01_01 SubIndex_1A01 1-1;
SG_MUL_VAL_ 1547 NrOfMappedObjects_1A01_00 SubIndex_1A01 0-0;
SG_MUL_VAL_ 1547 SubIndex_1A01 Index 6657-6657;
SG_MUL_VAL_ 1547 PDO_Mapping_Entry_1A00_08 SubIndex_1A00 8-8;
SG_MUL_VAL_ 1547 PDO_Mapping_Entry_1A00_07 SubIndex_1A00 7-7;
SG_MUL_VAL_ 1547 PDO_Mapping_Entry_1A00_06 SubIndex_1A00 6-6;
SG_MUL_VAL_ 1547 PDO_Mapping_Entry_1A00_05 SubIndex_1A00 5-5;
SG_MUL_VAL_ 1547 PDO_Mapping_Entry_1A00_04 SubIndex_1A00 4-4;
SG_MUL_VAL_ 1547 PDO_Mapping_Entry_1A00_03 SubIndex_1A00 3-3;
SG_MUL_VAL_ 1547 PDO_Mapping_Entry_1A00_02 SubIndex_1A00 2-2;
SG_MUL_VAL_ 1547 mappedObj1_1A00_01 SubIndex_1A00 1-1;
SG_MUL_VAL_ 1547 NrOfMappedObjects_1A00_00 SubIndex_1A00 0-0;
SG_MUL_VAL_ 1547 SubIndex_1A00 Index 6656-6656;
SG_MUL_VAL_ 1547 EventTimer_1806_05 SubIndex_1806 5-5;
SG_MUL_VAL_ 1547 TransmissionType_1806_02 SubIndex_1806 2-2;
SG_MUL_VAL_ 1547 COB_ID_1806_01 SubIndex_1806 1-1;
SG_MUL_VAL_ 1547 NrOfEntries_1806_00 SubIndex_1806 0-0;
SG_MUL_VAL_ 1547 SubIndex_1806 Index 6150-6150;
SG_MUL_VAL_ 1547 EventTimer_1805_05 SubIndex_1805 5-5;
SG_MUL_VAL_ 1547 TransmissionType_1805_02 SubIndex_1805 2-2;
SG_MUL_VAL_ 1547 COB_ID_1805_01 SubIndex_1805 1-1;
SG_MUL_VAL_ 1547 NrOfEntries_1805_00 SubIndex_1805 0-0;
SG_MUL_VAL_ 1547 SubIndex_1805 Index 6149-6149;
SG_MUL_VAL_ 1547 EventTimer_1804_05 SubIndex_1804 5-5;
SG_MUL_VAL_ 1547 TransmissionType_1804_02 SubIndex_1804 2-2;
SG_MUL_VAL_ 1547 COB_ID_1804_01 SubIndex_1804 1-1;
SG_MUL_VAL_ 1547 NrOfEntries_1804_00 SubIndex_1804 0-0;
SG_MUL_VAL_ 1547 SubIndex_1804 Index 6148-6148;
SG_MUL_VAL_ 1547 EventTimer_1803_05 SubIndex_1803 5-5;
SG_MUL_VAL_ 1547 TransmissionType_1803_02 SubIndex_1803 2-2;
SG_MUL_VAL_ 1547 COB_ID_1803_01 SubIndex_1803 1-1;
SG_MUL_VAL_ 1547 NrOfEntries_1803_00 SubIndex_1803 0-0;
SG_MUL_VAL_ 1547 SubIndex_1803 Index 6147-6147;
SG_MUL_VAL_ 1547 EventTimer_1802_05 SubIndex_1802 5-5;
SG_MUL_VAL_ 1547 TransmissionType_1802_02 SubIndex_1802 2-2;
SG_MUL_VAL_ 1547 COB_ID_1802_01 SubIndex_1802 1-1;
SG_MUL_VAL_ 1547 NrOfEntries_1802_00 SubIndex_1802 0-0;
SG_MUL_VAL_ 1547 SubIndex_1802 Index 6146-6146;
SG_MUL_VAL_ 1547 EventTimer_1801_05 SubIndex_1801 5-5;
SG_MUL_VAL_ 1547 TransmissionType_1801_02 SubIndex_1801 2-2;
SG_MUL_VAL_ 1547 COB_ID_1801_01 SubIndex_1801 1-1;
SG_MUL_VAL_ 1547 NrOfEntries_1801_00 SubIndex_1801 0-0;
SG_MUL_VAL_ 1547 SubIndex_1801 Index 6145-6145;
SG_MUL_VAL_ 1547 EventTimer_1800_05 SubIndex_1800 5-5;
SG_MUL_VAL_ 1547 TransmissionType_1800_02 SubIndex_1800 2-2;
SG_MUL_VAL_ 1547 COB_ID_1800_01 SubIndex_1800 1-1;
SG_MUL_VAL_ 1547 NrOfEntries_1800_00 SubIndex_1800 0-0;
SG_MUL_VAL_ 1547 SubIndex_1800 Index 6144-6144;
SG_MUL_VAL_ 1547 PDO_Mapping_Entry_1607_08 SubIndex_1607 8-8;
SG_MUL_VAL_ 1547 PDO_Mapping_Entry_1607_07 SubIndex_1607 7-7;
SG_MUL_VAL_ 1547 PDO_Mapping_Entry_1607_06 SubIndex_1607 6-6;
SG_MUL_VAL_ 1547 PDO_Mapping_Entry_1607_05 SubIndex_1607 5-5;
SG_MUL_VAL_ 1547 PDO_Mapping_Entry_1607_04 SubIndex_1607 4-4;
SG_MUL_VAL_ 1547 PDO_Mapping_Entry_1607_03 SubIndex_1607 3-3;
SG_MUL_VAL_ 1547 PDO_Mapping_Entry_1607_02 SubIndex_1607 2-2;
SG_MUL_VAL_ 1547 PDO_Mapping_Entry_1607_01 SubIndex_1607 1-1;
SG_MUL_VAL_ 1547 NrOfMappedObjects_1607_00 SubIndex_1607 0-0;
SG_MUL_VAL_ 1547 SubIndex_1607 Index 5639-5639;
SG_MUL_VAL_ 1547 PDO_Mapping_Entry_1606_08 SubIndex_1606 8-8;
SG_MUL_VAL_ 1547 PDO_Mapping_Entry_1606_07 SubIndex_1606 7-7;
SG_MUL_VAL_ 1547 PDO_Mapping_Entry_1606_06 SubIndex_1606 6-6;
SG_MUL_VAL_ 1547 PDO_Mapping_Entry_1606_05 SubIndex_1606 5-5;
SG_MUL_VAL_ 1547 PDO_Mapping_Entry_1606_04 SubIndex_1606 4-4;
SG_MUL_VAL_ 1547 PDO_Mapping_Entry_1606_03 SubIndex_1606 3-3;
SG_MUL_VAL_ 1547 PDO_Mapping_Entry_1606_02 SubIndex_1606 2-2;
SG_MUL_VAL_ 1547 PDO_Mapping_Entry_1606_01 SubIndex_1606 1-1;
SG_MUL_VAL_ 1547 NrOfMappedObjects_1606_00 SubIndex_1606 0-0;
SG_MUL_VAL_ 1547 SubIndex_1606 Index 5638-5638;
SG_MUL_VAL_ 1547 PDO_Mapping_Entry_1605_08 SubIndex_1605 8-8;
SG_MUL_VAL_ 1547 PDO_Mapping_Entry_1605_07 SubIndex_1605 7-7;
SG_MUL_VAL_ 1547 PDO_Mapping_Entry_1605_06 SubIndex_1605 6-6;
SG_MUL_VAL_ 1547 PDO_Mapping_Entry_1605_05 SubIndex_1605 5-5;
SG_MUL_VAL_ 1547 PDO_Mapping_Entry_1605_04 SubIndex_1605 4-4;
SG_MUL_VAL_ 1547 PDO_Mapping_Entry_1605_03 SubIndex_1605 3-3;
SG_MUL_VAL_ 1547 PDO_Mapping_Entry_1605_02 SubIndex_1605 2-2;
SG_MUL_VAL_ 1547 PDO_Mapping_Entry_1605_01 SubIndex_1605 1-1;
SG_MUL_VAL_ 1547 NrOfMappedObjects_1605_00 SubIndex_1605 0-0;
SG_MUL_VAL_ 1547 SubIndex_1605 Index 5637-5637;
SG_MUL_VAL_ 1547 PDO_Mapping_Entry_1604_08 SubIndex_1604 8-8;
SG_MUL_VAL_ 1547 PDO_Mapping_Entry_1604_07 SubIndex_1604 7-7;
SG_MUL_VAL_ 1547 PDO_Mapping_Entry_1604_06 SubIndex_1604 6-6;
SG_MUL_VAL_ 1547 PDO_Mapping_Entry_1604_05 SubIndex_1604 5-5;
SG_MUL_VAL_ 1547 PDO_Mapping_Entry_1604_04 SubIndex_1604 4-4;
SG_MUL_VAL_ 1547 PDO_Mapping_Entry_1604_03 SubIndex_1604 3-3;
SG_MUL_VAL_ 1547 PDO_Mapping_Entry_1604_02 SubIndex_1604 2-2;
SG_MUL_VAL_ 1547 PDO_Mapping_Entry_1604_01 SubIndex_1604 1-1;
SG_MUL_VAL_ 1547 NrOfMappedObjects_1604_00 SubIndex_1604 0-0;
SG_MUL_VAL_ 1547 SubIndex_1604 Index 5636-5636;
SG_MUL_VAL_ 1547 PDO_Mapping_Entry_1603_08 SubIndex_1603 8-8;
SG_MUL_VAL_ 1547 PDO_Mapping_Entry_1603_07 SubIndex_1603 7-7;
SG_MUL_VAL_ 1547 PDO_Mapping_Entry_1603_06 SubIndex_1603 6-6;
SG_MUL_VAL_ 1547 PDO_Mapping_Entry_1603_05 SubIndex_1603 5-5;
SG_MUL_VAL_ 1547 PDO_Mapping_Entry_1603_04 SubIndex_1603 4-4;
SG_MUL_VAL_ 1547 PDO_Mapping_Entry_1603_03 SubIndex_1603 3-3;
SG_MUL_VAL_ 1547 PDO_Mapping_Entry_1603_02 SubIndex_1603 2-2;
SG_MUL_VAL_ 1547 PDO_Mapping_Entry_1603_01 SubIndex_1603 1-1;
SG_MUL_VAL_ 1547 NrOfMappedObjects_1603_00 SubIndex_1603 0-0;
SG_MUL_VAL_ 1547 SubIndex_1603 Index 5635-5635;
SG_MUL_VAL_ 1547 PDO_Mapping_Entry_1602_08 SubIndex_1602 8-8;
SG_MUL_VAL_ 1547 PDO_Mapping_Entry_1602_07 SubIndex_1602 7-7;
SG_MUL_VAL_ 1547 PDO_Mapping_Entry_1602_06 SubIndex_1602 6-6;
SG_MUL_VAL_ 1547 PDO_Mapping_Entry_1602_05 SubIndex_1602 5-5;
SG_MUL_VAL_ 1547 PDO_Mapping_Entry_1602_04 SubIndex_1602 4-4;
SG_MUL_VAL_ 1547 PDO_Mapping_Entry_1602_03 SubIndex_1602 3-3;
SG_MUL_VAL_ 1547 PDO_Mapping_Entry_1602_02 SubIndex_1602 2-2;
SG_MUL_VAL_ 1547 PDO_Mapping_Entry_1602_01 SubIndex_1602 1-1;
SG_MUL_VAL_ 1547 NrOfMappedObjects_1602_00 SubIndex_1602 0-0;
SG_MUL_VAL_ 1547 SubIndex_1602 Index 5634-5634;
SG_MUL_VAL_ 1547 PDO_Mapping_Entry_1601_08 SubIndex_1601 8-8;
SG_MUL_VAL_ 1547 PDO_Mapping_Entry_1601_07 SubIndex_1601 7-7;
SG_MUL_VAL_ 1547 PDO_Mapping_Entry_1601_06 SubIndex_1601 6-6;
SG_MUL_VAL_ 1547 PDO_Mapping_Entry_1601_05 SubIndex_1601 5-5;
SG_MUL_VAL_ 1547 PDO_Mapping_Entry_1601_04 SubIndex_1601 4-4;
SG_MUL_VAL_ 1547 PDO_Mapping_Entry_1601_03 SubIndex_1601 3-3;
SG_MUL_VAL_ 1547 PDO_Mapping_Entry_1601_02 SubIndex_1601 2-2;
SG_MUL_VAL_ 1547 PDO_Mapping_Entry_1601_01 SubIndex_1601 1-1;
SG_MUL_VAL_ 1547 NrOfMappedObjects_1601_00 SubIndex_1601 0-0;
SG_MUL_VAL_ 1547 SubIndex_1601 Index 5633-5633;
SG_MUL_VAL_ 1547 PDO_Mapping_Entry_1600_08 SubIndex_1600 8-8;
SG_MUL_VAL_ 1547 PDO_Mapping_Entry_1600_07 SubIndex_1600 7-7;
SG_MUL_VAL_ 1547 PDO_Mapping_Entry_1600_06 SubIndex_1600 6-6;
SG_MUL_VAL_ 1547 PDO_Mapping_Entry_1600_05 SubIndex_1600 5-5;
SG_MUL_VAL_ 1547 PDO_Mapping_Entry_1600_04 SubIndex_1600 4-4;
SG_MUL_VAL_ 1547 PDO_Mapping_Entry_1600_03 SubIndex_1600 3-3;
SG_MUL_VAL_ 1547 mappedObj2_1600_02 SubIndex_1600 2-2;
SG_MUL_VAL_ 1547 mappedObj1_1600_01 SubIndex_1600 1-1;
SG_MUL_VAL_ 1547 NrOfMappedObjects_1600_00 SubIndex_1600 0-0;
SG_MUL_VAL_ 1547 SubIndex_1600 Index 5632-5632;
SG_MUL_VAL_ 1547 TransmissionType_1407_02 SubIndex_1407 2-2;
SG_MUL_VAL_ 1547 COB_ID_1407_01 SubIndex_1407 1-1;
SG_MUL_VAL_ 1547 NrOfEntries_1407_00 SubIndex_1407 0-0;
SG_MUL_VAL_ 1547 SubIndex_1407 Index 5127-5127;
SG_MUL_VAL_ 1547 TransmissionType_1406_02 SubIndex_1406 2-2;
SG_MUL_VAL_ 1547 COB_ID_1406_01 SubIndex_1406 1-1;
SG_MUL_VAL_ 1547 NrOfEntries_1406_00 SubIndex_1406 0-0;
SG_MUL_VAL_ 1547 SubIndex_1406 Index 5126-5126;
SG_MUL_VAL_ 1547 TransmissionType_1405_02 SubIndex_1405 2-2;
SG_MUL_VAL_ 1547 COB_ID_1405_01 SubIndex_1405 1-1;
SG_MUL_VAL_ 1547 NrOfEntries_1405_00 SubIndex_1405 0-0;
SG_MUL_VAL_ 1547 SubIndex_1405 Index 5125-5125;
SG_MUL_VAL_ 1547 TransmissionType_1404_02 SubIndex_1404 2-2;
SG_MUL_VAL_ 1547 COB_ID_1404_01 SubIndex_1404 1-1;
SG_MUL_VAL_ 1547 NrOfEntries_1404_00 SubIndex_1404 0-0;
SG_MUL_VAL_ 1547 SubIndex_1404 Index 5124-5124;
SG_MUL_VAL_ 1547 TransmissionType_1403_02 SubIndex_1403 2-2;
SG_MUL_VAL_ 1547 COB_ID_1403_01 SubIndex_1403 1-1;
SG_MUL_VAL_ 1547 NrOfEntries_1403_00 SubIndex_1403 0-0;
SG_MUL_VAL_ 1547 SubIndex_1403 Index 5123-5123;
SG_MUL_VAL_ 1547 TransmissionType_1402_02 SubIndex_1402 2-2;
SG_MUL_VAL_ 1547 COB_ID_1402_01 SubIndex_1402 1-1;
SG_MUL_VAL_ 1547 NrOfEntries_1402_00 SubIndex_1402 0-0;
SG_MUL_VAL_ 1547 SubIndex_1402 Index 5122-5122;
SG_MUL_VAL_ 1547 TransmissionType_1401_02 SubIndex_1401 2-2;
SG_MUL_VAL_ 1547 COB_ID_1401_01 SubIndex_1401 1-1;
SG_MUL_VAL_ 1547 NrOfEntries_1401_00 SubIndex_1401 0-0;
SG_MUL_VAL_ 1547 SubIndex_1401 Index 5121-5121;
SG_MUL_VAL_ 1547 TransmissionType_1400_02 SubIndex_1400 2-2;
SG_MUL_VAL_ 1547 COB_ID_1400_01 SubIndex_1400 1-1;
SG_MUL_VAL_ 1547 NrOfEntries_1400_00 SubIndex_1400 0-0;
SG_MUL_VAL_ 1547 SubIndex_1400 Index 5120-5120;
SG_MUL_VAL_ 1547 Serial_number_1018_04 SubIndex_1018 4-4;
SG_MUL_VAL_ 1547 Revision_number_1018_03 SubIndex_1018 3-3;
SG_MUL_VAL_ 1547 Product_Code_1018_02 SubIndex_1018 2-2;
SG_MUL_VAL_ 1547 Vendor_Id_1018_01 SubIndex_1018 1-1;
SG_MUL_VAL_ 1547 number_of_entries_1018_00 SubIndex_1018 0-0;
SG_MUL_VAL_ 1547 SubIndex_1018 Index 4120-4120;
SG_MUL_VAL_ 1547 Producer_Heartbeat_Time_1017 SubIndex_1017 0-0;
SG_MUL_VAL_ 1547 SubIndex_1017 Index 4119-4119;
SG_MUL_VAL_ 1547 Consumer_Heartbeat_Time_1016_09 SubIndex_1016 9-9;
SG_MUL_VAL_ 1547 Consumer_Heartbeat_Time_1016_08 SubIndex_1016 8-8;
SG_MUL_VAL_ 1547 Consumer_Heartbeat_Time_1016_07 SubIndex_1016 7-7;
SG_MUL_VAL_ 1547 Consumer_Heartbeat_Time_1016_06 SubIndex_1016 6-6;
SG_MUL_VAL_ 1547 Consumer_Heartbeat_Time_1016_05 SubIndex_1016 5-5;
SG_MUL_VAL_ 1547 Consumer_Heartbeat_Time_1016_04 SubIndex_1016 4-4;
SG_MUL_VAL_ 1547 Consumer_Heartbeat_Time_1016_03 SubIndex_1016 3-3;
SG_MUL_VAL_ 1547 Consumer_Heartbeat_Time_1016_02 SubIndex_1016 2-2;
SG_MUL_VAL_ 1547 Consumer_Heartbeat_Time_1016_01 SubIndex_1016 1-1;
SG_MUL_VAL_ 1547 NrOfObjects_1016_00 SubIndex_1016 0-0;
SG_MUL_VAL_ 1547 SubIndex_1016 Index 4118-4118;
SG_MUL_VAL_ 1547 Save_all_Parameters_1010_01 SubIndex_1010 1-1;
SG_MUL_VAL_ 1547 Number_of_Entries_1010_00 SubIndex_1010 0-0;
SG_MUL_VAL_ 1547 SubIndex_1010 Index 4112-4112;
SG_MUL_VAL_ 1547 Life_Time_Factor_100D SubIndex_100D 0-0;
SG_MUL_VAL_ 1547 SubIndex_100D Index 4109-4109;
SG_MUL_VAL_ 1547 Guard_Time_100C SubIndex_100C 0-0;
SG_MUL_VAL_ 1547 SubIndex_100C Index 4108-4108;
SG_MUL_VAL_ 1547 Sync_Window_Length_1007 SubIndex_1007 0-0;
SG_MUL_VAL_ 1547 SubIndex_1007 Index 4103-4103;
SG_MUL_VAL_ 1547 Communication_Cycle_Period_1006 SubIndex_1006 0-0;
SG_MUL_VAL_ 1547 SubIndex_1006 Index 4102-4102;
SG_MUL_VAL_ 1547 COB_ID_SYNC_1005 SubIndex_1005 0-0;
SG_MUL_VAL_ 1547 SubIndex_1005 Index 4101-4101;
SG_MUL_VAL_ 1547 Manufacturer_Status_Registe_0002 SubIndex_1002 0-0;
SG_MUL_VAL_ 1547 SubIndex_1002 Index 4098-4098;
SG_MUL_VAL_ 1547 Error_Register_1001 SubIndex_1001 0-0;
SG_MUL_VAL_ 1547 SubIndex_1001 Index 4097-4097;
SG_MUL_VAL_ 1547 Device_Type_1000 SubIndex_1000 0-0;
SG_MUL_VAL_ 1547 SubIndex_1000 Index 4096-4096;
SG_MUL_VAL_ 1547 Index TransferType 1-1;
SG_MUL_VAL_ 1547 TransferType CCS 1-2;
SG_MUL_VAL_ 1547 NotUsedBytes CCS 1-2;
SG_MUL_VAL_ 1547 SizeIndicator CCS 1-2;
SG_MUL_VAL_ 1418 DigOutput8_8_6200_08 SubIndex_6200 8-8;
SG_MUL_VAL_ 1418 DigOutput8_7_6200_07 SubIndex_6200 7-7;
SG_MUL_VAL_ 1418 DigOutput8_6_6200_06 SubIndex_6200 6-6;
SG_MUL_VAL_ 1418 DigOutput8_5_6200_05 SubIndex_6200 5-5;
SG_MUL_VAL_ 1418 DigOutput8_4_6200_04 SubIndex_6200 4-4;
SG_MUL_VAL_ 1418 DigOutput8_3_6200_03 SubIndex_6200 3-3;
SG_MUL_VAL_ 1418 DigOutput8_2_6200_02 SubIndex_6200 2-2;
SG_MUL_VAL_ 1418 LadderLock_6200_01 SubIndex_6200 1-1;
SG_MUL_VAL_ 1418 NrOfObjects_6200_00 SubIndex_6200 0-0;
SG_MUL_VAL_ 1418 SubIndex_6200 Index 25088-25088;
SG_MUL_VAL_ 1418 DigInput8_8_6000_08 SubIndex_6000 8-8;
SG_MUL_VAL_ 1418 DigInput8_7_6000_07 SubIndex_6000 7-7;
SG_MUL_VAL_ 1418 DigInput8_6_6000_06 SubIndex_6000 6-6;
SG_MUL_VAL_ 1418 DigInput8_5_6000_05 SubIndex_6000 5-5;
SG_MUL_VAL_ 1418 Support_Down_6000_04 SubIndex_6000 4-4;
SG_MUL_VAL_ 1418 Support_Up_6000_03 SubIndex_6000 3-3;
SG_MUL_VAL_ 1418 Ladder_Down_6000_02 SubIndex_6000 2-2;
SG_MUL_VAL_ 1418 Ladder_Up_6000_01 SubIndex_6000 1-1;
SG_MUL_VAL_ 1418 NrOfObjects_6000_00 SubIndex_6000 0-0;
SG_MUL_VAL_ 1418 SubIndex_6000 Index 24576-24576;
SG_MUL_VAL_ 1418 NrOfMappedObjects_1A01_00 SubIndex_1A01 0-0;
SG_MUL_VAL_ 1418 SubIndex_1A01 Index 6657-6657;
SG_MUL_VAL_ 1418 mappedObj5_1A00_05 SubIndex_1A00 5-5;
SG_MUL_VAL_ 1418 mappedObj4_1A00_04 SubIndex_1A00 4-4;
SG_MUL_VAL_ 1418 mappedObj3_1A00_03 SubIndex_1A00 3-3;
SG_MUL_VAL_ 1418 mappedObj2_1A00_02 SubIndex_1A00 2-2;
SG_MUL_VAL_ 1418 mappedObj1_1A00_01 SubIndex_1A00 1-1;
SG_MUL_VAL_ 1418 NrOfMappedObjects_1A00_00 SubIndex_1A00 0-0;
SG_MUL_VAL_ 1418 SubIndex_1A00 Index 6656-6656;
SG_MUL_VAL_ 1418 EventTimer_1801_05 SubIndex_1801 5-5;
SG_MUL_VAL_ 1418 TransmissionType_1801_02 SubIndex_1801 2-2;
SG_MUL_VAL_ 1418 COB_ID_1801_01 SubIndex_1801 1-1;
SG_MUL_VAL_ 1418 NrOfEntries_1801_00 SubIndex_1801 0-0;
SG_MUL_VAL_ 1418 SubIndex_1801 Index 6145-6145;
SG_MUL_VAL_ 1418 EventTimer_1800_05 SubIndex_1800 5-5;
SG_MUL_VAL_ 1418 TransmissionType_1800_02 SubIndex_1800 2-2;
SG_MUL_VAL_ 1418 COB_ID_1800_01 SubIndex_1800 1-1;
SG_MUL_VAL_ 1418 NrOfEntries_1800_00 SubIndex_1800 0-0;
SG_MUL_VAL_ 1418 SubIndex_1800 Index 6144-6144;
SG_MUL_VAL_ 1418 NrOfMappedObjects_1601_00 SubIndex_1601 0-0;
SG_MUL_VAL_ 1418 SubIndex_1601 Index 5633-5633;
SG_MUL_VAL_ 1418 NrOfMappedObjects_1600_00 SubIndex_1600 0-0;
SG_MUL_VAL_ 1418 SubIndex_1600 Index 5632-5632;
SG_MUL_VAL_ 1418 TransmissionType_1401_02 SubIndex_1401 2-2;
SG_MUL_VAL_ 1418 COB_ID_1401_01 SubIndex_1401 1-1;
SG_MUL_VAL_ 1418 NrOfEntries_1401_00 SubIndex_1401 0-0;
SG_MUL_VAL_ 1418 SubIndex_1401 Index 5121-5121;
SG_MUL_VAL_ 1418 TransmissionType_1400_02 SubIndex_1400 2-2;
SG_MUL_VAL_ 1418 COB_ID_1400_01 SubIndex_1400 1-1;
SG_MUL_VAL_ 1418 NrOfEntries_1400_00 SubIndex_1400 0-0;
SG_MUL_VAL_ 1418 SubIndex_1400 Index 5120-5120;
SG_MUL_VAL_ 1418 Serial_number_1018_04 SubIndex_1018 4-4;
SG_MUL_VAL_ 1418 Revision_number_1018_03 SubIndex_1018 3-3;
SG_MUL_VAL_ 1418 Product_Code_1018_02 SubIndex_1018 2-2;
SG_MUL_VAL_ 1418 Vendor_Id_1018_01 SubIndex_1018 1-1;
SG_MUL_VAL_ 1418 number_of_entries_1018_00 SubIndex_1018 0-0;
SG_MUL_VAL_ 1418 SubIndex_1018 Index 4120-4120;
SG_MUL_VAL_ 1418 Producer_Heartbeat_Time_1017 SubIndex_1017 0-0;
SG_MUL_VAL_ 1418 SubIndex_1017 Index 4119-4119;
SG_MUL_VAL_ 1418 Consumer_Heartbeat_Time_1016_06 SubIndex_1016 6-6;
SG_MUL_VAL_ 1418 Consumer_Heartbeat_Time_1016_05 SubIndex_1016 5-5;
SG_MUL_VAL_ 1418 Consumer_Heartbeat_Time_1016_04 SubIndex_1016 4-4;
SG_MUL_VAL_ 1418 Consumer_Heartbeat_Time_1016_03 SubIndex_1016 3-3;
SG_MUL_VAL_ 1418 Consumer_Heartbeat_Time_1016_02 SubIndex_1016 2-2;
SG_MUL_VAL_ 1418 Consumer_Heartbeat_Time_1016_01 SubIndex_1016 1-1;
SG_MUL_VAL_ 1418 NrOfObjects_1016_00 SubIndex_1016 0-0;
SG_MUL_VAL_ 1418 SubIndex_1016 Index 4118-4118;
SG_MUL_VAL_ 1418 Save_all_Parameters_1010_01 SubIndex_1010 1-1;
SG_MUL_VAL_ 1418 Number_of_Entries_1010_00 SubIndex_1010 0-0;
SG_MUL_VAL_ 1418 SubIndex_1010 Index 4112-4112;
SG_MUL_VAL_ 1418 Life_Time_Factor_100D SubIndex_100D 0-0;
SG_MUL_VAL_ 1418 SubIndex_100D Index 4109-4109;
SG_MUL_VAL_ 1418 Guard_Time_100C SubIndex_100C 0-0;
SG_MUL_VAL_ 1418 SubIndex_100C Index 4108-4108;
SG_MUL_VAL_ 1418 Sync_Window_Length_1007 SubIndex_1007 0-0;
SG_MUL_VAL_ 1418 SubIndex_1007 Index 4103-4103;
SG_MUL_VAL_ 1418 Communication_Cycle_Period_1006 SubIndex_1006 0-0;
SG_MUL_VAL_ 1418 SubIndex_1006 Index 4102-4102;
SG_MUL_VAL_ 1418 COB_ID_SYNC_1005 SubIndex_1005 0-0;
SG_MUL_VAL_ 1418 SubIndex_1005 Index 4101-4101;
SG_MUL_VAL_ 1418 Manufacturer_Status_Registe_0003 SubIndex_1002 0-0;
SG_MUL_VAL_ 1418 SubIndex_1002 Index 4098-4098;
SG_MUL_VAL_ 1418 Error_Register_1001 SubIndex_1001 0-0;
SG_MUL_VAL_ 1418 SubIndex_1001 Index 4097-4097;
SG_MUL_VAL_ 1418 Device_Type_1000 SubIndex_1000 0-0;
SG_MUL_VAL_ 1418 SubIndex_1000 Index 4096-4096;
SG_MUL_VAL_ 1418 Index TransferType 1-1;
SG_MUL_VAL_ 1418 TransferType SCS 1-2;
SG_MUL_VAL_ 1418 NotUsedBytes SCS 1-2;
SG_MUL_VAL_ 1418 SizeIndicator SCS 1-2;
SG_MUL_VAL_ 1546 DigOutput8_8_6200_08 SubIndex_6200 8-8;
SG_MUL_VAL_ 1546 DigOutput8_7_6200_07 SubIndex_6200 7-7;
SG_MUL_VAL_ 1546 DigOutput8_6_6200_06 SubIndex_6200 6-6;
SG_MUL_VAL_ 1546 DigOutput8_5_6200_05 SubIndex_6200 5-5;
SG_MUL_VAL_ 1546 DigOutput8_4_6200_04 SubIndex_6200 4-4;
SG_MUL_VAL_ 1546 DigOutput8_3_6200_03 SubIndex_6200 3-3;
SG_MUL_VAL_ 1546 DigOutput8_2_6200_02 SubIndex_6200 2-2;
SG_MUL_VAL_ 1546 LadderLock_6200_01 SubIndex_6200 1-1;
SG_MUL_VAL_ 1546 NrOfObjects_6200_00 SubIndex_6200 0-0;
SG_MUL_VAL_ 1546 SubIndex_6200 Index 25088-25088;
SG_MUL_VAL_ 1546 DigInput8_8_6000_08 SubIndex_6000 8-8;
SG_MUL_VAL_ 1546 DigInput8_7_6000_07 SubIndex_6000 7-7;
SG_MUL_VAL_ 1546 DigInput8_6_6000_06 SubIndex_6000 6-6;
SG_MUL_VAL_ 1546 DigInput8_5_6000_05 SubIndex_6000 5-5;
SG_MUL_VAL_ 1546 Support_Down_6000_04 SubIndex_6000 4-4;
SG_MUL_VAL_ 1546 Support_Up_6000_03 SubIndex_6000 3-3;
SG_MUL_VAL_ 1546 Ladder_Down_6000_02 SubIndex_6000 2-2;
SG_MUL_VAL_ 1546 Ladder_Up_6000_01 SubIndex_6000 1-1;
SG_MUL_VAL_ 1546 NrOfObjects_6000_00 SubIndex_6000 0-0;
SG_MUL_VAL_ 1546 SubIndex_6000 Index 24576-24576;
SG_MUL_VAL_ 1546 NrOfMappedObjects_1A01_00 SubIndex_1A01 0-0;
SG_MUL_VAL_ 1546 SubIndex_1A01 Index 6657-6657;
SG_MUL_VAL_ 1546 mappedObj5_1A00_05 SubIndex_1A00 5-5;
SG_MUL_VAL_ 1546 mappedObj4_1A00_04 SubIndex_1A00 4-4;
SG_MUL_VAL_ 1546 mappedObj3_1A00_03 SubIndex_1A00 3-3;
SG_MUL_VAL_ 1546 mappedObj2_1A00_02 SubIndex_1A00 2-2;
SG_MUL_VAL_ 1546 mappedObj1_1A00_01 SubIndex_1A00 1-1;
SG_MUL_VAL_ 1546 NrOfMappedObjects_1A00_00 SubIndex_1A00 0-0;
SG_MUL_VAL_ 1546 SubIndex_1A00 Index 6656-6656;
SG_MUL_VAL_ 1546 EventTimer_1801_05 SubIndex_1801 5-5;
SG_MUL_VAL_ 1546 TransmissionType_1801_02 SubIndex_1801 2-2;
SG_MUL_VAL_ 1546 COB_ID_1801_01 SubIndex_1801 1-1;
SG_MUL_VAL_ 1546 NrOfEntries_1801_00 SubIndex_1801 0-0;
SG_MUL_VAL_ 1546 SubIndex_1801 Index 6145-6145;
SG_MUL_VAL_ 1546 EventTimer_1800_05 SubIndex_1800 5-5;
SG_MUL_VAL_ 1546 TransmissionType_1800_02 SubIndex_1800 2-2;
SG_MUL_VAL_ 1546 COB_ID_1800_01 SubIndex_1800 1-1;
SG_MUL_VAL_ 1546 NrOfEntries_1800_00 SubIndex_1800 0-0;
SG_MUL_VAL_ 1546 SubIndex_1800 Index 6144-6144;
SG_MUL_VAL_ 1546 NrOfMappedObjects_1601_00 SubIndex_1601 0-0;
SG_MUL_VAL_ 1546 SubIndex_1601 Index 5633-5633;
SG_MUL_VAL_ 1546 NrOfMappedObjects_1600_00 SubIndex_1600 0-0;
SG_MUL_VAL_ 1546 SubIndex_1600 Index 5632-5632;
SG_MUL_VAL_ 1546 TransmissionType_1401_02 SubIndex_1401 2-2;
SG_MUL_VAL_ 1546 COB_ID_1401_01 SubIndex_1401 1-1;
SG_MUL_VAL_ 1546 NrOfEntries_1401_00 SubIndex_1401 0-0;
SG_MUL_VAL_ 1546 SubIndex_1401 Index 5121-5121;
SG_MUL_VAL_ 1546 TransmissionType_1400_02 SubIndex_1400 2-2;
SG_MUL_VAL_ 1546 COB_ID_1400_01 SubIndex_1400 1-1;
SG_MUL_VAL_ 1546 NrOfEntries_1400_00 SubIndex_1400 0-0;
SG_MUL_VAL_ 1546 SubIndex_1400 Index 5120-5120;
SG_MUL_VAL_ 1546 Serial_number_1018_04 SubIndex_1018 4-4;
SG_MUL_VAL_ 1546 Revision_number_1018_03 SubIndex_1018 3-3;
SG_MUL_VAL_ 1546 Product_Code_1018_02 SubIndex_1018 2-2;
SG_MUL_VAL_ 1546 Vendor_Id_1018_01 SubIndex_1018 1-1;
SG_MUL_VAL_ 1546 number_of_entries_1018_00 SubIndex_1018 0-0;
SG_MUL_VAL_ 1546 SubIndex_1018 Index 4120-4120;
SG_MUL_VAL_ 1546 Producer_Heartbeat_Time_1017 SubIndex_1017 0-0;
SG_MUL_VAL_ 1546 SubIndex_1017 Index 4119-4119;
SG_MUL_VAL_ 1546 Consumer_Heartbeat_Time_1016_06 SubIndex_1016 6-6;
SG_MUL_VAL_ 1546 Consumer_Heartbeat_Time_1016_05 SubIndex_1016 5-5;
SG_MUL_VAL_ 1546 Consumer_Heartbeat_Time_1016_04 SubIndex_1016 4-4;
SG_MUL_VAL_ 1546 Consumer_Heartbeat_Time_1016_03 SubIndex_1016 3-3;
SG_MUL_VAL_ 1546 Consumer_Heartbeat_Time_1016_02 SubIndex_1016 2-2;
SG_MUL_VAL_ 1546 Consumer_Heartbeat_Time_1016_01 SubIndex_1016 1-1;
SG_MUL_VAL_ 1546 NrOfObjects_1016_00 SubIndex_1016 0-0;
SG_MUL_VAL_ 1546 SubIndex_1016 Index 4118-4118;
SG_MUL_VAL_ 1546 Save_all_Parameters_1010_01 SubIndex_1010 1-1;
SG_MUL_VAL_ 1546 Number_of_Entries_1010_00 SubIndex_1010 0-0;
SG_MUL_VAL_ 1546 SubIndex_1010 Index 4112-4112;
SG_MUL_VAL_ 1546 Life_Time_Factor_100D SubIndex_100D 0-0;
SG_MUL_VAL_ 1546 SubIndex_100D Index 4109-4109;
SG_MUL_VAL_ 1546 Guard_Time_100C SubIndex_100C 0-0;
SG_MUL_VAL_ 1546 SubIndex_100C Index 4108-4108;
SG_MUL_VAL_ 1546 Sync_Window_Length_1007 SubIndex_1007 0-0;
SG_MUL_VAL_ 1546 SubIndex_1007 Index 4103-4103;
SG_MUL_VAL_ 1546 Communication_Cycle_Period_1006 SubIndex_1006 0-0;
SG_MUL_VAL_ 1546 SubIndex_1006 Index 4102-4102;
SG_MUL_VAL_ 1546 COB_ID_SYNC_1005 SubIndex_1005 0-0;
SG_MUL_VAL_ 1546 SubIndex_1005 Index 4101-4101;
SG_MUL_VAL_ 1546 Manufacturer_Status_Registe_0004 SubIndex_1002 0-0;
SG_MUL_VAL_ 1546 SubIndex_1002 Index 4098-4098;
SG_MUL_VAL_ 1546 Error_Register_1001 SubIndex_1001 0-0;
SG_MUL_VAL_ 1546 SubIndex_1001 Index 4097-4097;
SG_MUL_VAL_ 1546 Device_Type_1000 SubIndex_1000 0-0;
SG_MUL_VAL_ 1546 SubIndex_1000 Index 4096-4096;
SG_MUL_VAL_ 1546 Index TransferType 1-1;
SG_MUL_VAL_ 1546 TransferType CCS 1-2;
SG_MUL_VAL_ 1546 NotUsedBytes CCS 1-2;
SG_MUL_VAL_ 1546 SizeIndicator CCS 1-2;
